VERSION "dbc-export 1 2026.26.6.5"

NS_ :

BS_:

BU_: ADSP APB APP APS APSB BB BMS CC CMP CMPD CP DAS DI DIF DIR DPB EPAS3P EPAS3S EPASTP EPASTS EPBL EPBR ESP EVSE FC GTW HCML HCMR HVP IBST ICR IDB LS OCS1P PARK PCS PCS2 PM PMF PMR PNCD PTC RADC RCM RCM2 RCM3 RCU SCCM SCM SCS SDCR TAS TCU TCU2 TPMS TRCM UI UIS UMC USM V2G VC VCBATT VCBATT0 VCBATT1 VCBATT2 VCCC VCFRONT VCFRONT1 VCFRONT2 VCLEFT VCRIGHT VCSEAT2L VCSEAT2R VCSEC VEH

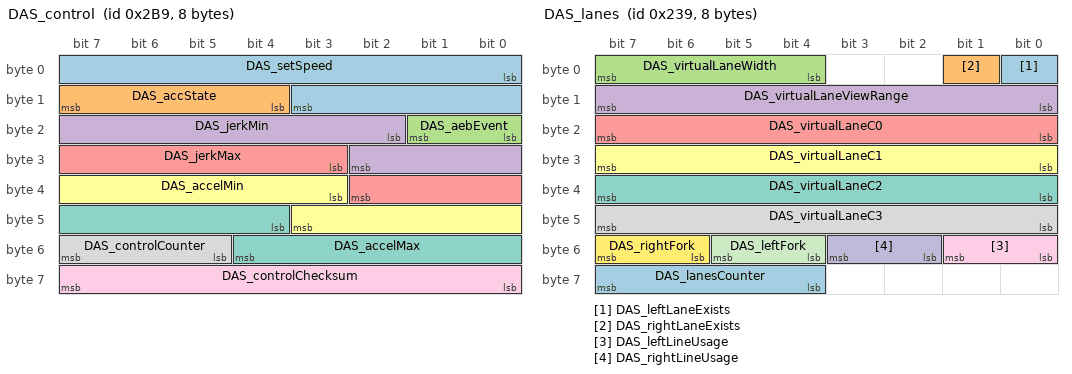
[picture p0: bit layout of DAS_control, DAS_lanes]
BO_ 697 DAS_control: 8 DAS
 SG_ DAS_setSpeed : 0|12@1+ (0.1,0) [0|409.4] "kph" Vector__XXX
 SG_ DAS_accState : 12|4@1+ (1,0) [0|15] "" Vector__XXX
 SG_ DAS_aebEvent : 16|2@1+ (1,0) [0|3] "" Vector__XXX
 SG_ DAS_jerkMin : 18|9@1+ (0.03,-15.232) [-15.232|0.098] "m/s^3" Vector__XXX
 SG_ DAS_jerkMax : 27|8@1+ (0.059,0) [0|15.045] "m/s^3" Vector__XXX
 SG_ DAS_accelMin : 35|9@1+ (0.04,-15) [-15|5.44] "m/s^2" Vector__XXX
 SG_ DAS_accelMax : 44|9@1+ (0.04,-15) [-15|5.44] "m/s^2" Vector__XXX
 SG_ DAS_controlCounter : 53|3@1+ (1,0) [0|7] "" Vector__XXX
 SG_ DAS_controlChecksum : 56|8@1+ (1,0) [0|255] "" Vector__XXX

BO_ 2040 DAS_gpsStatus: 8 DAS
 SG_ DAS_gpsStatusMultiplexer M : 0|4@1+ (1,0) [0|15] "" Vector__XXX
 SG_ DAS_gpsTransportModeState m0 : 4|1@1+ (1,0) [0|1] "" Vector__XXX
 SG_ DAS_gpsSatsInUseHardware m0 : 5|4@1+ (1,0) [0|15] "" Vector__XXX
 SG_ DAS_gpsRejectingSatData m0 : 57|1@1+ (1,0) [0|1] "" Vector__XXX
 SG_ DAS_gpsWheelsOffMotionDetected m0 : 58|1@1+ (1,0) [0|1] "" Vector__XXX
 SG_ DAS_gpsFixTypeHardware m0 : 59|3@1+ (1,0) [0|7] "" Vector__XXX
 SG_ DAS_gpsRawxEnabled m0 : 62|1@1+ (1,0) [0|1] "" Vector__XXX
 SG_ DAS_gpsRxmRawxMia m1 : 4|1@1+ (1,0) [0|1] "" Vector__XXX
 SG_ DAS_gpsRxmSfrbxMia m1 : 5|1@1+ (1,0) [0|1] "" Vector__XXX
 SG_ DAS_gpsEsfMeasMia m1 : 6|1@1+ (1,0) [0|1] "" Vector__XXX
 SG_ DAS_gpsEsfRawMia m1 : 7|1@1+ (1,0) [0|1] "" Vector__XXX
 SG_ DAS_gpsNavStatusMia m1 : 8|1@1+ (1,0) [0|1] "" Vector__XXX
 SG_ DAS_gpsSoftwareConfigured m1 : 9|1@1+ (1,0) [0|1] "" Vector__XXX
 SG_ DAS_gpsSoftwareUsed m1 : 10|1@1+ (1,0) [0|1] "" Vector__XXX
 SG_ DAS_gpsSoftwareFastStartReady m1 : 11|1@1+ (1,0) [0|1] "" Vector__XXX
 SG_ DAS_gpsSatsInUseSoftware m1 : 12|4@1+ (1,0) [0|15] "" Vector__XXX
 SG_ DAS_gpsFixTypeSoftware m1 : 16|3@1+ (1,0) [0|7] "" Vector__XXX
 SG_ DAS_gpsCWJammingInidcator m1 : 19|5@1+ (8,0) [0|248] "-" Vector__XXX
 SG_ DAS_gpsJammingState m1 : 24|2@1+ (1,0) [0|3] "" Vector__XXX
 SG_ DAS_gpsSpoofDetectorState m1 : 26|2@1+ (1,0) [0|3] "" Vector__XXX
 SG_ DAS_gpsInvalidMsgPercentage m1 : 28|4@1+ (6,0) [0|90] "%" Vector__XXX
 SG_ DAS_gnssConstellationsState m1 : 32|2@1+ (1,0) [0|3] "" Vector__XXX
 SG_ DAS_gpsReceiverNoiseLevel m1 : 34|6@1+ (8,0) [0|504] "-" Vector__XXX
 SG_ DAS_gpsAutomaticGainControl m1 : 40|8@1+ (32,0) [0|8160] "-" Vector__XXX
 SG_ DAS_gpsPreviousPositionDeltaHw m1 : 48|6@1+ (3,0) [0|189] "m" Vector__XXX
 SG_ DAS_gpsPreviousPositionDeltaSw m1 : 54|6@1+ (3,0) [0|189] "m" Vector__XXX
 SG_ DAS_gpsNmeaDispatchFailureCount m1 : 60|4@1+ (5,0) [0|75] "-" Vector__XXX
 SG_ DAS_gnssMaxInstantaneousCnorGps m2 : 4|6@1+ (1,0) [0|63] "" Vector__XXX
 SG_ DAS_gnssMaxInstantaneousCnorGal m2 : 10|6@1+ (1,0) [0|63] "" Vector__XXX
 SG_ DAS_gnssMaxInstantaneousCnorBds m2 : 16|6@1+ (1,0) [0|63] "" Vector__XXX
 SG_ DAS_gpsResetReason m2 : 22|4@1+ (1,0) [0|15] "" Vector__XXX
 SG_ DAS_gpsAccuracyHorizontal m2 : 26|6@1+ (1,0) [0|63] "m" Vector__XXX
 SG_ DAS_gpsAccuracyVertical m2 : 32|6@1+ (1,0) [0|63] "m" Vector__XXX
 SG_ DAS_gpsSolutionFallback m2 : 38|1@1+ (1,0) [0|1] "" Vector__XXX
 SG_ DAS_gpsToMcuSource m2 : 39|3@1+ (1,0) [0|7] "" Vector__XXX
 SG_ DAS_gpsSolutionSoc m2 : 42|2@1+ (1,0) [0|3] "" Vector__XXX
 SG_ DAS_gpsRedundancyActive m2 : 44|1@1+ (1,0) [0|1] "" Vector__XXX
 SG_ DAS_gpsFixTypeSoftwareSocB m2 : 45|3@1+ (1,0) [0|7] "" Vector__XXX
 SG_ DAS_gpsSatsInUseSoftwareSocB m2 : 48|4@1+ (1,0) [0|15] "" Vector__XXX
 SG_ DAS_gnssNumSatsGps m3 : 4|4@1+ (1,0) [0|15] "" Vector__XXX
 SG_ DAS_gnssNumSatsGal m3 : 8|4@1+ (1,0) [0|15] "" Vector__XXX
 SG_ DAS_gnssNumSatsBds m3 : 12|4@1+ (1,0) [0|15] "" Vector__XXX
 SG_ DAS_gnssAvgInstantaneousCnorGps m3 : 16|6@1+ (1,0) [0|63] "" Vector__XXX
 SG_ DAS_gnssAvgInstantaneousCnorGal m3 : 22|6@1+ (1,0) [0|63] "" Vector__XXX
 SG_ DAS_gnssAvgInstantaneousCnorBds m3 : 28|6@1+ (1,0) [0|63] "" Vector__XXX
 SG_ DAS_gnssAvgInstantaneousCnorGpsL m3 : 46|6@1+ (1,0) [0|63] "" Vector__XXX
 SG_ DAS_gnssAvgInstantaneousCnorGalL m3 : 52|6@1+ (1,0) [0|63] "" Vector__XXX
 SG_ DAS_gnssAvgInstantaneousCnorBdsL m3 : 58|6@1+ (1,0) [0|63] "" Vector__XXX

BO_ 1337 DAS_info: 8 DAS
 SG_ DAS_infoIndex M : 0|8@1+ (1,0) [0|255] "" Vector__XXX
 SG_ DAS_infoBuildType m10 : 8|8@1+ (1,0) [0|255] "" Vector__XXX
 SG_ DAS_infoBuildConfigID m10 : 16|16@1+ (1,0) [0|65535] "" Vector__XXX
 SG_ DAS_infoHardwareID m10 : 32|16@1+ (1,0) [0|65535] "" Vector__XXX
 SG_ DAS_infoComponentID m10 : 48|16@1+ (1,0) [0|65535] "" Vector__XXX
 SG_ DAS_infoPcbaID m11 : 16|8@1+ (1,0) [0|255] "" Vector__XXX
 SG_ DAS_infoAssemblyID m11 : 24|8@1+ (1,0) [0|255] "" Vector__XXX
 SG_ DAS_infoUsageID m11 : 32|16@1+ (1,0) [0|65535] "" Vector__XXX
 SG_ DAS_infoSubUsageID m11 : 48|16@1+ (1,0) [0|65535] "" Vector__XXX
 SG_ DAS_infoApplicationCRC m13 : 32|32@1+ (1,0) [0|4294967295] "" Vector__XXX
 SG_ DAS_infoAppGitHashBytes m17 : 8|56@1+ (1,0) [0|7.20575940379e+16] "" Vector__XXX
 SG_ DAS_infoBootGitHashBytes m18 : 8|56@1+ (1,0) [0|7.20575940379e+16] "" Vector__XXX

BO_ 569 DAS_lanes: 8 DAS
 SG_ DAS_leftLaneExists : 0|1@1+ (1,0) [0|1] "" Vector__XXX
 SG_ DAS_rightLaneExists : 1|1@1+ (1,0) [0|1] "" Vector__XXX
 SG_ DAS_virtualLaneWidth : 4|4@1+ (0.3125,2) [2|6.6875] "m" Vector__XXX
 SG_ DAS_virtualLaneViewRange : 8|8@1+ (1,0) [0|160] "m" Vector__XXX
 SG_ DAS_virtualLaneC0 : 16|8@1+ (0.035,-3.5) [-3.5|3.5] "m" Vector__XXX
 SG_ DAS_virtualLaneC1 : 24|8@1+ (0.0016,-0.2) [-0.2|0.2] "rad" Vector__XXX
 SG_ DAS_virtualLaneC2 : 32|8@1+ (2.0e-05,-0.0025) [-0.0025|0.0025] "m-1" Vector__XXX
 SG_ DAS_virtualLaneC3 : 40|8@1+ (2.4e-07,-3.0e-05) [-3.0e-05|3.0e-05] "m-2" Vector__XXX
 SG_ DAS_leftLineUsage : 48|2@1+ (1,0) [0|3] "" Vector__XXX
 SG_ DAS_rightLineUsage : 50|2@1+ (1,0) [0|3] "" Vector__XXX
 SG_ DAS_leftFork : 52|2@1+ (1,0) [0|3] "" Vector__XXX
 SG_ DAS_rightFork : 54|2@1+ (1,0) [0|3] "" Vector__XXX
 SG_ DAS_lanesCounter : 60|4@1+ (1,0) [0|15] "" Vector__XXX

BO_ 778 DAS_object: 8 DAS
 SG_ DAS_objectId M : 0|3@1+ (1,0) [0|7] "" Vector__XXX
 SG_ DAS_leadVehType m0 : 3|3@1+ (1,0) [0|7] "" Vector__XXX
 SG_ DAS_leadVehRelevantForControl m0 : 7|1@1+ (1,0) [0|1] "" Vector__XXX
 SG_ DAS_leadVehDx m0 : 8|8@1+ (0.5,0) [0|127] "m" Vector__XXX
 SG_ DAS_leadVehVxRel m0 : 16|4@1+ (4,-30) [-30|26] "m/s" Vector__XXX
 SG_ DAS_leadVehDy m0 : 20|7@1+ (0.35,-22.05) [-22.05|22.4] "m" Vector__XXX
 SG_ DAS_leadVehId m0 : 27|7@1+ (1,0) [0|127] "" Vector__XXX
 SG_ DAS_leadVeh2Type m0 : 34|3@1+ (1,0) [0|7] "" Vector__XXX
 SG_ DAS_leadVeh2RelevantForControl m0 : 38|1@1+ (1,0) [0|1] "" Vector__XXX
 SG_ DAS_leadVeh2Dx m0 : 39|8@1+ (0.5,0) [0|127] "m" Vector__XXX
 SG_ DAS_leadVeh2VxRel m0 : 47|4@1+ (4,-30) [-30|26] "m/s" Vector__XXX
 SG_ DAS_leadVeh2Dy m0 : 51|7@1+ (0.35,-22.05) [-22.05|22.4] "m" Vector__XXX
 SG_ DAS_leadVeh2Id m0 : 58|6@1+ (1,0) [0|63] "" Vector__XXX
 SG_ DAS_leftVehType m1 : 3|3@1+ (1,0) [0|7] "" Vector__XXX
 SG_ DAS_leftVehRelevantForControl m1 : 7|1@1+ (1,0) [0|1] "" Vector__XXX
 SG_ DAS_leftVehDx m1 : 8|8@1+ (0.5,0) [0|127] "m" Vector__XXX
 SG_ DAS_leftVehVxRel m1 : 16|4@1+ (4,-30) [-30|26] "m/s" Vector__XXX
 SG_ DAS_leftVehDy m1 : 20|7@1+ (0.35,-22.05) [-22.05|22.4] "m" Vector__XXX
 SG_ DAS_leftVehId m1 : 27|7@1+ (1,0) [0|127] "" Vector__XXX
 SG_ DAS_leftVeh2Type m1 : 34|3@1+ (1,0) [0|7] "" Vector__XXX
 SG_ DAS_leftVeh2RelevantForControl m1 : 38|1@1+ (1,0) [0|1] "" Vector__XXX
 SG_ DAS_leftVeh2Dx m1 : 39|8@1+ (0.5,0) [0|127] "m" Vector__XXX
 SG_ DAS_leftVeh2VxRel m1 : 47|4@1+ (4,-30) [-30|26] "m/s" Vector__XXX
 SG_ DAS_leftVeh2Dy m1 : 51|7@1+ (0.35,-22.05) [-22.05|22.4] "m" Vector__XXX
 SG_ DAS_leftVeh2Id m1 : 58|6@1+ (1,0) [0|63] "" Vector__XXX
 SG_ DAS_rightVehType m2 : 3|3@1+ (1,0) [0|7] "" Vector__XXX
 SG_ DAS_rightVehRelevantForControl m2 : 7|1@1+ (1,0) [0|1] "" Vector__XXX
 SG_ DAS_rightVehDx m2 : 8|8@1+ (0.5,0) [0|127] "m" Vector__XXX
 SG_ DAS_rightVehVxRel m2 : 16|4@1+ (4,-30) [-30|26] "m/s" Vector__XXX
 SG_ DAS_rightVehDy m2 : 20|7@1+ (0.35,-22.05) [-22.05|22.4] "m" Vector__XXX
 SG_ DAS_rightVehId m2 : 27|7@1+ (1,0) [0|127] "" Vector__XXX
 SG_ DAS_rightVeh2Type m2 : 34|3@1+ (1,0) [0|7] "" Vector__XXX
 SG_ DAS_rightVeh2RelevantForControl m2 : 38|1@1+ (1,0) [0|1] "" Vector__XXX
 SG_ DAS_rightVeh2Dx m2 : 39|8@1+ (0.5,0) [0|127] "m" Vector__XXX
 SG_ DAS_rightVeh2VxRel m2 : 47|4@1+ (4,-30) [-30|26] "m/s" Vector__XXX
 SG_ DAS_rightVeh2Dy m2 : 51|7@1+ (0.35,-22.05) [-22.05|22.4] "m" Vector__XXX
 SG_ DAS_rightVeh2Id m2 : 58|6@1+ (1,0) [0|63] "" Vector__XXX
 SG_ DAS_cutinVehType m3 : 3|3@1+ (1,0) [0|7] "" Vector__XXX
 SG_ DAS_cutinVehRelevantForControl m3 : 7|1@1+ (1,0) [0|1] "" Vector__XXX
 SG_ DAS_cutinVehDx m3 : 8|8@1+ (0.5,0) [0|127] "m" Vector__XXX
 SG_ DAS_cutinVehVxRel m3 : 16|4@1+ (4,-30) [-30|26] "m/s" Vector__XXX
 SG_ DAS_cutinVehDy m3 : 20|7@1+ (0.35,-22.05) [-22.05|22.4] "m" Vector__XXX
 SG_ DAS_cutinVehId m3 : 27|7@1+ (1,0) [0|127] "" Vector__XXX
 SG_ DAS_roadSignColor m4 : 3|3@1+ (1,0) [0|7] "" Vector__XXX
 SG_ DAS_roadSignId m4 : 6|8@1+ (1,0) [0|255] "" Vector__XXX
 SG_ DAS_roadSignStopLineDist m4 : 14|10@1+ (0.2,-20) [-20|184.4] "m" Vector__XXX
 SG_ DAS_roadSignControlActive m4 : 24|1@1+ (1,0) [0|1] "" Vector__XXX
 SG_ DAS_roadSignSource m4 : 25|2@1+ (1,0) [0|3] "" Vector__XXX
 SG_ DAS_roadSignArrow m4 : 27|3@1+ (1,0) [0|7] "" Vector__XXX
 SG_ DAS_roadSignOrientation m4 : 30|2@1+ (1,0) [0|3] "" Vector__XXX

BO_ 781 DAS_positioningEngineStatus: 8 DAS
 SG_ DAS_positioningEngineStatusMulti M : 0|4@1+ (1,0) [0|15] "" Vector__XXX
 SG_ DAS_meoSolverNumRuns m2 : 4|2@1+ (1,0) [0|3] "" Vector__XXX
 SG_ DAS_meoSolverReportTerminationTy m2 : 6|3@1+ (1,0) [0|7] "" Vector__XXX
 SG_ DAS_meoSolverReportTotalTimeS m2 : 9|3@1+ (1,0) [0|7] "" Vector__XXX
 SG_ DAS_meoHorizontalAccuracyM m2 : 12|6@1+ (1,0) [0|63] "m" Vector__XXX
 SG_ DAS_meoVerticalAccuracyM m2 : 18|6@1+ (1,0) [0|63] "m" Vector__XXX
 SG_ DAS_meoHeadingAccuracyDeg m2 : 24|3@1+ (1,0) [0|7] "deg" Vector__XXX
 SG_ DAS_meoHeadingValid m2 : 27|1@1+ (1,0) [0|1] "" Vector__XXX
 SG_ DAS_meoNumSatellitesUsed m2 : 28|5@1+ (1,0) [0|31] "" Vector__XXX
 SG_ DAS_meoGpsQualityLevel m2 : 33|3@1+ (1,0) [0|7] "" Vector__XXX
 SG_ DAS_meoFixType m2 : 36|3@1+ (1,0) [0|7] "" Vector__XXX
 SG_ DAS_meoResetCount m2 : 39|3@1+ (1,0) [0|7] "" Vector__XXX
 SG_ DAS_lastMeoResetReason m2 : 42|2@1+ (1,0) [0|3] "" Vector__XXX
 SG_ DAS_vioMultiGpsSelectedSource m3 : 4|3@1+ (1,0) [0|7] "" Vector__XXX
 SG_ DAS_vioMultiGpsPeCooldownActive m3 : 7|1@1+ (1,0) [0|1] "" Vector__XXX
 SG_ DAS_vioMultiGpsPeSppTdcpConsiste m3 : 8|1@1+ (1,0) [0|1] "" Vector__XXX
 SG_ DAS_vioMultiGpsPeMeoConsistentWi m3 : 9|1@1+ (1,0) [0|1] "" Vector__XXX
 SG_ DAS_vioMultiGpsPeSppTdcpVsR_0001 m3 : 10|4@1+ (1,0) [0|15] "m" Vector__XXX
 SG_ DAS_vioMultiGpsPeMeoVsRawGpsTran m3 : 14|4@1+ (1,0) [0|15] "m" Vector__XXX
 SG_ DAS_vioMultiGpsPeSppTdcpVsRawGps m3 : 18|3@1+ (1,0) [0|7] "deg" Vector__XXX
 SG_ DAS_vioMultiGpsPeMeoVsRawGpsRotD m3 : 21|3@1+ (1,0) [0|7] "deg" Vector__XXX
 SG_ DAS_publishedGpsSource m3 : 24|2@1+ (1,0) [0|3] "" Vector__XXX
 SG_ DAS_bluefinEnabled m3 : 26|1@1+ (1,0) [0|1] "" Vector__XXX
 SG_ DAS_orioleDisabled m3 : 27|1@1+ (1,0) [0|1] "" Vector__XXX
 SG_ DAS_disableMonarch m3 : 28|1@1+ (1,0) [0|1] "" Vector__XXX

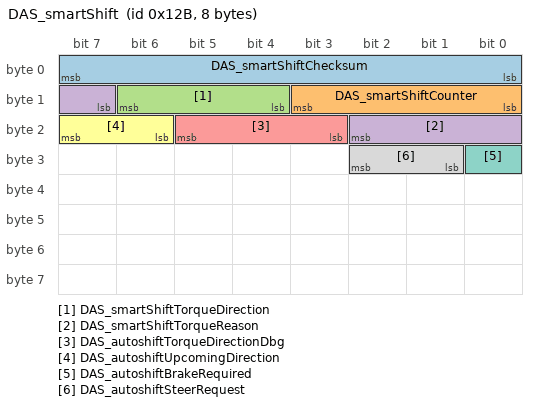
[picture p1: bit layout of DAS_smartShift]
BO_ 299 DAS_smartShift: 8 DAS
 SG_ DAS_smartShiftChecksum : 0|8@1+ (1,0) [0|255] "" Vector__XXX
 SG_ DAS_smartShiftCounter : 8|4@1+ (1,0) [0|15] "" Vector__XXX
 SG_ DAS_smartShiftTorqueDirection : 12|3@1+ (1,0) [0|7] "" Vector__XXX
 SG_ DAS_smartShiftTorqueReason : 15|4@1+ (1,0) [0|15] "" Vector__XXX
 SG_ DAS_autoshiftTorqueDirectionDbg : 19|3@1+ (1,0) [0|7] "" Vector__XXX
 SG_ DAS_autoshiftUpcomingDirection : 22|2@1+ (1,0) [0|3] "" Vector__XXX
 SG_ DAS_autoshiftBrakeRequired : 24|1@1+ (1,0) [0|1] "" Vector__XXX
 SG_ DAS_autoshiftSteerRequest : 25|2@1+ (1,0) [0|3] "" Vector__XXX

BO_ 921 DAS_status: 8 DAS
 SG_ DAS_autopilotState : 0|4@1+ (1,0) [0|15] "" Vector__XXX
 SG_ DAS_blindSpotRearLeft : 4|2@1+ (1,0) [0|3] "" Vector__XXX
 SG_ DAS_blindSpotRearRight : 6|2@1+ (1,0) [0|3] "" Vector__XXX
 SG_ DAS_fusedSpeedLimit : 8|5@1+ (5,0) [0|150] "kph/mph" Vector__XXX
 SG_ DAS_suppressSpeedWarning : 13|1@1+ (1,0) [0|1] "" Vector__XXX
 SG_ DAS_summonObstacle : 14|1@1+ (1,0) [0|1] "" Vector__XXX
 SG_ DAS_summonClearedGate : 15|1@1+ (1,0) [0|1] "" Vector__XXX
 SG_ DAS_visionOnlySpeedLimit : 16|5@1+ (5,0) [0|150] "kph/mph" Vector__XXX
 SG_ DAS_heaterState : 21|1@1+ (1,0) [0|1] "" Vector__XXX
 SG_ DAS_forwardCollisionWarning : 22|2@1+ (1,0) [0|3] "" Vector__XXX
 SG_ DAS_autoparkReady : 24|1@1+ (1,0) [0|1] "" Vector__XXX
 SG_ DAS_autoParked : 25|1@1+ (1,0) [0|1] "" Vector__XXX
 SG_ DAS_autoparkActive : 26|1@1+ (1,0) [0|1] "" Vector__XXX
 SG_ DAS_summonFwdLeashReached : 27|1@1+ (1,0) [0|1] "" Vector__XXX
 SG_ DAS_summonRvsLeashReached : 28|1@1+ (1,0) [0|1] "" Vector__XXX
 SG_ DAS_lssState : 29|3@1+ (1,0) [0|7] "" Vector__XXX
 SG_ DAS_sideCollisionAvoid : 32|2@1+ (1,0) [0|3] "" Vector__XXX
 SG_ DAS_sideCollisionWarning : 34|2@1+ (1,0) [0|3] "" Vector__XXX
 SG_ DAS_sideCollisionInhibit : 36|1@1+ (1,0) [0|1] "" Vector__XXX
 SG_ DAS_laneDepartureWarning : 37|3@1+ (1,0) [0|7] "" Vector__XXX
 SG_ DAS_fleetSpeedState : 40|2@1+ (1,0) [0|3] "" Vector__XXX
 SG_ DAS_autopilotHandsOnState : 42|4@1+ (1,0) [0|15] "" Vector__XXX
 SG_ DAS_autoLaneChangeState : 46|5@1+ (1,0) [0|31] "" Vector__XXX
 SG_ DAS_summonAvailable : 51|1@1+ (1,0) [0|1] "" Vector__XXX
 SG_ DAS_statusCounter : 52|4@1+ (1,0) [0|15] "" Vector__XXX
 SG_ DAS_statusChecksum : 56|8@1+ (1,0) [0|255] "" Vector__XXX

BO_ 905 DAS_status2: 8 DAS
 SG_ DAS_accSpeedLimit : 0|9@1+ (0.4,0) [0|200] "mph" Vector__XXX
 SG_ DAS_versionIdentifier : 9|1@1+ (1,0) [0|1] "" Vector__XXX
 SG_ DAS_pmmObstacleSeverity : 10|3@1+ (1,0) [0|7] "" Vector__XXX
 SG_ DAS_pmmLoggingRequest : 13|1@1+ (1,0) [0|1] "" Vector__XXX
 SG_ DAS_activationFailureStatus : 14|2@1+ (1,0) [0|3] "" Vector__XXX
 SG_ DAS_pmmUltrasonicsFaultReason : 16|3@1+ (1,0) [0|7] "" Vector__XXX
 SG_ DAS_pmmRadarFaultReason : 19|2@1+ (1,0) [0|3] "" Vector__XXX
 SG_ DAS_pmmSysFaultReason : 21|3@1+ (1,0) [0|7] "" Vector__XXX
 SG_ DAS_pmmCameraFaultReason : 24|2@1+ (1,0) [0|3] "" Vector__XXX
 SG_ DAS_ACC_report : 26|5@1+ (1,0) [0|31] "" Vector__XXX
 SG_ DAS_relaxCruiseLimits : 31|1@1+ (1,0) [0|1] "" Vector__XXX
 SG_ DAS_csaState : 32|2@1+ (1,0) [0|3] "" Vector__XXX
 SG_ DAS_radarTelemetry : 34|2@1+ (1,0) [0|3] "" Vector__XXX
 SG_ DAS_robState : 36|2@1+ (1,0) [0|3] "" Vector__XXX
 SG_ DAS_driverInteractionLevel : 38|2@1+ (1,0) [0|3] "" Vector__XXX
 SG_ DAS_ppOffsetDesiredRamp : 40|8@1+ (0.01,-1.28) [-1.28|1.27] "m" Vector__XXX
 SG_ DAS_longCollisionWarning : 48|4@1+ (1,0) [0|15] "" Vector__XXX
 SG_ DAS_status2Counter : 52|4@1+ (1,0) [0|15] "" Vector__XXX
 SG_ DAS_status2Checksum : 56|8@1+ (1,0) [0|255] "" Vector__XXX

BO_ 1548 DAS_telemetryRadar: 8 DAS
 SG_ DAS_TR_ObjIndex M : 0|5@1+ (1,0) [0|31] "" Vector__XXX
 SG_ DAS_TR_Counter : 54|2@1+ (1,0) [0|3] "" Vector__XXX
 SG_ DAS_TR_Obj00_Class m0 : 5|3@1+ (1,0) [0|7] "" Vector__XXX
 SG_ DAS_TR_Obj00_Dx m0 : 8|10@1+ (0.15625,0) [0|159.84375] "m" Vector__XXX
 SG_ DAS_TR_Obj00_Dy m0 : 18|6@1+ (0.5,-15.5) [-15.5|16] "m" Vector__XXX
 SG_ DAS_TR_Obj00_Vx m0 : 24|8@1+ (0.5,-63.5) [-63.5|64] "m/s" Vector__XXX
 SG_ DAS_TR_Obj00_RCS m0 : 32|8@1+ (0.25,-14) [-14|49.75] "dB" Vector__XXX
 SG_ DAS_TR_Obj00_Length m0 : 40|6@1+ (0.125,0) [0|7.875] "m" Vector__XXX
 SG_ DAS_TR_Obj00_MovingState m0 : 46|2@1+ (1,0) [0|3] "" Vector__XXX
 SG_ DAS_TR_Obj00_Dz m0 : 48|6@1+ (0.25,-5) [-5|10.75] "m" Vector__XXX
 SG_ DAS_TR_Obj00_Exist m0 : 56|5@1+ (3.125,0) [0|96.875] "%" Vector__XXX

BO_ 586 DAS_visualDebug: 8 DAS
 SG_ DAS_autosteerVehiclesUsage : 4|2@1+ (1,0) [0|3] "" Vector__XXX
 SG_ DAS_autosteerHPPUsage : 6|2@1+ (1,0) [0|3] "" Vector__XXX
 SG_ DAS_autosteerNavigationUsage : 8|2@1+ (1,0) [0|3] "" Vector__XXX
 SG_ DAS_autosteerModelUsage : 10|2@1+ (1,0) [0|3] "" Vector__XXX
 SG_ DAS_autosteerBottsDotsUsage : 12|2@1+ (1,0) [0|3] "" Vector__XXX
 SG_ DAS_offsetSide : 14|2@1+ (1,0) [0|3] "" Vector__XXX
 SG_ DAS_roadSurfaceType : 16|2@1+ (1,0) [0|3] "" Vector__XXX
 SG_ DAS_autosteerHealthAnomalyLevel : 18|3@1+ (1,0) [0|7] "" Vector__XXX
 SG_ DAS_autosteerHealthState : 21|3@1+ (1,0) [0|7] "" Vector__XXX
 SG_ DAS_lastLinePreferenceReason : 24|4@1+ (1,0) [0|15] "" Vector__XXX
 SG_ DAS_plannerState : 28|4@1+ (1,0) [0|15] "" Vector__XXX
 SG_ DAS_lastAutosteerAbortReason : 32|6@1+ (1,0) [0|63] "" Vector__XXX
 SG_ DAS_devAppInterfaceEnabled : 38|1@1+ (1,0) [0|1] "" Vector__XXX
 SG_ DAS_navAvailable : 39|1@1+ (1,0) [0|1] "" Vector__XXX
 SG_ DAS_navDistance : 40|8@1+ (100,0) [0|25500] "km" Vector__XXX
 SG_ DAS_accSmartSpeedActive : 48|1@1+ (1,0) [0|1] "" Vector__XXX
 SG_ DAS_accSmartSpeedState : 49|3@1+ (1,0) [0|7] "" Vector__XXX
 SG_ DAS_ulcInProgress : 52|1@1+ (1,0) [0|1] "" Vector__XXX
 SG_ DAS_trafficAwareSetSpeedInUse : 53|1@1+ (1,0) [0|1] "" Vector__XXX
 SG_ DAS_isaSystemState : 54|2@1+ (1,0) [0|3] "" Vector__XXX
 SG_ DAS_behaviorType : 56|2@1+ (1,0) [0|3] "" Vector__XXX
 SG_ DAS_ulcType : 58|2@1+ (1,0) [0|3] "" Vector__XXX
 SG_ DAS_rearVehDetectedThisCycle : 60|1@1+ (1,0) [0|1] "" Vector__XXX
 SG_ DAS_rearLeftVehDetectedCurrent : 61|1@1+ (1,0) [0|1] "" Vector__XXX
 SG_ DAS_rearRightVehDetectedTrip : 62|1@1+ (1,0) [0|1] "" Vector__XXX
 SG_ DAS_rearLeftVehDetectedTrip : 63|1@1+ (1,0) [0|1] "" Vector__XXX

BO_ 2039 DAS_warningMatrix0: 8 DAS
 SG_ DAS_w002_ldwDisabled : 1|1@1+ (1,0) [0|1] "" Vector__XXX
 SG_ DAS_w003_isaDisabled : 2|1@1+ (1,0) [0|1] "" Vector__XXX
 SG_ DAS_w004_accDisabled : 3|1@1+ (1,0) [0|1] "" Vector__XXX
 SG_ DAS_w005_fcwCancelled : 4|1@1+ (1,0) [0|1] "" Vector__XXX
 SG_ DAS_w006_aebCancelled : 5|1@1+ (1,0) [0|1] "" Vector__XXX
 SG_ DAS_w007_ahlbDisabled : 6|1@1+ (1,0) [0|1] "" Vector__XXX
 SG_ DAS_w008_parkDisabled : 7|1@1+ (1,0) [0|1] "" Vector__XXX
 SG_ DAS_w009_aebFault : 8|1@1+ (1,0) [0|1] "" Vector__XXX
 SG_ DAS_w010_radcCalibIssue : 9|1@1+ (1,0) [0|1] "" Vector__XXX
 SG_ DAS_w011_scaEvent : 10|1@1+ (1,0) [0|1] "" Vector__XXX
 SG_ DAS_w012_Cam_BootFailure : 11|1@1+ (1,0) [0|1] "" Vector__XXX
 SG_ DAS_w013_Cam_Watchdog : 12|1@1+ (1,0) [0|1] "" Vector__XXX
 SG_ DAS_w014_swAssert : 13|1@1+ (1,0) [0|1] "" Vector__XXX
 SG_ DAS_w015_Camera_Failsafes : 14|1@1+ (1,0) [0|1] "" Vector__XXX
 SG_ DAS_w016_aeb_e_event : 15|1@1+ (1,0) [0|1] "" Vector__XXX
 SG_ DAS_w017_Cam_Msg_MIA : 16|1@1+ (1,0) [0|1] "" Vector__XXX
 SG_ DAS_w018_ECU_Power_Issue : 17|1@1+ (1,0) [0|1] "" Vector__XXX
 SG_ DAS_w019_ECU_Stack_Overflow : 18|1@1+ (1,0) [0|1] "" Vector__XXX
 SG_ DAS_w020_ECU_checkstopError : 19|1@1+ (1,0) [0|1] "" Vector__XXX
 SG_ DAS_w021_ECU_Temperature_Issue : 20|1@1+ (1,0) [0|1] "" Vector__XXX
 SG_ DAS_w022_ECU_EEPROM_Failure : 21|1@1+ (1,0) [0|1] "" Vector__XXX
 SG_ DAS_w023_ECU_Cam_Statemismatc : 22|1@1+ (1,0) [0|1] "" Vector__XXX
 SG_ DAS_w024_ECU_Watchdog_Reset : 23|1@1+ (1,0) [0|1] "" Vector__XXX
 SG_ DAS_w025_LC_Steering_Override : 24|1@1+ (1,0) [0|1] "" Vector__XXX
 SG_ DAS_w026_ECU_timingIssue : 25|1@1+ (1,0) [0|1] "" Vector__XXX
 SG_ DAS_w027_ECU_Reset_Fault : 26|1@1+ (1,0) [0|1] "" Vector__XXX
 SG_ DAS_w028_spi_rx_error : 27|1@1+ (1,0) [0|1] "" Vector__XXX
 SG_ DAS_w029_spi_tx_error : 28|1@1+ (1,0) [0|1] "" Vector__XXX
 SG_ DAS_w030_Heater_Issue : 29|1@1+ (1,0) [0|1] "" Vector__XXX
 SG_ DAS_w031_canRxError : 30|1@1+ (1,0) [0|1] "" Vector__XXX
 SG_ DAS_w032_canTxError : 31|1@1+ (1,0) [0|1] "" Vector__XXX
 SG_ DAS_w033_gtwMia : 32|1@1+ (1,0) [0|1] "" Vector__XXX
 SG_ DAS_w034_sccmMia : 33|1@1+ (1,0) [0|1] "" Vector__XXX
 SG_ DAS_w035_espMia : 34|1@1+ (1,0) [0|1] "" Vector__XXX
 SG_ DAS_w036_bdyMia : 35|1@1+ (1,0) [0|1] "" Vector__XXX
 SG_ DAS_w037_camTacIssue : 36|1@1+ (1,0) [0|1] "" Vector__XXX
 SG_ DAS_w038_camFailure : 37|1@1+ (1,0) [0|1] "" Vector__XXX
 SG_ DAS_w039_sdm_rcm_Mia : 38|1@1+ (1,0) [0|1] "" Vector__XXX
 SG_ DAS_w040_autopilotAngleSaturated : 39|1@1+ (1,0) [0|1] "" Vector__XXX
 SG_ DAS_w041_autopilotRateSaturated : 40|1@1+ (1,0) [0|1] "" Vector__XXX
 SG_ DAS_w042_autopilotAborting : 41|1@1+ (1,0) [0|1] "" Vector__XXX
 SG_ DAS_w043_camLongRunTime : 42|1@1+ (1,0) [0|1] "" Vector__XXX
 SG_ DAS_w044_appMobileyeFailure : 43|1@1+ (1,0) [0|1] "" Vector__XXX
 SG_ DAS_w045_radMia : 44|1@1+ (1,0) [0|1] "" Vector__XXX
 SG_ DAS_w046_eepromRecordAbsent : 45|1@1+ (1,0) [0|1] "" Vector__XXX
 SG_ DAS_w047_edrEvent : 46|1@1+ (1,0) [0|1] "" Vector__XXX
 SG_ DAS_w048_DAS_Features_Disabled : 47|1@1+ (1,0) [0|1] "" Vector__XXX
 SG_ DAS_w049_eyeqVersionMismatch : 48|1@1+ (1,0) [0|1] "" Vector__XXX
 SG_ DAS_w050_aeb_event : 49|1@1+ (1,0) [0|1] "" Vector__XXX
 SG_ DAS_w051_radcEcuIssue : 50|1@1+ (1,0) [0|1] "" Vector__XXX
 SG_ DAS_w052_radcSensorIssue : 51|1@1+ (1,0) [0|1] "" Vector__XXX
 SG_ DAS_w053_radcCommIssue : 52|1@1+ (1,0) [0|1] "" Vector__XXX
 SG_ DAS_w054_camAutofix : 53|1@1+ (1,0) [0|1] "" Vector__XXX
 SG_ DAS_w055_radcVersionMismatch : 54|1@1+ (1,0) [0|1] "" Vector__XXX
 SG_ DAS_w056_diMia : 55|1@1+ (1,0) [0|1] "" Vector__XXX
 SG_ DAS_w057_mcuMia : 56|1@1+ (1,0) [0|1] "" Vector__XXX
 SG_ DAS_w058_epbMia : 57|1@1+ (1,0) [0|1] "" Vector__XXX
 SG_ DAS_w059_parkMia : 58|1@1+ (1,0) [0|1] "" Vector__XXX
 SG_ DAS_w060_fcw_event : 59|1@1+ (1,0) [0|1] "" Vector__XXX
 SG_ DAS_w061_airSuspensionMia : 60|1@1+ (1,0) [0|1] "" Vector__XXX
 SG_ DAS_w062_radcAlignment : 61|1@1+ (1,0) [0|1] "" Vector__XXX
 SG_ DAS_w063_parkVersionMismatch : 62|1@1+ (1,0) [0|1] "" Vector__XXX
 SG_ DAS_w064_epasMia : 63|1@1+ (1,0) [0|1] "" Vector__XXX

BO_ 874 DAS_warningMatrix1: 8 DAS
 SG_ DAS_w065_deserializerOvercurrent : 0|1@1+ (1,0) [0|1] "" Vector__XXX
 SG_ DAS_w066_deserializerLockLost : 1|1@1+ (1,0) [0|1] "" Vector__XXX
 SG_ DAS_w067_steeringAlignment : 2|1@1+ (1,0) [0|1] "" Vector__XXX
 SG_ DAS_w068_vlInconsistency : 3|1@1+ (1,0) [0|1] "" Vector__XXX
 SG_ DAS_w069_apcSpaceMasked : 4|1@1+ (1,0) [0|1] "" Vector__XXX
 SG_ DAS_w070_apcIncompleteCal : 5|1@1+ (1,0) [0|1] "" Vector__XXX
 SG_ DAS_w071_selfparkStarted : 6|1@1+ (1,0) [0|1] "" Vector__XXX
 SG_ DAS_w072_selfparkComplete : 7|1@1+ (1,0) [0|1] "" Vector__XXX
 SG_ DAS_w073_issueEscalatedLDW : 8|1@1+ (1,0) [0|1] "" Vector__XXX
 SG_ DAS_w074_inPathStationaryObst : 9|1@1+ (1,0) [0|1] "" Vector__XXX
 SG_ DAS_w075_scMia : 10|1@1+ (1,0) [0|1] "" Vector__XXX
 SG_ DAS_w076_mobilEyeSetC : 11|1@1+ (1,0) [0|1] "" Vector__XXX
 SG_ DAS_w077_pmmActive : 12|1@1+ (1,0) [0|1] "" Vector__XXX
 SG_ DAS_w078_pmmActive2 : 13|1@1+ (1,0) [0|1] "" Vector__XXX
 SG_ DAS_w079_edrAvailable : 14|1@1+ (1,0) [0|1] "" Vector__XXX
 SG_ DAS_w080_accFailedActivation : 15|1@1+ (1,0) [0|1] "" Vector__XXX
 SG_ DAS_w081_pmmActiveBraking : 16|1@1+ (1,0) [0|1] "" Vector__XXX
 SG_ DAS_w082_inPathFSviolation : 17|1@1+ (1,0) [0|1] "" Vector__XXX
 SG_ DAS_w083_inPathRADObject : 18|1@1+ (1,0) [0|1] "" Vector__XXX
 SG_ DAS_w084_pmmIPSO : 19|1@1+ (1,0) [0|1] "" Vector__XXX
 SG_ DAS_w085_pmmSteering : 20|1@1+ (1,0) [0|1] "" Vector__XXX
 SG_ DAS_w086_robCollision : 21|1@1+ (1,0) [0|1] "" Vector__XXX
 SG_ DAS_w087_DEPRECATED : 22|1@1+ (1,0) [0|1] "" Vector__XXX
 SG_ DAS_w088_DEPRECATED : 23|1@1+ (1,0) [0|1] "" Vector__XXX
 SG_ DAS_w089_DEPRECATED : 24|1@1+ (1,0) [0|1] "" Vector__XXX
 SG_ DAS_w090_DEPRECATED : 25|1@1+ (1,0) [0|1] "" Vector__XXX
 SG_ DAS_w091_DEPRECATED : 26|1@1+ (1,0) [0|1] "" Vector__XXX
 SG_ DAS_w092_DEPRECATED : 27|1@1+ (1,0) [0|1] "" Vector__XXX
 SG_ DAS_w093_DEPRECATED : 28|1@1+ (1,0) [0|1] "" Vector__XXX
 SG_ DAS_w094_DEPRECATED : 29|1@1+ (1,0) [0|1] "" Vector__XXX
 SG_ DAS_w095_DEPRECATED : 30|1@1+ (1,0) [0|1] "" Vector__XXX
 SG_ DAS_w096_DEPRECATED : 31|1@1+ (1,0) [0|1] "" Vector__XXX
 SG_ DAS_w097_DEPRECATED : 32|1@1+ (1,0) [0|1] "" Vector__XXX
 SG_ DAS_w098_DEPRECATED : 33|1@1+ (1,0) [0|1] "" Vector__XXX
 SG_ DAS_w099_DEPRECATED : 34|1@1+ (1,0) [0|1] "" Vector__XXX
 SG_ DAS_w100_DEPRECATED : 35|1@1+ (1,0) [0|1] "" Vector__XXX
 SG_ DAS_w101_DEPRECATED : 36|1@1+ (1,0) [0|1] "" Vector__XXX
 SG_ DAS_w102_DEPRECATED : 37|1@1+ (1,0) [0|1] "" Vector__XXX
 SG_ DAS_w103_robExperimentalAEB : 38|1@1+ (1,0) [0|1] "" Vector__XXX
 SG_ DAS_w104_DEPRECATED : 39|1@1+ (1,0) [0|1] "" Vector__XXX
 SG_ DAS_w105_DEPRECATED : 40|1@1+ (1,0) [0|1] "" Vector__XXX
 SG_ DAS_w106_torsionBarCalibrated : 41|1@1+ (1,0) [0|1] "" Vector__XXX

BO_ 841 DAS_warningMatrix2: 8 DAS
 SG_ DAS_w129_mainCamExtNotCal : 0|1@1+ (1,0) [0|1] "" Vector__XXX
 SG_ DAS_w130_narrowCamExtNotCal : 1|1@1+ (1,0) [0|1] "" Vector__XXX
 SG_ DAS_w131_mainCamCalSaved : 2|1@1+ (1,0) [0|1] "" Vector__XXX
 SG_ DAS_w132_narrowCamCalSaved : 3|1@1+ (1,0) [0|1] "" Vector__XXX
 SG_ DAS_w133_mainCamInitFault : 4|1@1+ (1,0) [0|1] "" Vector__XXX
 SG_ DAS_w134_narrowCamInitFault : 5|1@1+ (1,0) [0|1] "" Vector__XXX
 SG_ DAS_w135_fisheyeCamInitFault : 6|1@1+ (1,0) [0|1] "" Vector__XXX
 SG_ DAS_w136_lPillarCamInitFault : 7|1@1+ (1,0) [0|1] "" Vector__XXX
 SG_ DAS_w137_rPillarCamInitFault : 8|1@1+ (1,0) [0|1] "" Vector__XXX
 SG_ DAS_w138_lRepeatCamInitFault : 9|1@1+ (1,0) [0|1] "" Vector__XXX
 SG_ DAS_w139_rRepeatCamInitFault : 10|1@1+ (1,0) [0|1] "" Vector__XXX
 SG_ DAS_w140_backupCamInitFault : 11|1@1+ (1,0) [0|1] "" Vector__XXX
 SG_ DAS_w141_ECU_Thermal_Issue : 12|1@1+ (1,0) [0|1] "" Vector__XXX
 SG_ DAS_w142_fwdCamPitchProblem : 13|1@1+ (1,0) [0|1] "" Vector__XXX
 SG_ DAS_w143_IDF_event : 14|1@1+ (1,0) [0|1] "" Vector__XXX
 SG_ DAS_w144_selfieCamInitFault : 15|1@1+ (1,0) [0|1] "" Vector__XXX
 SG_ DAS_w171_fisheyeCamExtNotCal : 42|1@1+ (1,0) [0|1] "" Vector__XXX
 SG_ DAS_w172_lPillarCamExtNotCal : 43|1@1+ (1,0) [0|1] "" Vector__XXX
 SG_ DAS_w173_rPillarCamExtNotCal : 44|1@1+ (1,0) [0|1] "" Vector__XXX
 SG_ DAS_w174_lRepeatCamExtNotCal : 45|1@1+ (1,0) [0|1] "" Vector__XXX
 SG_ DAS_w175_rRepeatCamExtNotCal : 46|1@1+ (1,0) [0|1] "" Vector__XXX
 SG_ DAS_w177_fisheyeCamCalSaved : 48|1@1+ (1,0) [0|1] "" Vector__XXX
 SG_ DAS_w178_lPillarCamCalSaved : 49|1@1+ (1,0) [0|1] "" Vector__XXX
 SG_ DAS_w179_rPillarCamCalSaved : 50|1@1+ (1,0) [0|1] "" Vector__XXX
 SG_ DAS_w180_lRepeatCamCalSaved : 51|1@1+ (1,0) [0|1] "" Vector__XXX
 SG_ DAS_w181_rRepeatCamCalSaved : 52|1@1+ (1,0) [0|1] "" Vector__XXX

BO_ 1082 DAS_warningMatrix3: 8 DAS
 SG_ DAS_w193_camWindshieldUnclean : 0|1@1+ (1,0) [0|1] "" Vector__XXX
 SG_ DAS_w194_accDriverResumeRqrd : 1|1@1+ (1,0) [0|1] "" Vector__XXX
 SG_ DAS_w195_scwUnavailable : 2|1@1+ (1,0) [0|1] "" Vector__XXX
 SG_ DAS_w196_stopSignWarning : 3|1@1+ (1,0) [0|1] "" Vector__XXX
 SG_ DAS_w197_redLightWarning : 4|1@1+ (1,0) [0|1] "" Vector__XXX
 SG_ DAS_w198_tsrUnavailable : 5|1@1+ (1,0) [0|1] "" Vector__XXX
 SG_ DAS_w199_apcAbort : 6|1@1+ (1,0) [0|1] "" Vector__XXX
 SG_ DAS_w200_lcSlowdown : 7|1@1+ (1,0) [0|1] "" Vector__XXX
 SG_ DAS_w201_lcAborting : 8|1@1+ (1,0) [0|1] "" Vector__XXX
 SG_ DAS_w202_scwNoisyEnvironment : 9|1@1+ (1,0) [0|1] "" Vector__XXX
 SG_ DAS_w203_apcActivation : 10|1@1+ (1,0) [0|1] "" Vector__XXX
 SG_ DAS_w204_apcFinalFront : 11|1@1+ (1,0) [0|1] "" Vector__XXX
 SG_ DAS_w205_apcFinalRear : 12|1@1+ (1,0) [0|1] "" Vector__XXX
 SG_ DAS_w206_autosteerNotEnabled : 13|1@1+ (1,0) [0|1] "" Vector__XXX
 SG_ DAS_w207_autosteerUnavailable : 14|1@1+ (1,0) [0|1] "" Vector__XXX
 SG_ DAS_w208_rackDetected : 15|1@1+ (1,0) [0|1] "" Vector__XXX
 SG_ DAS_w209_autoSummonRequest : 16|1@1+ (1,0) [0|1] "" Vector__XXX
 SG_ DAS_w210_camObstrcted : 17|1@1+ (1,0) [0|1] "" Vector__XXX
 SG_ DAS_w211_accNoSeatBelt : 18|1@1+ (1,0) [0|1] "" Vector__XXX
 SG_ DAS_w212_lcUnavailableStrikeOut : 19|1@1+ (1,0) [0|1] "" Vector__XXX
 SG_ DAS_w213_autosteerStruckOut : 20|1@1+ (1,0) [0|1] "" Vector__XXX
 SG_ DAS_w214_driverNotIntracting : 21|1@1+ (1,0) [0|1] "" Vector__XXX
 SG_ DAS_w215_contDriverNotIntracting : 22|1@1+ (1,0) [0|1] "" Vector__XXX
 SG_ DAS_w216_driverOverriding : 23|1@1+ (1,0) [0|1] "" Vector__XXX
 SG_ DAS_w217_lcUnavailableSpeeding : 24|1@1+ (1,0) [0|1] "" Vector__XXX
 SG_ DAS_w218_lcSpeedExceededLimit : 25|1@1+ (1,0) [0|1] "" Vector__XXX
 SG_ DAS_w219_lcTempUnavailableSpeed : 26|1@1+ (1,0) [0|1] "" Vector__XXX
 SG_ DAS_w220_lcTempUnavailableRoad : 27|1@1+ (1,0) [0|1] "" Vector__XXX
 SG_ DAS_w221_accRadarBlind : 28|1@1+ (1,0) [0|1] "" Vector__XXX
 SG_ DAS_w222_accCameraBlind : 29|1@1+ (1,0) [0|1] "" Vector__XXX
 SG_ DAS_w223_accObjectInPath : 30|1@1+ (1,0) [0|1] "" Vector__XXX
 SG_ DAS_w224_accCameraCalibration : 31|1@1+ (1,0) [0|1] "" Vector__XXX
 SG_ DAS_w225_lcDegradedVisSpeedLmt : 32|1@1+ (1,0) [0|1] "" Vector__XXX
 SG_ DAS_w226_lcCamCalNeededSpeedLmt : 33|1@1+ (1,0) [0|1] "" Vector__XXX
 SG_ DAS_w227_virtualWallBlocked : 34|1@1+ (1,0) [0|1] "" Vector__XXX
 SG_ DAS_w228_DEPRECATED : 35|1@1+ (1,0) [0|1] "" Vector__XXX
 SG_ DAS_w229_alcUltrasoundDamaged : 36|1@1+ (1,0) [0|1] "" Vector__XXX
 SG_ DAS_w230_alcUltrasoundBlocked : 37|1@1+ (1,0) [0|1] "" Vector__XXX
 SG_ DAS_w231_idfEvent : 38|1@1+ (1,0) [0|1] "" Vector__XXX
 SG_ DAS_w232_laneChangeRequested : 39|1@1+ (1,0) [0|1] "" Vector__XXX

BO_ 1318 DIF_alertLog: 8 DIF
 SG_ DIF_alertID M : 0|8@1+ (1,0) [0|255] "" Vector__XXX
 SG_ DIF_alertState : 15|1@1+ (1,0) [0|1] "" Vector__XXX
 SG_ DIF_a001_thermalWarning_H m1 : 16|1@1+ (1,0) [0|1] "" Vector__XXX
 SG_ DIF_a001_thermalShutdown_H m1 : 17|1@1+ (1,0) [0|1] "" Vector__XXX
 SG_ DIF_a001_undervoltVL_H m1 : 18|1@1+ (1,0) [0|1] "" Vector__XXX
 SG_ DIF_a001_undervoltVH_H m1 : 19|1@1+ (1,0) [0|1] "" Vector__XXX
 SG_ DIF_a001_sense_H m1 : 20|1@1+ (1,0) [0|1] "" Vector__XXX
 SG_ DIF_a001_desat_H m1 : 21|1@1+ (1,0) [0|1] "" Vector__XXX
 SG_ DIF_a001_overvoltVL_H m1 : 22|1@1+ (1,0) [0|1] "" Vector__XXX
 SG_ DIF_a001_overvoltVH_H m1 : 23|1@1+ (1,0) [0|1] "" Vector__XXX
 SG_ DIF_a001_undervoltVCC_H m1 : 24|1@1+ (1,0) [0|1] "" Vector__XXX
 SG_ DIF_a001_asynchStop_H m1 : 25|1@1+ (1,0) [0|1] "" Vector__XXX
 SG_ DIF_a001_remoteRegError_H m1 : 26|1@1+ (1,0) [0|1] "" Vector__XXX
 SG_ DIF_a001_undervoltVDD_H m1 : 27|1@1+ (1,0) [0|1] "" Vector__XXX
 SG_ DIF_a001_overvoltVDD_H m1 : 28|1@1+ (1,0) [0|1] "" Vector__XXX
 SG_ DIF_a001_localRegError_H m1 : 29|1@1+ (1,0) [0|1] "" Vector__XXX
 SG_ DIF_a001_spiError_H m1 : 30|1@1+ (1,0) [0|1] "" Vector__XXX
 SG_ DIF_a001_deadtimeError_H m1 : 31|1@1+ (1,0) [0|1] "" Vector__XXX
 SG_ DIF_a001_thermalWarning_L m1 : 32|1@1+ (1,0) [0|1] "" Vector__XXX
 SG_ DIF_a001_thermalShutdown_L m1 : 33|1@1+ (1,0) [0|1] "" Vector__XXX
 SG_ DIF_a001_undervoltVL_L m1 : 34|1@1+ (1,0) [0|1] "" Vector__XXX
 SG_ DIF_a001_undervoltVH_L m1 : 35|1@1+ (1,0) [0|1] "" Vector__XXX
 SG_ DIF_a001_sense_L m1 : 36|1@1+ (1,0) [0|1] "" Vector__XXX
 SG_ DIF_a001_desat_L m1 : 37|1@1+ (1,0) [0|1] "" Vector__XXX
 SG_ DIF_a001_overvoltVL_L m1 : 38|1@1+ (1,0) [0|1] "" Vector__XXX
 SG_ DIF_a001_overvoltVH_L m1 : 39|1@1+ (1,0) [0|1] "" Vector__XXX
 SG_ DIF_a001_undervoltVCC_L m1 : 40|1@1+ (1,0) [0|1] "" Vector__XXX
 SG_ DIF_a001_asynchStop_L m1 : 41|1@1+ (1,0) [0|1] "" Vector__XXX
 SG_ DIF_a001_remoteRegError_L m1 : 42|1@1+ (1,0) [0|1] "" Vector__XXX
 SG_ DIF_a001_undervoltVDD_L m1 : 43|1@1+ (1,0) [0|1] "" Vector__XXX
 SG_ DIF_a001_overvoltVDD_L m1 : 44|1@1+ (1,0) [0|1] "" Vector__XXX
 SG_ DIF_a001_localRegError_L m1 : 45|1@1+ (1,0) [0|1] "" Vector__XXX
 SG_ DIF_a001_spiError_L m1 : 46|1@1+ (1,0) [0|1] "" Vector__XXX
 SG_ DIF_a001_deadtimeError_L m1 : 47|1@1+ (1,0) [0|1] "" Vector__XXX
 SG_ DIF_a001_gateDriveErrCounter m1 : 48|4@1+ (1,0) [0|15] "" Vector__XXX
 SG_ DIF_a001_remoteCommError_H m1 : 52|1@1+ (1,0) [0|1] "" Vector__XXX
 SG_ DIF_a001_localCommError_H m1 : 53|1@1+ (1,0) [0|1] "" Vector__XXX
 SG_ DIF_a001_remoteReset_H m1 : 54|1@1+ (1,0) [0|1] "" Vector__XXX
 SG_ DIF_a001_localReset_H m1 : 55|1@1+ (1,0) [0|1] "" Vector__XXX
 SG_ DIF_a001_remoteCommError_L m1 : 56|1@1+ (1,0) [0|1] "" Vector__XXX
 SG_ DIF_a001_localCommError_L m1 : 57|1@1+ (1,0) [0|1] "" Vector__XXX
 SG_ DIF_a001_remoteReset_L m1 : 58|1@1+ (1,0) [0|1] "" Vector__XXX
 SG_ DIF_a001_localReset_L m1 : 59|1@1+ (1,0) [0|1] "" Vector__XXX
 SG_ DIF_a001_faultLine1Gpio_H m1 : 60|1@1+ (1,0) [0|1] "" Vector__XXX
 SG_ DIF_a001_faultLine1Gpio_L m1 : 61|1@1+ (1,0) [0|1] "" Vector__XXX
 SG_ DIF_a002_thermalWarning_H m2 : 16|1@1+ (1,0) [0|1] "" Vector__XXX
 SG_ DIF_a002_thermalShutdown_H m2 : 17|1@1+ (1,0) [0|1] "" Vector__XXX
 SG_ DIF_a002_undervoltVL_H m2 : 18|1@1+ (1,0) [0|1] "" Vector__XXX
 SG_ DIF_a002_undervoltVH_H m2 : 19|1@1+ (1,0) [0|1] "" Vector__XXX
 SG_ DIF_a002_sense_H m2 : 20|1@1+ (1,0) [0|1] "" Vector__XXX
 SG_ DIF_a002_desat_H m2 : 21|1@1+ (1,0) [0|1] "" Vector__XXX
 SG_ DIF_a002_overvoltVL_H m2 : 22|1@1+ (1,0) [0|1] "" Vector__XXX
 SG_ DIF_a002_overvoltVH_H m2 : 23|1@1+ (1,0) [0|1] "" Vector__XXX
 SG_ DIF_a002_undervoltVCC_H m2 : 24|1@1+ (1,0) [0|1] "" Vector__XXX
 SG_ DIF_a002_asynchStop_H m2 : 25|1@1+ (1,0) [0|1] "" Vector__XXX
 SG_ DIF_a002_remoteRegError_H m2 : 26|1@1+ (1,0) [0|1] "" Vector__XXX
 SG_ DIF_a002_undervoltVDD_H m2 : 27|1@1+ (1,0) [0|1] "" Vector__XXX
 SG_ DIF_a002_overvoltVDD_H m2 : 28|1@1+ (1,0) [0|1] "" Vector__XXX
 SG_ DIF_a002_localRegError_H m2 : 29|1@1+ (1,0) [0|1] "" Vector__XXX
 SG_ DIF_a002_spiError_H m2 : 30|1@1+ (1,0) [0|1] "" Vector__XXX
 SG_ DIF_a002_deadtimeError_H m2 : 31|1@1+ (1,0) [0|1] "" Vector__XXX
 SG_ DIF_a002_thermalWarning_L m2 : 32|1@1+ (1,0) [0|1] "" Vector__XXX
 SG_ DIF_a002_thermalShutdown_L m2 : 33|1@1+ (1,0) [0|1] "" Vector__XXX
 SG_ DIF_a002_undervoltVL_L m2 : 34|1@1+ (1,0) [0|1] "" Vector__XXX
 SG_ DIF_a002_undervoltVH_L m2 : 35|1@1+ (1,0) [0|1] "" Vector__XXX
 SG_ DIF_a002_sense_L m2 : 36|1@1+ (1,0) [0|1] "" Vector__XXX
 SG_ DIF_a002_desat_L m2 : 37|1@1+ (1,0) [0|1] "" Vector__XXX
 SG_ DIF_a002_overvoltVL_L m2 : 38|1@1+ (1,0) [0|1] "" Vector__XXX
 SG_ DIF_a002_overvoltVH_L m2 : 39|1@1+ (1,0) [0|1] "" Vector__XXX
 SG_ DIF_a002_undervoltVCC_L m2 : 40|1@1+ (1,0) [0|1] "" Vector__XXX
 SG_ DIF_a002_asynchStop_L m2 : 41|1@1+ (1,0) [0|1] "" Vector__XXX
 SG_ DIF_a002_remoteRegError_L m2 : 42|1@1+ (1,0) [0|1] "" Vector__XXX
 SG_ DIF_a002_undervoltVDD_L m2 : 43|1@1+ (1,0) [0|1] "" Vector__XXX
 SG_ DIF_a002_overvoltVDD_L m2 : 44|1@1+ (1,0) [0|1] "" Vector__XXX
 SG_ DIF_a002_localRegError_L m2 : 45|1@1+ (1,0) [0|1] "" Vector__XXX
 SG_ DIF_a002_spiError_L m2 : 46|1@1+ (1,0) [0|1] "" Vector__XXX
 SG_ DIF_a002_deadtimeError_L m2 : 47|1@1+ (1,0) [0|1] "" Vector__XXX
 SG_ DIF_a002_gateDriveErrCounter m2 : 48|4@1+ (1,0) [0|15] "" Vector__XXX
 SG_ DIF_a002_remoteCommError_H m2 : 52|1@1+ (1,0) [0|1] "" Vector__XXX
 SG_ DIF_a002_localCommError_H m2 : 53|1@1+ (1,0) [0|1] "" Vector__XXX
 SG_ DIF_a002_remoteReset_H m2 : 54|1@1+ (1,0) [0|1] "" Vector__XXX
 SG_ DIF_a002_localReset_H m2 : 55|1@1+ (1,0) [0|1] "" Vector__XXX
 SG_ DIF_a002_remoteCommError_L m2 : 56|1@1+ (1,0) [0|1] "" Vector__XXX
 SG_ DIF_a002_localCommError_L m2 : 57|1@1+ (1,0) [0|1] "" Vector__XXX
 SG_ DIF_a002_remoteReset_L m2 : 58|1@1+ (1,0) [0|1] "" Vector__XXX
 SG_ DIF_a002_localReset_L m2 : 59|1@1+ (1,0) [0|1] "" Vector__XXX
 SG_ DIF_a002_faultLine1Gpio_H m2 : 60|1@1+ (1,0) [0|1] "" Vector__XXX
 SG_ DIF_a002_faultLine1Gpio_L m2 : 61|1@1+ (1,0) [0|1] "" Vector__XXX
 SG_ DIF_a003_thermalWarning_H m3 : 16|1@1+ (1,0) [0|1] "" Vector__XXX
 SG_ DIF_a003_thermalShutdown_H m3 : 17|1@1+ (1,0) [0|1] "" Vector__XXX
 SG_ DIF_a003_undervoltVL_H m3 : 18|1@1+ (1,0) [0|1] "" Vector__XXX
 SG_ DIF_a003_undervoltVH_H m3 : 19|1@1+ (1,0) [0|1] "" Vector__XXX
 SG_ DIF_a003_sense_H m3 : 20|1@1+ (1,0) [0|1] "" Vector__XXX
 SG_ DIF_a003_desat_H m3 : 21|1@1+ (1,0) [0|1] "" Vector__XXX
 SG_ DIF_a003_overvoltVL_H m3 : 22|1@1+ (1,0) [0|1] "" Vector__XXX
 SG_ DIF_a003_overvoltVH_H m3 : 23|1@1+ (1,0) [0|1] "" Vector__XXX
 SG_ DIF_a003_undervoltVCC_H m3 : 24|1@1+ (1,0) [0|1] "" Vector__XXX
 SG_ DIF_a003_asynchStop_H m3 : 25|1@1+ (1,0) [0|1] "" Vector__XXX
 SG_ DIF_a003_remoteRegError_H m3 : 26|1@1+ (1,0) [0|1] "" Vector__XXX
 SG_ DIF_a003_undervoltVDD_H m3 : 27|1@1+ (1,0) [0|1] "" Vector__XXX
 SG_ DIF_a003_overvoltVDD_H m3 : 28|1@1+ (1,0) [0|1] "" Vector__XXX
 SG_ DIF_a003_localRegError_H m3 : 29|1@1+ (1,0) [0|1] "" Vector__XXX
 SG_ DIF_a003_spiError_H m3 : 30|1@1+ (1,0) [0|1] "" Vector__XXX
 SG_ DIF_a003_deadtimeError_H m3 : 31|1@1+ (1,0) [0|1] "" Vector__XXX
 SG_ DIF_a003_thermalWarning_L m3 : 32|1@1+ (1,0) [0|1] "" Vector__XXX
 SG_ DIF_a003_thermalShutdown_L m3 : 33|1@1+ (1,0) [0|1] "" Vector__XXX
 SG_ DIF_a003_undervoltVL_L m3 : 34|1@1+ (1,0) [0|1] "" Vector__XXX
 SG_ DIF_a003_undervoltVH_L m3 : 35|1@1+ (1,0) [0|1] "" Vector__XXX
 SG_ DIF_a003_sense_L m3 : 36|1@1+ (1,0) [0|1] "" Vector__XXX
 SG_ DIF_a003_desat_L m3 : 37|1@1+ (1,0) [0|1] "" Vector__XXX
 SG_ DIF_a003_overvoltVL_L m3 : 38|1@1+ (1,0) [0|1] "" Vector__XXX
 SG_ DIF_a003_overvoltVH_L m3 : 39|1@1+ (1,0) [0|1] "" Vector__XXX
 SG_ DIF_a003_undervoltVCC_L m3 : 40|1@1+ (1,0) [0|1] "" Vector__XXX
 SG_ DIF_a003_asynchStop_L m3 : 41|1@1+ (1,0) [0|1] "" Vector__XXX
 SG_ DIF_a003_remoteRegError_L m3 : 42|1@1+ (1,0) [0|1] "" Vector__XXX
 SG_ DIF_a003_undervoltVDD_L m3 : 43|1@1+ (1,0) [0|1] "" Vector__XXX
 SG_ DIF_a003_overvoltVDD_L m3 : 44|1@1+ (1,0) [0|1] "" Vector__XXX
 SG_ DIF_a003_localRegError_L m3 : 45|1@1+ (1,0) [0|1] "" Vector__XXX
 SG_ DIF_a003_spiError_L m3 : 46|1@1+ (1,0) [0|1] "" Vector__XXX
 SG_ DIF_a003_deadtimeError_L m3 : 47|1@1+ (1,0) [0|1] "" Vector__XXX
 SG_ DIF_a003_gateDriveErrCounter m3 : 48|4@1+ (1,0) [0|15] "" Vector__XXX
 SG_ DIF_a003_remoteCommError_H m3 : 52|1@1+ (1,0) [0|1] "" Vector__XXX
 SG_ DIF_a003_localCommError_H m3 : 53|1@1+ (1,0) [0|1] "" Vector__XXX
 SG_ DIF_a003_remoteReset_H m3 : 54|1@1+ (1,0) [0|1] "" Vector__XXX
 SG_ DIF_a003_localReset_H m3 : 55|1@1+ (1,0) [0|1] "" Vector__XXX
 SG_ DIF_a003_remoteCommError_L m3 : 56|1@1+ (1,0) [0|1] "" Vector__XXX
 SG_ DIF_a003_localCommError_L m3 : 57|1@1+ (1,0) [0|1] "" Vector__XXX
 SG_ DIF_a003_remoteReset_L m3 : 58|1@1+ (1,0) [0|1] "" Vector__XXX
 SG_ DIF_a003_localReset_L m3 : 59|1@1+ (1,0) [0|1] "" Vector__XXX
 SG_ DIF_a003_faultLine1Gpio_H m3 : 60|1@1+ (1,0) [0|1] "" Vector__XXX
 SG_ DIF_a003_faultLine1Gpio_L m3 : 61|1@1+ (1,0) [0|1] "" Vector__XXX
 SG_ DIF_a007_phaseAcurrent m7 : 16|8@1+ (8,0) [0|2040] "" Vector__XXX
 SG_ DIF_a007_phaseBcurrent m7 : 24|8@1+ (8,0) [0|2040] "" Vector__XXX
 SG_ DIF_a007_offsetError m7 : 32|14@1- (0.0003834952,0) [-3.1415926784|3.1412091832] "" Vector__XXX
 SG_ DIF_a007_idFdbStdDeviation m7 : 46|8@1+ (4,0) [0|1020] "" Vector__XXX
 SG_ DIF_a007_iqFdbStdDeviation m7 : 54|8@1+ (4,0) [0|1020] "" Vector__XXX
 SG_ DIF_a007_motorShift m7 : 62|1@1+ (1,0) [0|1] "" Vector__XXX
 SG_ DIF_a007_motorShort m7 : 63|1@1+ (1,0) [0|1] "" Vector__XXX
 SG_ DIF_a010_sccReset m10 : 16|1@1+ (1,0) [0|1] "" Vector__XXX
 SG_ DIF_a010_hibernate m10 : 17|1@1+ (1,0) [0|1] "" Vector__XXX
 SG_ DIF_a010_hwBist m10 : 18|1@1+ (1,0) [0|1] "" Vector__XXX
 SG_ DIF_a010_nmiWatchdog m10 : 19|1@1+ (1,0) [0|1] "" Vector__XXX
 SG_ DIF_a010_watchdog m10 : 20|1@1+ (1,0) [0|1] "" Vector__XXX
 SG_ DIF_a010_clockFailNmi m10 : 21|1@1+ (1,0) [0|1] "" Vector__XXX
 SG_ DIF_a010_ramUncErrorNmi m10 : 22|1@1+ (1,0) [0|1] "" Vector__XXX
 SG_ DIF_a010_flashUncErrorNmi m10 : 23|1@1+ (1,0) [0|1] "" Vector__XXX
 SG_ DIF_a010_cpu1signMismatchNmi m10 : 24|1@1+ (1,0) [0|1] "" Vector__XXX
 SG_ DIF_a010_cpu2signMismatchNmi m10 : 25|1@1+ (1,0) [0|1] "" Vector__XXX
 SG_ DIF_a010_pieVectErrorNmi m10 : 26|1@1+ (1,0) [0|1] "" Vector__XXX
 SG_ DIF_a010_sysDbgNmi m10 : 27|1@1+ (1,0) [0|1] "" Vector__XXX
 SG_ DIF_a010_rlNmi m10 : 28|1@1+ (1,0) [0|1] "" Vector__XXX
 SG_ DIF_a010_ovfNmi m10 : 29|1@1+ (1,0) [0|1] "" Vector__XXX
 SG_ DIF_a010_wdtFlags m10 : 32|16@1+ (1,0) [0|65535] "" Vector__XXX
 SG_ DIF_a011_reason m11 : 16|3@1+ (1,0) [0|7] "" Vector__XXX
 SG_ DIF_a011_phaseAHigh m11 : 19|1@1+ (1,0) [0|1] "" Vector__XXX
 SG_ DIF_a011_phaseALow m11 : 20|1@1+ (1,0) [0|1] "" Vector__XXX
 SG_ DIF_a011_phaseBHigh m11 : 21|1@1+ (1,0) [0|1] "" Vector__XXX
 SG_ DIF_a011_phaseBLow m11 : 22|1@1+ (1,0) [0|1] "" Vector__XXX
 SG_ DIF_a011_phaseCHigh m11 : 23|1@1+ (1,0) [0|1] "" Vector__XXX
 SG_ DIF_a011_phaseCLow m11 : 24|1@1+ (1,0) [0|1] "" Vector__XXX
 SG_ DIF_a011_regAddress m11 : 25|5@1+ (1,0) [0|31] "" Vector__XXX
 SG_ DIF_a011_badGateDriveIC m11 : 32|3@1+ (1,0) [0|7] "" Vector__XXX
 SG_ DIF_a011_badDataRead m11 : 40|8@1+ (1,0) [0|255] "" Vector__XXX
 SG_ DIF_a011_badDataExpected m11 : 48|8@1+ (1,0) [0|255] "" Vector__XXX
 SG_ DIF_a011_codeBranch m11 : 56|4@1+ (1,0) [0|15] "" Vector__XXX
 SG_ DIF_a012_hvilStatus m12 : 16|2@1+ (1,0) [0|3] "" Vector__XXX
 SG_ DIF_a012_hvilCmVoltage m12 : 24|8@1+ (0.08,0) [0|20.4] "" Vector__XXX
 SG_ DIF_a012_hvilCurrent m12 : 32|8@1+ (0.1,0) [0|25.5] "" Vector__XXX
 SG_ DIF_a012_hvilFaultGpio m12 : 40|1@1+ (1,0) [0|1] "" Vector__XXX
 SG_ DIF_a012_hvilSupplyPinDI m12 : 41|1@1+ (1,0) [0|1] "" Vector__XXX
 SG_ DIF_a012_hvilSupplyPinPM m12 : 42|1@1+ (1,0) [0|1] "" Vector__XXX
 SG_ DIF_a012_activeDisOn3V3 m12 : 43|1@1+ (1,0) [0|1] "" Vector__XXX
 SG_ DIF_a012_hvilHeaderFault m12 : 44|1@1+ (1,0) [0|1] "" Vector__XXX
 SG_ DIF_a013_address m13 : 16|32@1+ (1,0) [0|4294967295] "" Vector__XXX
 SG_ DIF_a013_errorType m13 : 48|4@1+ (1,0) [0|15] "" Vector__XXX
 SG_ DIF_a014_motorSpeed m14 : 16|14@1- (2,0) [-16384|16382] "" Vector__XXX
 SG_ DIF_a014_adState m14 : 30|2@1+ (1,0) [0|3] "" Vector__XXX
 SG_ DIF_a014_torqueCommandFwd m14 : 32|10@1- (2,0) [-1024|1022] "" Vector__XXX
 SG_ DIF_a014_brakeMasterCylPress m14 : 42|10@1+ (0.25,-42.5) [-42.5|213.25] "" Vector__XXX
 SG_ DIF_a014_rmsTorqueError m14 : 52|10@1+ (1,0) [0|1023] "" Vector__XXX
 SG_ DIF_a014_tcEnabled m14 : 62|1@1+ (1,0) [0|1] "" Vector__XXX
 SG_ DIF_a014_fbDeratedForRmsError m14 : 63|1@1+ (1,0) [0|1] "" Vector__XXX
 SG_ DIF_a016_newSafeState m16 : 16|2@1+ (1,0) [0|3] "" Vector__XXX
 SG_ DIF_a016_oldSafeState m16 : 18|2@1+ (1,0) [0|3] "" Vector__XXX
 SG_ DIF_a016_gateDriveFaultLine m16 : 20|1@1+ (1,0) [0|1] "" Vector__XXX
 SG_ DIF_a016_ascMonitor m16 : 21|1@1+ (1,0) [0|1] "" Vector__XXX
 SG_ DIF_a016_uncontrolledRegenZone m16 : 22|1@1+ (1,0) [0|1] "" Vector__XXX
 SG_ DIF_a016_pedalMonitorPreWatchdog m16 : 23|1@1+ (1,0) [0|1] "" Vector__XXX
 SG_ DIF_a016_motorRPM m16 : 24|16@1- (1,0) [-32768|32767] "" Vector__XXX
 SG_ DIF_a016_torqueMotor m16 : 40|16@1- (1,0) [-32768|32767] "" Vector__XXX
 SG_ DIF_a016_safetyICfaultLine m16 : 56|1@1+ (1,0) [0|1] "" Vector__XXX
 SG_ DIF_a016_triggerEvent m16 : 57|5@1+ (1,0) [0|31] "" Vector__XXX
 SG_ DIF_a024_vBat m24 : 16|8@1+ (2,0) [0|510] "" Vector__XXX
 SG_ DIF_a024_failReason m24 : 24|3@1+ (1,0) [0|7] "" Vector__XXX
 SG_ DIF_a024_state m24 : 27|4@1+ (1,0) [0|15] "" Vector__XXX
 SG_ DIF_a024_Ia m24 : 31|7@1- (22.5,0) [-1440|1417.5] "" Vector__XXX
 SG_ DIF_a024_Ib m24 : 38|7@1- (22.5,0) [-1440|1417.5] "" Vector__XXX
 SG_ DIF_a024_maxCurrMagSqrd m24 : 45|12@1+ (500,0) [0|2047500] "" Vector__XXX
 SG_ DIF_a024_rotorAngle m24 : 57|7@1- (3,0) [-192|189] "" Vector__XXX
 SG_ DIF_a025_Ia m25 : 16|16@1- (0.1,0) [-3276.8|3276.7] "" Vector__XXX
 SG_ DIF_a025_torqueMotor m25 : 32|13@1- (0.25,0) [-1024|1023.75] "" Vector__XXX
 SG_ DIF_a025_motorSpeed m25 : 48|16@1- (1,0) [-32768|32767] "" Vector__XXX
 SG_ DIF_a026_Ib m26 : 16|16@1- (0.1,0) [-3276.8|3276.7] "" Vector__XXX
 SG_ DIF_a026_torqueMotor m26 : 32|13@1- (0.25,0) [-1024|1023.75] "" Vector__XXX
 SG_ DIF_a026_motorSpeed m26 : 48|16@1- (1,0) [-32768|32767] "" Vector__XXX
 SG_ DIF_a027_Ic m27 : 16|16@1- (0.1,0) [-3276.8|3276.7] "" Vector__XXX
 SG_ DIF_a027_torqueMotor m27 : 32|13@1- (0.25,0) [-1024|1023.75] "" Vector__XXX
 SG_ DIF_a027_motorSpeed m27 : 48|16@1- (1,0) [-32768|32767] "" Vector__XXX
 SG_ DIF_a028_phaseAirms m28 : 16|16@1+ (1,0) [0|65535] "" Vector__XXX
 SG_ DIF_a028_iArmsTorque m28 : 32|16@1+ (0.25,0) [0|16383.75] "" Vector__XXX
 SG_ DIF_a028_iArmsSpeed m28 : 48|16@1+ (1,0) [0|65535] "" Vector__XXX
 SG_ DIF_a029_phaseBirms m29 : 16|16@1+ (1,0) [0|65535] "" Vector__XXX
 SG_ DIF_a029_iBrmsTorque m29 : 32|16@1+ (0.25,0) [0|16383.75] "" Vector__XXX
 SG_ DIF_a029_iBrmsSpeed m29 : 48|16@1+ (1,0) [0|65535] "" Vector__XXX
 SG_ DIF_a030_phaseCirms m30 : 16|16@1+ (1,0) [0|65535] "" Vector__XXX
 SG_ DIF_a030_iCrmsTorque m30 : 32|16@1+ (0.25,0) [0|16383.75] "" Vector__XXX
 SG_ DIF_a030_iCrmsSpeed m30 : 48|16@1+ (1,0) [0|65535] "" Vector__XXX
 SG_ DIF_a031_phaseAoffset m31 : 16|15@1- (0.002,0) [-32.768|32.766] "" Vector__XXX
 SG_ DIF_a032_phaseBoffset m32 : 16|15@1- (0.002,0) [-32.768|32.766] "" Vector__XXX
 SG_ DIF_a033_phaseAcurrent m33 : 16|16@1- (1,0) [-32768|32767] "" Vector__XXX
 SG_ DIF_a033_deltaIa m33 : 32|16@1- (1,0) [-32768|32767] "" Vector__XXX
 SG_ DIF_a033_vRefIa m33 : 48|16@1- (0.001,0) [-32.768|32.767] "" Vector__XXX
 SG_ DIF_a034_phaseBcurrent m34 : 16|16@1- (1,0) [-32768|32767] "" Vector__XXX
 SG_ DIF_a034_deltaIb m34 : 32|16@1- (1,0) [-32768|32767] "" Vector__XXX
 SG_ DIF_a034_vRefIb m34 : 48|16@1- (0.001,0) [-32.768|32.767] "" Vector__XXX
 SG_ DIF_a035_phaseAerror m35 : 16|1@1+ (1,0) [0|1] "" Vector__XXX
 SG_ DIF_a035_phaseBerror m35 : 17|1@1+ (1,0) [0|1] "" Vector__XXX
 SG_ DIF_a035_phaseCerror m35 : 18|1@1+ (1,0) [0|1] "" Vector__XXX
 SG_ DIF_a035_standbyCurrent m35 : 19|1@1+ (1,0) [0|1] "" Vector__XXX
 SG_ DIF_a035_unbalancedCurrent m35 : 20|1@1+ (1,0) [0|1] "" Vector__XXX
 SG_ DIF_a035_wontMoveCurrent m35 : 21|1@1+ (1,0) [0|1] "" Vector__XXX
 SG_ DIF_a035_reportingPhase m35 : 22|2@1+ (1,0) [0|3] "" Vector__XXX
 SG_ DIF_a035_noDriveCurrent m35 : 24|1@1+ (1,0) [0|1] "" Vector__XXX
 SG_ DIF_a035_phaseDifference m35 : 25|7@1+ (1,0) [0|127] "" Vector__XXX
 SG_ DIF_a035_phaseCurrent m35 : 32|16@1+ (1,0) [0|65535] "" Vector__XXX
 SG_ DIF_a035_frequency m35 : 48|10@1+ (1,0) [0|1023] "" Vector__XXX
 SG_ DIF_a036_busVoltage m36 : 16|16@1+ (0.1,0) [0|6553.5] "" Vector__XXX
 SG_ DIF_a036_busHighLimit m36 : 32|16@1+ (0.1,0) [0|6553.5] "" Vector__XXX
 SG_ DIF_a037_busVoltage m37 : 16|16@1+ (0.1,0) [0|6553.5] "" Vector__XXX
 SG_ DIF_a037_busLowLimit m37 : 32|16@1+ (0.1,0) [0|6553.5] "" Vector__XXX
 SG_ DIF_a038_vBMS m38 : 16|13@1+ (0.2,0) [0|1638.2] "" Vector__XXX
 SG_ DIF_a038_vBat m38 : 32|13@1+ (0.2,0) [0|1638.2] "" Vector__XXX
 SG_ DIF_a038_iBat m38 : 48|13@1+ (0.5,0) [0|4095.5] "" Vector__XXX
 SG_ DIF_a038_reason m38 : 61|2@1+ (1,0) [0|3] "" Vector__XXX
 SG_ DIF_a040_torque m40 : 16|1@1+ (1,0) [0|1] "" Vector__XXX
 SG_ DIF_a040_capability m40 : 17|1@1+ (1,0) [0|1] "" Vector__XXX
 SG_ DIF_a040_power m40 : 18|1@1+ (1,0) [0|1] "" Vector__XXX
 SG_ DIF_a040_status m40 : 19|1@1+ (1,0) [0|1] "" Vector__XXX
 SG_ DIF_a040_capability2 m40 : 20|1@1+ (1,0) [0|1] "" Vector__XXX
 SG_ DIF_a040_hvStatus m40 : 21|1@1+ (1,0) [0|1] "" Vector__XXX
 SG_ DIF_a040_temperature m40 : 22|1@1+ (1,0) [0|1] "" Vector__XXX
 SG_ DIF_a041_uartRxDataAvailable m41 : 16|1@1+ (1,0) [0|1] "" Vector__XXX
 SG_ DIF_a041_SDC_status_MIA m41 : 17|1@1+ (1,0) [0|1] "" Vector__XXX
 SG_ DIF_a041_diUartRxVersion m41 : 18|4@1+ (1,0) [0|15] "" Vector__XXX
 SG_ DIF_a041_sdcUartRxVersion m41 : 24|4@1+ (1,0) [0|15] "" Vector__XXX
 SG_ DIF_a043_outletTemp m43 : 16|16@1- (0.1,0) [-3276.8|3276.7] "" Vector__XXX
 SG_ DIF_a044_outletTemp m44 : 16|16@1- (0.1,0) [-3276.8|3276.7] "" Vector__XXX
 SG_ DIF_a045_inletTemp m45 : 16|10@1+ (0.25,-60) [-60|195.75] "" Vector__XXX
 SG_ DIF_a045_outletTemp m45 : 26|10@1+ (0.25,-60) [-60|195.75] "" Vector__XXX
 SG_ DIF_a045_heatsinkTemp m45 : 36|10@1+ (0.25,-60) [-60|195.75] "" Vector__XXX
 SG_ DIF_a045_outletTempSlope m45 : 48|8@1- (0.5,0) [-64|63.5] "" Vector__XXX
 SG_ DIF_a046_statorTemp1 m46 : 16|16@1- (0.1,0) [-3276.8|3276.7] "" Vector__XXX
 SG_ DIF_a046_statorTemp2 m46 : 32|16@1- (0.1,0) [-3276.8|3276.7] "" Vector__XXX
 SG_ DIF_a047_statorTemp1 m47 : 16|16@1- (0.1,0) [-3276.8|3276.7] "" Vector__XXX
 SG_ DIF_a047_statorTslope1 m47 : 32|16@1- (0.1,0) [-3276.8|3276.7] "" Vector__XXX
 SG_ DIF_a050_statorTemp1 m50 : 16|16@1- (0.1,0) [-3276.8|3276.7] "" Vector__XXX
 SG_ DIF_a050_statorTemp2 m50 : 32|16@1- (0.1,0) [-3276.8|3276.7] "" Vector__XXX
 SG_ DIF_a052_torque m52 : 16|1@1+ (1,0) [0|1] "" Vector__XXX
 SG_ DIF_a052_capability m52 : 17|1@1+ (1,0) [0|1] "" Vector__XXX
 SG_ DIF_a052_power m52 : 18|1@1+ (1,0) [0|1] "" Vector__XXX
 SG_ DIF_a052_status m52 : 19|1@1+ (1,0) [0|1] "" Vector__XXX
 SG_ DIF_a052_capability2 m52 : 20|1@1+ (1,0) [0|1] "" Vector__XXX
 SG_ DIF_a052_hvStatus m52 : 21|1@1+ (1,0) [0|1] "" Vector__XXX
 SG_ DIF_a052_temperature m52 : 22|1@1+ (1,0) [0|1] "" Vector__XXX
 SG_ DIF_a054_outletTemp m54 : 16|16@1- (0.1,0) [-3276.8|3276.7] "" Vector__XXX
 SG_ DIF_a054_heatsinkTemp m54 : 32|16@1- (0.1,0) [-3276.8|3276.7] "" Vector__XXX
 SG_ DIF_a055_parameterDI m55 : 16|13@1- (0.25,0) [-1024|1023.75] "" Vector__XXX
 SG_ DIF_a055_parameterPM m55 : 32|13@1- (0.25,0) [-1024|1023.75] "" Vector__XXX
 SG_ DIF_a055_torqueType m55 : 45|2@1+ (1,0) [0|3] "" Vector__XXX
 SG_ DIF_a055_motorRPM m55 : 48|16@1- (1,0) [-32768|32767] "" Vector__XXX
 SG_ DIF_a056_pcbTemp m56 : 16|16@1- (0.1,0) [-3276.8|3276.7] "" Vector__XXX
 SG_ DIF_a057_pcbTemp m57 : 16|16@1- (0.1,0) [-3276.8|3276.7] "" Vector__XXX
 SG_ DIF_a058_pcbTemp m58 : 16|10@1+ (0.25,-60) [-60|195.75] "" Vector__XXX
 SG_ DIF_a058_outletTemp m58 : 26|10@1+ (0.25,-60) [-60|195.75] "" Vector__XXX
 SG_ DIF_a058_heatsinkTemp m58 : 36|10@1+ (0.25,-60) [-60|195.75] "" Vector__XXX
 SG_ DIF_a058_pcbTempSlope m58 : 48|8@1- (0.5,0) [-64|63.5] "" Vector__XXX
 SG_ DIF_a059_heatsinkTemp m59 : 16|16@1- (0.1,0) [-3276.8|3276.7] "" Vector__XXX
 SG_ DIF_a060_heatsinkTemp m60 : 16|16@1- (0.1,0) [-3276.8|3276.7] "" Vector__XXX
 SG_ DIF_a061_sensor m61 : 16|2@1+ (1,0) [0|3] "" Vector__XXX
 SG_ DIF_a061_reason m61 : 18|1@1+ (1,0) [0|1] "" Vector__XXX
 SG_ DIF_a061_phTemp m61 : 24|16@1- (0.1,0) [-3276.8|3276.7] "" Vector__XXX
 SG_ DIF_a061_otherTemp m61 : 40|16@1- (0.1,0) [-3276.8|3276.7] "" Vector__XXX
 SG_ DIF_a062_limpReason m62 : 16|6@1+ (1,0) [0|63] "" Vector__XXX
 SG_ DIF_a063_BB_status m63 : 16|1@1+ (1,0) [0|1] "" Vector__XXX
 SG_ DIF_a064_interventionType m64 : 16|4@1+ (1,0) [0|15] "" Vector__XXX
 SG_ DIF_a064_torqueCmdState m64 : 20|4@1+ (1,0) [0|15] "" Vector__XXX
 SG_ DIF_a069_motorSpeed m69 : 16|16@1- (1,0) [-32768|32767] "" Vector__XXX
 SG_ DIF_a069_rotorCoolingPower m69 : 32|8@1+ (20,0) [0|5100] "" Vector__XXX
 SG_ DIF_a069_rotorMagnetTemp m69 : 40|10@1+ (0.25,-60) [-60|195.75] "" Vector__XXX
 SG_ DIF_a069_fittedTorqueLimit m69 : 50|13@1- (0.25,0) [-1024|1023.75] "" Vector__XXX
 SG_ DIF_a072_reason m72 : 16|2@1+ (1,0) [0|3] "" Vector__XXX
 SG_ DIF_a073_motorSpeedrpm m73 : 16|16@1- (1,0) [-32768|32767] "" Vector__XXX
 SG_ DIF_a075_motorSpeed m75 : 16|16@1+ (1,0) [0|65535] "" Vector__XXX
 SG_ DIF_a075_absSpeed m75 : 32|16@1+ (1,0) [0|65535] "" Vector__XXX
 SG_ DIF_a076_lvSupplyV m76 : 16|16@1+ (0.001,0) [0|65.535] "" Vector__XXX
 SG_ DIF_a077_lvSupplyV m77 : 16|16@1+ (0.001,0) [0|65.535] "" Vector__XXX
 SG_ DIF_a078_adcRefChan m78 : 16|4@1+ (1,0) [0|15] "" Vector__XXX
 SG_ DIF_a078_adcRefLowAvg m78 : 24|16@1+ (1,0) [0|65535] "" Vector__XXX
 SG_ DIF_a079_adcRefChan m79 : 16|4@1+ (1,0) [0|15] "" Vector__XXX
 SG_ DIF_a079_adcRefHighAvg m79 : 24|16@1+ (1,0) [0|65535] "" Vector__XXX
 SG_ DIF_a087_gtwCarConfig m87 : 16|1@1+ (1,0) [0|1] "" Vector__XXX
 SG_ DIF_a087_gtwTime m87 : 17|1@1+ (1,0) [0|1] "" Vector__XXX
 SG_ DIF_a087_gtwUpdateStatus m87 : 18|1@1+ (1,0) [0|1] "" Vector__XXX
 SG_ DIF_a087_gearControl m87 : 19|1@1+ (1,0) [0|1] "" Vector__XXX
 SG_ DIF_a087_carState m87 : 20|1@1+ (1,0) [0|1] "" Vector__XXX
 SG_ DIF_a090_reason m90 : 16|1@1+ (1,0) [0|1] "" Vector__XXX
 SG_ DIF_a090_systemState m90 : 17|1@1+ (1,0) [0|1] "" Vector__XXX
 SG_ DIF_a090_state m90 : 18|1@1+ (1,0) [0|1] "" Vector__XXX
 SG_ DIF_a090_locState m90 : 19|1@1+ (1,0) [0|1] "" Vector__XXX
 SG_ DIF_a090_state2 m90 : 20|1@1+ (1,0) [0|1] "" Vector__XXX
 SG_ DIF_a090_state4 m90 : 21|1@1+ (1,0) [0|1] "" Vector__XXX
 SG_ DIF_a091_ESP_brakeTorque m91 : 16|1@1+ (1,0) [0|1] "" Vector__XXX
 SG_ DIF_a091_ESP_wheelSpeeds m91 : 17|1@1+ (1,0) [0|1] "" Vector__XXX
 SG_ DIF_a091_ESP_wheelRotation m91 : 18|1@1+ (1,0) [0|1] "" Vector__XXX
 SG_ DIF_a091_ESP_motorLimits m91 : 19|1@1+ (1,0) [0|1] "" Vector__XXX
 SG_ DIF_a091_ESP_offsets m91 : 20|1@1+ (1,0) [0|1] "" Vector__XXX
 SG_ DIF_a091_ESP_status m91 : 21|1@1+ (1,0) [0|1] "" Vector__XXX
 SG_ DIF_a091_ESP_party3 m91 : 22|1@1+ (1,0) [0|1] "" Vector__XXX
 SG_ DIF_a091_ESP_redundantBrakingSta m91 : 23|1@1+ (1,0) [0|1] "" Vector__XXX
 SG_ DIF_a092_bmsStatus m92 : 16|1@1+ (1,0) [0|1] "" Vector__XXX
 SG_ DIF_a092_bmsDriveLimits m92 : 17|1@1+ (1,0) [0|1] "" Vector__XXX
 SG_ DIF_a092_bmsHvBusStatus m92 : 18|1@1+ (1,0) [0|1] "" Vector__XXX
 SG_ DIF_a092_bmsPowerAvailable m92 : 19|1@1+ (1,0) [0|1] "" Vector__XXX
 SG_ DIF_a092_bmsBmbMinMax m92 : 20|1@1+ (1,0) [0|1] "" Vector__XXX
 SG_ DIF_a092_bmsSocStatus m92 : 21|1@1+ (1,0) [0|1] "" Vector__XXX
 SG_ DIF_a092_bmsThermalStatus m92 : 22|1@1+ (1,0) [0|1] "" Vector__XXX
 SG_ DIF_a092_bmsCtrStatus m92 : 23|1@1+ (1,0) [0|1] "" Vector__XXX
 SG_ DIF_a092_bmsVoltageRegGain m92 : 24|1@1+ (1,0) [0|1] "" Vector__XXX
 SG_ DIF_a092_bmsPackConfig m92 : 25|1@1+ (1,0) [0|1] "" Vector__XXX
 SG_ DIF_a092_bmsSystemStatus m92 : 26|1@1+ (1,0) [0|1] "" Vector__XXX
 SG_ DIF_a096_const_fast m96 : 16|1@1+ (1,0) [0|1] "" Vector__XXX
 SG_ DIF_a096_text_fast m96 : 17|1@1+ (1,0) [0|1] "" Vector__XXX
 SG_ DIF_a096_text_flash m96 : 18|1@1+ (1,0) [0|1] "" Vector__XXX
 SG_ DIF_a096_mem_data m96 : 19|1@1+ (1,0) [0|1] "" Vector__XXX
 SG_ DIF_a096_mem_regs m96 : 20|1@1+ (1,0) [0|1] "" Vector__XXX
 SG_ DIF_a096_boot_flash m96 : 21|1@1+ (1,0) [0|1] "" Vector__XXX
 SG_ DIF_a096_word1 m96 : 24|16@1+ (1,0) [0|65535] "" Vector__XXX
 SG_ DIF_a096_word2 m96 : 40|16@1+ (1,0) [0|65535] "" Vector__XXX
 SG_ DIF_a097_errorType m97 : 16|3@1+ (1,0) [0|7] "" Vector__XXX
 SG_ DIF_a097_lineNumber m97 : 24|16@1+ (1,0) [0|65535] "" Vector__XXX
 SG_ DIF_a097_argument m97 : 40|16@1+ (1,0) [0|65535] "" Vector__XXX
 SG_ DIF_a098_pwmCount m98 : 16|16@1+ (1,0) [0|65535] "" Vector__XXX
 SG_ DIF_a098_fluxState m98 : 32|4@1+ (1,0) [0|15] "" Vector__XXX
 SG_ DIF_a103_fluidTorDeltaT m103 : 16|8@1- (2.007874,68.2677154541) [-188.740156546|323.267713454] "" Vector__XXX
 SG_ DIF_a103_noFlowDetected m103 : 24|1@1+ (1,0) [0|1] "" Vector__XXX
 SG_ DIF_a103_lowFlowDetected m103 : 25|1@1+ (1,0) [0|1] "" Vector__XXX
 SG_ DIF_a103_fluidImplausible m103 : 26|1@1+ (1,0) [0|1] "" Vector__XXX
 SG_ DIF_a103_inverterTemp m103 : 27|8@1- (2.007874,68.2677154541) [-188.740156546|323.267713454] "" Vector__XXX
 SG_ DIF_a103_rmsCurrent m103 : 35|10@1- (12.8199605942,0) [-6563.81982423|6550.99986364] "" Vector__XXX
 SG_ DIF_a103_ambientTemp m103 : 45|7@1- (1.5873016119,11.1111106873) [-90.4761924743|111.111112237] "" Vector__XXX
 SG_ DIF_a103_sensorTempEst m103 : 52|8@1- (1.25984251499,40.31496) [-120.944881919|200.314959404] "" Vector__XXX
 SG_ DIF_a107_fpgaVersion m107 : 16|16@1+ (1,0) [0|65535] "" Vector__XXX
 SG_ DIF_a107_fpgaBootVersion m107 : 32|16@1+ (1,0) [0|65535] "" Vector__XXX
 SG_ DIF_a107_fpgaMasterActive m107 : 48|1@1+ (1,0) [0|1] "" Vector__XXX
 SG_ DIF_a107_fpgaFaultActive m107 : 49|1@1+ (1,0) [0|1] "" Vector__XXX
 SG_ DIF_a107_fpgaWarningActive m107 : 50|1@1+ (1,0) [0|1] "" Vector__XXX
 SG_ DIF_a108_fromState m108 : 16|8@1+ (1,0) [0|255] "" Vector__XXX
 SG_ DIF_a108_toState m108 : 24|8@1+ (1,0) [0|255] "" Vector__XXX
 SG_ DIF_a108_blockingAlert m108 : 32|8@1+ (1,0) [0|255] "" Vector__XXX
 SG_ DIF_a110_EPBL_status m110 : 16|1@1+ (1,0) [0|1] "" Vector__XXX
 SG_ DIF_a110_EPBR_status m110 : 17|1@1+ (1,0) [0|1] "" Vector__XXX
 SG_ DIF_a110_EPBL_autonomyHealth m110 : 18|1@1+ (1,0) [0|1] "" Vector__XXX
 SG_ DIF_a110_EPBR_autonomyHealth m110 : 19|1@1+ (1,0) [0|1] "" Vector__XXX
 SG_ DIF_a111_phAcalib m111 : 16|16@1+ (1,0) [0|65535] "" Vector__XXX
 SG_ DIF_a111_phBcalib m111 : 32|16@1+ (1,0) [0|65535] "" Vector__XXX
 SG_ DIF_a112_pwmSwitching m112 : 16|1@1+ (1,0) [0|1] "" Vector__XXX
 SG_ DIF_a112_gdicResetLine m112 : 17|1@1+ (1,0) [0|1] "" Vector__XXX
 SG_ DIF_a112_allOffSafeState m112 : 18|1@1+ (1,0) [0|1] "" Vector__XXX
 SG_ DIF_a112_ls3psSafeState m112 : 19|1@1+ (1,0) [0|1] "" Vector__XXX
 SG_ DIF_a112_hs3psSafeState m112 : 20|1@1+ (1,0) [0|1] "" Vector__XXX
 SG_ DIF_a112_modulationIndex m112 : 21|11@1+ (0.00048828125,0) [0|0.99951171875] "" Vector__XXX
 SG_ DIF_a113_heatsink1Temp m113 : 16|16@1- (0.1,0) [-3276.8|3276.7] "" Vector__XXX
 SG_ DIF_a113_heatsink2Temp m113 : 32|16@1- (0.1,0) [-3276.8|3276.7] "" Vector__XXX
 SG_ DIF_a113_heatsink3Temp m113 : 48|16@1- (0.1,0) [-3276.8|3276.7] "" Vector__XXX
 SG_ DIF_a117_torque m117 : 16|1@1+ (1,0) [0|1] "" Vector__XXX
 SG_ DIF_a117_slaveCommand m117 : 17|1@1+ (1,0) [0|1] "" Vector__XXX
 SG_ DIF_a117_power m117 : 18|1@1+ (1,0) [0|1] "" Vector__XXX
 SG_ DIF_a117_slaveCommand2 m117 : 19|1@1+ (1,0) [0|1] "" Vector__XXX
 SG_ DIF_a117_speed m117 : 20|1@1+ (1,0) [0|1] "" Vector__XXX
 SG_ DIF_a117_chassisControl m117 : 21|1@1+ (1,0) [0|1] "" Vector__XXX
 SG_ DIF_a117_systemStatus m117 : 22|1@1+ (1,0) [0|1] "" Vector__XXX
 SG_ DIF_a117_temperature m117 : 23|1@1+ (1,0) [0|1] "" Vector__XXX
 SG_ DIF_a117_vehicle m117 : 24|1@1+ (1,0) [0|1] "" Vector__XXX
 SG_ DIF_a117_AddTcLimit m117 : 26|1@1+ (1,0) [0|1] "" Vector__XXX
 SG_ DIF_a117_dixCommand m117 : 27|1@1+ (1,0) [0|1] "" Vector__XXX
 SG_ DIF_a117_odometerStatus m117 : 30|1@1+ (1,0) [0|1] "" Vector__XXX
 SG_ DIF_a119_hvpFaults m119 : 16|1@1+ (1,0) [0|1] "" Vector__XXX
 SG_ DIF_a120_dcLinkInfo m120 : 16|1@1+ (1,0) [0|1] "" Vector__XXX
 SG_ DIF_a121_badRegReason m121 : 16|3@1+ (1,0) [0|7] "" Vector__XXX
 SG_ DIF_a121_torqueDelta m121 : 19|13@1- (0.25,0) [-1024|1023.75] "" Vector__XXX
 SG_ DIF_a121_badCurrent m121 : 32|16@1- (0.1,0) [-3276.8|3276.7] "" Vector__XXX
 SG_ DIF_a121_badFlux m121 : 48|16@1+ (0.0001,0) [0|6.5535] "" Vector__XXX
 SG_ DIF_a123_lossReason m123 : 16|3@1+ (1,0) [0|7] "" Vector__XXX
 SG_ DIF_a123_busVoltage m123 : 19|6@1+ (4,250) [250|502] "" Vector__XXX
 SG_ DIF_a123_badFlux m123 : 25|7@1+ (0.0015,0) [0|0.1905] "" Vector__XXX
 SG_ DIF_a123_lossRequest m123 : 32|7@1+ (0.1,0) [0|12.7] "" Vector__XXX
 SG_ DIF_a123_badCurrent m123 : 39|9@1- (10,0) [-2560|2550] "" Vector__XXX
 SG_ DIF_a123_motorRPM m123 : 48|8@1- (150,0) [-19200|19050] "" Vector__XXX
 SG_ DIF_a123_varianceD m123 : 56|4@1+ (20,0) [0|300] "" Vector__XXX
 SG_ DIF_a123_varianceQ m123 : 60|4@1+ (20,0) [0|300] "" Vector__XXX
 SG_ DIF_a126_limpReason m126 : 16|6@1+ (1,0) [0|63] "" Vector__XXX
 SG_ DIF_a127_gpoReason m127 : 16|4@1+ (1,0) [0|15] "" Vector__XXX
 SG_ DIF_a127_temp m127 : 24|16@1- (0.1,0) [-3276.8|3276.7] "" Vector__XXX
 SG_ DIF_a133_capacitorTemp m133 : 16|16@1- (0.1,0) [-3276.8|3276.7] "" Vector__XXX
 SG_ DIF_a133_badValue1 m133 : 32|16@1- (0.1,0) [-3276.8|3276.7] "" Vector__XXX
 SG_ DIF_a133_badValue2 m133 : 48|16@1- (0.1,0) [-3276.8|3276.7] "" Vector__XXX
 SG_ DIF_a134_wheelSpeedDiffFrL m134 : 16|12@1- (0.0625,0) [-128|127.9375] "" Vector__XXX
 SG_ DIF_a134_wheelSpeedDiffFrR m134 : 28|12@1- (0.0625,0) [-128|127.9375] "" Vector__XXX
 SG_ DIF_a134_wheelSpeedDiffReL m134 : 40|12@1- (0.0625,0) [-128|127.9375] "" Vector__XXX
 SG_ DIF_a134_wheelSpeedDiffReR m134 : 52|12@1- (0.0625,0) [-128|127.9375] "" Vector__XXX
 SG_ DIF_a136_spiError_BL m136 : 16|1@1+ (1,0) [0|1] "" Vector__XXX
 SG_ DIF_a136_crcError_BL m136 : 17|1@1+ (1,0) [0|1] "" Vector__XXX
 SG_ DIF_a136_busyError_BL m136 : 18|1@1+ (1,0) [0|1] "" Vector__XXX
 SG_ DIF_a136_spiError_BH m136 : 19|1@1+ (1,0) [0|1] "" Vector__XXX
 SG_ DIF_a136_crcError_BH m136 : 20|1@1+ (1,0) [0|1] "" Vector__XXX
 SG_ DIF_a136_busyError_BH m136 : 21|1@1+ (1,0) [0|1] "" Vector__XXX
 SG_ DIF_a136_spiError_CL m136 : 22|1@1+ (1,0) [0|1] "" Vector__XXX
 SG_ DIF_a136_crcError_CL m136 : 23|1@1+ (1,0) [0|1] "" Vector__XXX
 SG_ DIF_a136_busyError_CL m136 : 24|1@1+ (1,0) [0|1] "" Vector__XXX
 SG_ DIF_a136_spiError_CH m136 : 25|1@1+ (1,0) [0|1] "" Vector__XXX
 SG_ DIF_a136_crcError_CH m136 : 26|1@1+ (1,0) [0|1] "" Vector__XXX
 SG_ DIF_a136_busyError_CH m136 : 27|1@1+ (1,0) [0|1] "" Vector__XXX
 SG_ DIF_a136_spiError_AL m136 : 28|1@1+ (1,0) [0|1] "" Vector__XXX
 SG_ DIF_a136_crcError_AL m136 : 29|1@1+ (1,0) [0|1] "" Vector__XXX
 SG_ DIF_a136_busyError_AL m136 : 30|1@1+ (1,0) [0|1] "" Vector__XXX
 SG_ DIF_a136_spiError_AH m136 : 31|1@1+ (1,0) [0|1] "" Vector__XXX
 SG_ DIF_a136_crcError_AH m136 : 32|1@1+ (1,0) [0|1] "" Vector__XXX
 SG_ DIF_a136_busyError_AH m136 : 33|1@1+ (1,0) [0|1] "" Vector__XXX
 SG_ DIF_a144_autopilot m144 : 16|1@1+ (1,0) [0|1] "" Vector__XXX
 SG_ DIF_a144_chassisType m144 : 17|1@1+ (1,0) [0|1] "" Vector__XXX
 SG_ DIF_a144_drivetrainType m144 : 18|1@1+ (1,0) [0|1] "" Vector__XXX
 SG_ DIF_a144_packEnergy m144 : 19|1@1+ (1,0) [0|1] "" Vector__XXX
 SG_ DIF_a144_packPerformanceDeviatio m144 : 20|1@1+ (1,0) [0|1] "" Vector__XXX
 SG_ DIF_a144_performancePackage m144 : 21|1@1+ (1,0) [0|1] "" Vector__XXX
 SG_ DIF_a144_vdcType m144 : 22|1@1+ (1,0) [0|1] "" Vector__XXX
 SG_ DIF_a144_brakeHWType m144 : 23|1@1+ (1,0) [0|1] "" Vector__XXX
 SG_ DIF_a144_inverterHardware m144 : 24|1@1+ (1,0) [0|1] "" Vector__XXX
 SG_ DIF_a144_cabinPTCHeaterType m144 : 25|1@1+ (1,0) [0|1] "" Vector__XXX
 SG_ DIF_a144_frunkLatchType m144 : 26|1@1+ (1,0) [0|1] "" Vector__XXX
 SG_ DIF_a144_platformMaxBusVoltage m144 : 27|1@1+ (1,0) [0|1] "" Vector__XXX
 SG_ DIF_a144_oilPump1HwType m144 : 28|1@1+ (1,0) [0|1] "" Vector__XXX
 SG_ DIF_a144_oilPump2HwType m144 : 29|1@1+ (1,0) [0|1] "" Vector__XXX
 SG_ DIF_a144_heatsinkType m144 : 30|1@1+ (1,0) [0|1] "" Vector__XXX
 SG_ DIF_a144_softPerformanceLimit m144 : 31|1@1+ (1,0) [0|1] "" Vector__XXX
 SG_ DIF_a144_brakeActuationType m144 : 32|1@1+ (1,0) [0|1] "" Vector__XXX
 SG_ DIF_a144_dasHw m144 : 33|1@1+ (1,0) [0|1] "" Vector__XXX
 SG_ DIF_a144_powerLiftgateType m144 : 34|1@1+ (1,0) [0|1] "" Vector__XXX
 SG_ DIF_a144_chassisSubType m144 : 35|1@1+ (1,0) [0|1] "" Vector__XXX
 SG_ DIF_a144_autonomyFeatureType m144 : 36|1@1+ (1,0) [0|1] "" Vector__XXX
 SG_ DIF_a147_overtorque1UsedCount m147 : 16|8@1+ (1,0) [0|255] "" Vector__XXX
 SG_ DIF_a147_overtorque2UsedCount m147 : 24|10@1+ (1,0) [0|1023] "" Vector__XXX
 SG_ DIF_a147_accumulatedWear m147 : 34|10@1+ (0.005,0) [0|5.115] "" Vector__XXX
 SG_ DIF_a147_wearIsValid m147 : 44|1@1+ (1,0) [0|1] "" Vector__XXX
 SG_ DIF_a149_flow m149 : 16|8@1+ (0.1,0) [0|25.5] "" Vector__XXX
 SG_ DIF_a149_voltage m149 : 24|8@1+ (0.1,0) [0|25.5] "" Vector__XXX
 SG_ DIF_a149_temperature m149 : 32|8@1+ (1,-40) [-40|215] "" Vector__XXX
 SG_ DIF_a149_state m149 : 40|3@1+ (1,0) [0|7] "" Vector__XXX
 SG_ DIF_a149_fluidTempSNA m149 : 43|1@1+ (1,0) [0|1] "" Vector__XXX
 SG_ DIF_a149_insufficientFlow m149 : 44|1@1+ (1,0) [0|1] "" Vector__XXX
 SG_ DIF_a149_motorOpenPhase m149 : 45|1@1+ (1,0) [0|1] "" Vector__XXX
 SG_ DIF_a149_motorShorted m149 : 46|1@1+ (1,0) [0|1] "" Vector__XXX
 SG_ DIF_a149_motorFlowSNA m149 : 47|1@1+ (1,0) [0|1] "" Vector__XXX
 SG_ DIF_a149_responseError m149 : 48|1@1+ (1,0) [0|1] "" Vector__XXX
 SG_ DIF_a149_pcbaID m149 : 49|1@1+ (1,0) [0|1] "" Vector__XXX
 SG_ DIF_a150_vBatRawMinusFiltered m150 : 16|10@1- (1,0) [-512|511] "" Vector__XXX
 SG_ DIF_a150_vBatFilteredRate m150 : 32|8@1- (100,0) [-12800|12700] "" Vector__XXX
 SG_ DIF_a150_elapsedMs m150 : 40|8@1+ (1,0) [0|255] "" Vector__XXX
 SG_ DIF_a150_energy m150 : 48|16@1+ (1,0) [0|65535] "" Vector__XXX
 SG_ DIF_a152_errorType m152 : 16|3@1+ (1,0) [0|7] "" Vector__XXX
 SG_ DIF_a152_frameId m152 : 24|8@1+ (1,0) [0|255] "" Vector__XXX
 SG_ DIF_a152_badValue m152 : 32|8@1+ (1,0) [0|255] "" Vector__XXX
 SG_ DIF_a152_expectedValue m152 : 40|8@1+ (1,0) [0|255] "" Vector__XXX
 SG_ DIF_a154_motorRPM m154 : 16|16@1- (1,0) [-32768|32767] "" Vector__XXX
 SG_ DIF_a154_phaseError m154 : 32|8@1- (0.004,0) [-0.512|0.508] "" Vector__XXX
 SG_ DIF_a154_commonGain m154 : 40|8@1+ (0.02,0) [0|5.1] "" Vector__XXX
 SG_ DIF_a154_noCalibration m154 : 48|1@1+ (1,0) [0|1] "" Vector__XXX
 SG_ DIF_a154_noPhaseLock m154 : 49|1@1+ (1,0) [0|1] "" Vector__XXX
 SG_ DIF_a154_noCarrier m154 : 50|1@1+ (1,0) [0|1] "" Vector__XXX
 SG_ DIF_a154_notReady m154 : 51|1@1+ (1,0) [0|1] "" Vector__XXX
 SG_ DIF_a154_errorTableInvalid m154 : 52|1@1+ (1,0) [0|1] "" Vector__XXX
 SG_ DIF_a154_carrierOffset m154 : 53|1@1+ (1,0) [0|1] "" Vector__XXX
 SG_ DIF_a154_trackerIrrational m154 : 54|1@1+ (1,0) [0|1] "" Vector__XXX
 SG_ DIF_a154_claMIA m154 : 55|1@1+ (1,0) [0|1] "" Vector__XXX
 SG_ DIF_a155_sensors m155 : 16|1@1+ (1,0) [0|1] "" Vector__XXX
 SG_ DIF_a155_coolant m155 : 17|1@1+ (1,0) [0|1] "" Vector__XXX
 SG_ DIF_a155_LVPowerState m155 : 18|1@1+ (1,0) [0|1] "" Vector__XXX
 SG_ DIF_a155_vehicleStatus m155 : 19|1@1+ (1,0) [0|1] "" Vector__XXX
 SG_ DIF_a155_status m155 : 20|1@1+ (1,0) [0|1] "" Vector__XXX
 SG_ DIF_a155_leftDoorStatus m155 : 21|1@1+ (1,0) [0|1] "" Vector__XXX
 SG_ DIF_a155_rightDoorStatus m155 : 22|1@1+ (1,0) [0|1] "" Vector__XXX
 SG_ DIF_a155_vcleftSwitchStatus m155 : 23|1@1+ (1,0) [0|1] "" Vector__XXX
 SG_ DIF_a155_restraintStatus m155 : 24|1@1+ (1,0) [0|1] "" Vector__XXX
 SG_ DIF_a155_systemStatus m155 : 25|1@1+ (1,0) [0|1] "" Vector__XXX
 SG_ DIF_a155_prndStatus m155 : 26|1@1+ (1,0) [0|1] "" Vector__XXX
 SG_ DIF_a155_liftgateStatus m155 : 27|1@1+ (1,0) [0|1] "" Vector__XXX
 SG_ DIF_a157_RCM_inertial1 m157 : 16|1@1+ (1,0) [0|1] "" Vector__XXX
 SG_ DIF_a157_RCM_inertial2 m157 : 17|1@1+ (1,0) [0|1] "" Vector__XXX
 SG_ DIF_a158_IBST_party1 m158 : 16|1@1+ (1,0) [0|1] "" Vector__XXX
 SG_ DIF_a158_BUS1_IBST_status m158 : 17|1@1+ (1,0) [0|1] "" Vector__XXX
 SG_ DIF_a158_BUS2_IBST_status m158 : 18|1@1+ (1,0) [0|1] "" Vector__XXX
 SG_ DIF_a158_IBST_redundantBrakingSt m158 : 19|1@1+ (1,0) [0|1] "" Vector__XXX
 SG_ DIF_a160_vBatRawMinusFiltered m160 : 16|10@1- (1,0) [-512|511] "" Vector__XXX
 SG_ DIF_a160_vBatFilteredRate m160 : 32|8@1- (100,0) [-12800|12700] "" Vector__XXX
 SG_ DIF_a160_elapsedMs m160 : 40|8@1+ (1,0) [0|255] "" Vector__XXX
 SG_ DIF_a160_energy m160 : 48|16@1+ (1,0) [0|65535] "" Vector__XXX
 SG_ DIF_a161_EPAS3P_sysStatus m161 : 16|1@1+ (1,0) [0|1] "" Vector__XXX
 SG_ DIF_a161_EPAS3P_angleCalib m161 : 17|1@1+ (1,0) [0|1] "" Vector__XXX
 SG_ DIF_a172_statorTemp1 m172 : 16|16@1- (0.1,0) [-3276.8|3276.7] "" Vector__XXX
 SG_ DIF_a172_statorTemp2 m172 : 32|16@1- (0.1,0) [-3276.8|3276.7] "" Vector__XXX
 SG_ DIF_a202_reason m202 : 16|4@1+ (1,0) [0|15] "" Vector__XXX
 SG_ DIF_a202_movement m202 : 20|9@1+ (0.005,0) [0|2.555] "" Vector__XXX
 SG_ DIF_a202_sysStateExitCondition m202 : 32|5@1+ (1,0) [0|31] "" Vector__XXX
 SG_ DIF_a233_missedMsgCount m233 : 16|4@1+ (1,0) [0|15] "" Vector__XXX
 SG_ DIF_a233_serviceModeActive m233 : 20|1@1+ (1,0) [0|1] "" Vector__XXX
 SG_ DIF_a234_PCS_dcdcStatus m234 : 16|1@1+ (1,0) [0|1] "" Vector__XXX
 SG_ DIF_a236_states m236 : 16|1@1+ (1,0) [0|1] "" Vector__XXX
 SG_ DIF_a240_shortedSwitches m240 : 16|6@1+ (1,0) [0|63] "" Vector__XXX
 SG_ DIF_a240_primaryPattern m240 : 22|6@1+ (1,0) [0|63] "" Vector__XXX
 SG_ DIF_a240_secondaryPattern m240 : 28|6@1+ (1,0) [0|63] "" Vector__XXX
 SG_ DIF_a240_fuseA_I2t m240 : 34|6@1+ (8,0) [0|504] "" Vector__XXX
 SG_ DIF_a240_fuseB_I2t m240 : 40|6@1+ (8,0) [0|504] "" Vector__XXX
 SG_ DIF_a240_primaryTimeout m240 : 46|1@1+ (1,0) [0|1] "" Vector__XXX
 SG_ DIF_a240_secondaryTimeout m240 : 47|1@1+ (1,0) [0|1] "" Vector__XXX
 SG_ DIF_a240_primNoCurrentA m240 : 48|1@1+ (1,0) [0|1] "" Vector__XXX
 SG_ DIF_a240_primNoCurrentB m240 : 49|1@1+ (1,0) [0|1] "" Vector__XXX
 SG_ DIF_a240_secNoCurrentA m240 : 50|1@1+ (1,0) [0|1] "" Vector__XXX
 SG_ DIF_a240_secNoCurrentB m240 : 51|1@1+ (1,0) [0|1] "" Vector__XXX
 SG_ DIF_a240_primaryDutyCycle m240 : 52|5@1+ (1,0) [0|31] "" Vector__XXX
 SG_ DIF_a240_secondaryDutyCycle m240 : 57|5@1+ (1,0) [0|31] "" Vector__XXX
 SG_ DIF_a240_confNoCurrentDetected m240 : 62|1@1+ (1,0) [0|1] "" Vector__XXX
 SG_ DIF_a240_secondaryStrategy3ps m240 : 63|1@1+ (1,0) [0|1] "" Vector__XXX
 SG_ DIF_a242_RotorOffset m242 : 16|1@1+ (1,0) [0|1] "" Vector__XXX
 SG_ DIF_a242_RotorFlux m242 : 17|1@1+ (1,0) [0|1] "" Vector__XXX
 SG_ DIF_a242_ResolverError m242 : 18|1@1+ (1,0) [0|1] "" Vector__XXX
 SG_ DIF_a244_desatHighSide m244 : 16|1@1+ (1,0) [0|1] "" Vector__XXX
 SG_ DIF_a244_desatLowSide m244 : 17|1@1+ (1,0) [0|1] "" Vector__XXX
 SG_ DIF_a244_singleSwitchShort m244 : 18|1@1+ (1,0) [0|1] "" Vector__XXX
 SG_ DIF_a244_flybackFault m244 : 19|1@1+ (1,0) [0|1] "" Vector__XXX
 SG_ DIF_a244_postShortTestFailed m244 : 20|1@1+ (1,0) [0|1] "" Vector__XXX
 SG_ DIF_a244_udsSelfTest m244 : 21|1@1+ (1,0) [0|1] "" Vector__XXX
 SG_ DIF_a244_irSensorV m244 : 24|6@1+ (0.1,0) [0|6.3] "" Vector__XXX
 SG_ DIF_a244_gateDriveICUndervoltage m244 : 30|1@1+ (1,0) [0|1] "" Vector__XXX
 SG_ DIF_a244_plausibleSingleSwitchSh m244 : 31|1@1+ (1,0) [0|1] "" Vector__XXX
 SG_ DIF_a244_delay m244 : 32|16@1+ (1,0) [0|65535] "" Vector__XXX
 SG_ DIF_a246_atSpeedDIResetCount m246 : 16|4@1+ (1,4294967295) [4294967295|4294967310] "" Vector__XXX
 SG_ DIF_a246_didPMCauseSwitchOf_0001 m246 : 20|1@1+ (1,0) [0|1] "" Vector__XXX
 SG_ DIF_a246_didPMCauseSwitchOffPath m246 : 21|1@1+ (1,0) [0|1] "" Vector__XXX
 SG_ DIF_a246_currentSensorRational m246 : 22|1@1+ (1,0) [0|1] "" Vector__XXX
 SG_ DIF_a246_observerDetectedSw_0001 m246 : 23|1@1+ (1,0) [0|1] "" Vector__XXX
 SG_ DIF_a246_observerDetectedSwitchO m246 : 24|1@1+ (1,0) [0|1] "" Vector__XXX
 SG_ DIF_a246_hvIsGood m246 : 25|1@1+ (1,0) [0|1] "" Vector__XXX
 SG_ DIF_a246_lvIsGood m246 : 26|1@1+ (1,0) [0|1] "" Vector__XXX
 SG_ DIF_a246_codeBranch m246 : 27|2@1+ (1,0) [0|3] "" Vector__XXX
 SG_ DIF_a246_motorRPM m246 : 32|8@1- (150,0) [-19200|19050] "" Vector__XXX
 SG_ DIF_a246_eepromOffsetIa m246 : 40|6@1- (0.763,0) [-24.416|23.653] "" Vector__XXX
 SG_ DIF_a246_eepromOffsetIb m246 : 48|6@1- (0.763,0) [-24.416|23.653] "" Vector__XXX
 SG_ DIF_a246_soptPreviouslyPassed m246 : 54|1@1+ (1,0) [0|1] "" Vector__XXX
 SG_ DIF_a246_lowSpeedRecoveryEnabled m246 : 55|1@1+ (1,0) [0|1] "" Vector__XXX
 SG_ DIF_a247_rotorOffsetEst m247 : 16|10@1- (0.05,0) [-25.6|25.55] "" Vector__XXX
 SG_ DIF_a247_motorRPM m247 : 32|16@1- (1,0) [-32768|32767] "" Vector__XXX
 SG_ DIF_a247_torqueMotor m247 : 48|16@1- (1,0) [-32768|32767] "" Vector__XXX
 SG_ DIF_a251_oilFlow m251 : 16|8@1+ (0.1,0) [0|25.5] "" Vector__XXX
 SG_ DIF_a251_oilTemperature m251 : 24|8@1+ (1,-40) [-40|215] "" Vector__XXX
 SG_ DIF_a251_dcVoltage m251 : 32|8@1+ (0.3,0) [0|76.5] "" Vector__XXX
 SG_ DIF_a251_dcCurrent m251 : 40|8@1+ (0.1,0) [0|25.5] "" Vector__XXX
 SG_ DIF_a251_phaseCurrent m251 : 48|8@1+ (0.1,0) [0|25.5] "" Vector__XXX
 SG_ DIF_a251_leadAngle m251 : 56|4@1+ (1.875,0) [0|28.125] "" Vector__XXX
 SG_ DIF_a251_reason m251 : 60|3@1+ (1,0) [0|7] "" Vector__XXX
 SG_ DIF_a253_voltage m253 : 16|14@1+ (0.002,0) [0|32.766] "" Vector__XXX
 SG_ DIF_a253_reason m253 : 30|2@1+ (1,0) [0|3] "" Vector__XXX

CM_ BO_ 697 "Driver assistance computer message: control";
CM_ SG_ 697 DAS_setSpeed "Detects the commanded Traffic Aware Cruise Control (TACC) or Autopilot set speed for the Drive Inverter (DI).";
CM_ SG_ 697 DAS_accState "Reports the state of Adaptive Cruise Control (ACC), Traffic-Aware Cruise Control (TACC), and Autopark / Summon.";
CM_ SG_ 697 DAS_aebEvent "Driver assistance computer: aeb event";
CM_ SG_ 697 DAS_jerkMin "Reports the minimum allowed jerk the Drive Inverter (DI) can generate to reach the commanded set speed.";
CM_ SG_ 697 DAS_jerkMax "Reports the maximum allowed jerk the Drive Inverter (DI) can generate to reach the commanded set speed.";
CM_ SG_ 697 DAS_accelMin "Reports the minimum acceleration the drive inverter can apply to reach the commanded set speed.";
CM_ SG_ 697 DAS_accelMax "Reports the maximum acceleration the drive inverter can apply to reach the commanded set speed.";
CM_ SG_ 697 DAS_controlCounter "Driver assistance computer: control counter";
CM_ SG_ 697 DAS_controlChecksum "Driver assistance computer: control checksum";
CM_ BO_ 2040 "Driver assistance computer message: gps status";
CM_ SG_ 2040 DAS_gpsStatusMultiplexer "Driver assistance computer: gps status multiplexer";
CM_ SG_ 2040 DAS_gpsTransportModeState "Indicates if the transport mode algorithm detects the car is in transport mode.";
CM_ SG_ 2040 DAS_gpsSatsInUseHardware "The number of GPS satellites currently in use by hardware solution.";
CM_ SG_ 2040 DAS_gpsRejectingSatData "Indicates whether or not the GPS is rejecting satellites due to poor signal.";
CM_ SG_ 2040 DAS_gpsWheelsOffMotionDetected "Indicates that wheels-off acceleration detected";
CM_ SG_ 2040 DAS_gpsFixTypeHardware "The fix type of the GPS receiver, see u-blox M8 spec, section 33.13.1.1";
CM_ SG_ 2040 DAS_gpsRawxEnabled "GPS receiver has raw messages enabled";
CM_ SG_ 2040 DAS_gpsRxmRawxMia "Driver assistance computer: gps rxm rawx mia";
CM_ SG_ 2040 DAS_gpsRxmSfrbxMia "Driver assistance computer: gps rxm sfrbx mia";
CM_ SG_ 2040 DAS_gpsEsfMeasMia "AP is not receiving EsfMeas message from GPS receiver";
CM_ SG_ 2040 DAS_gpsEsfRawMia "AP is not receiving EsfRaw message from GPS receiver";
CM_ SG_ 2040 DAS_gpsNavStatusMia "AP is not receiving NavStatus message from GPS receiver";
CM_ SG_ 2040 DAS_gpsSoftwareConfigured "Software GPS solution is allowed";
CM_ SG_ 2040 DAS_gpsSoftwareUsed "Software GPS solution is actively used";
CM_ SG_ 2040 DAS_gpsSoftwareFastStartReady "Software GPS solution could use fast start mechanism at boot-up";
CM_ SG_ 2040 DAS_gpsSatsInUseSoftware "The number of GPS satellites currently in use by software solution on SOC-A.";
CM_ SG_ 2040 DAS_gpsFixTypeSoftware "The fix type of the GPS software solution on SOC-A.";
CM_ SG_ 2040 DAS_gpsCWJammingInidcator "Level of continuous wave jamming detected by GPS hardware";
CM_ SG_ 2040 DAS_gpsJammingState "State of GPS jamming monitor";
CM_ SG_ 2040 DAS_gpsSpoofDetectorState "Instantaneous state of GPS spoofing detector. Detection only triggers at the transition from real to suspected spoof signal.";
CM_ SG_ 2040 DAS_gpsInvalidMsgPercentage "Percentage of messages received by AP from GPS receiver that were invalid. Calculated over up-to 10s window.";
CM_ SG_ 2040 DAS_gnssConstellationsState "Indicates if GNSS constellations match expected configuration.";
CM_ SG_ 2040 DAS_gpsReceiverNoiseLevel "General noise level of GPS receiver.";
CM_ SG_ 2040 DAS_gpsAutomaticGainControl "Automatic Gain Control of GPS receiver.";
CM_ SG_ 2040 DAS_gpsPreviousPositionDeltaHw "Change in position of two consecutive location outputs from GPS hardware solution.";
CM_ SG_ 2040 DAS_gpsPreviousPositionDeltaSw "Change in position of two consecutive location outputs from GPS software solution.";
CM_ SG_ 2040 DAS_gpsNmeaDispatchFailureCount "Number of GPS messages dropped by AP without sending over to UI. Calculated over up-to 10s window.";
CM_ SG_ 2040 DAS_gnssMaxInstantaneousCnorGps "Maximum carrier-to-noise ratio among all satellites from GPS constellation.";
CM_ SG_ 2040 DAS_gnssMaxInstantaneousCnorGal "Maximum carrier-to-noise ratio among all satellites from GALILEO constellation.";
CM_ SG_ 2040 DAS_gnssMaxInstantaneousCnorBds "Maximum carrier-to-noise ratio among all satellites from BEIDOU constellation.";
CM_ SG_ 2040 DAS_gpsResetReason "When AP resets GPS receiver, this signal indicates the reason why";
CM_ SG_ 2040 DAS_gpsAccuracyHorizontal "Self-reported horizontal GPS accuracy";
CM_ SG_ 2040 DAS_gpsAccuracyVertical "Self-reported vertical GPS accuracy";
CM_ SG_ 2040 DAS_gpsSolutionFallback "GPS solution falling back from software to hardware";
CM_ SG_ 2040 DAS_gpsToMcuSource "This signal exposes which localization solution is being sent to the MCU.";
CM_ SG_ 2040 DAS_gpsSolutionSoc "Reports which System on Chip (SOC) is producing the GPS localization solution.";
CM_ SG_ 2040 DAS_gpsRedundancyActive "Reports whether the GPS Redundancy feature is active on the Autopilot (AP) board. This feature enables either System on Chip (SOC) to publish the Global Navigation Satellite System (GNSS) solution.";
CM_ SG_ 2040 DAS_gpsFixTypeSoftwareSocB "Reports the fix type of the GPS software solution on System on Chip B (SOC-B).";
CM_ SG_ 2040 DAS_gpsSatsInUseSoftwareSocB "Reports the number of GPS satellites currently in use by software solution on System on Chip B (SOC-B).";
CM_ SG_ 2040 DAS_gnssNumSatsGps "Number of satellites visible from GPS constellation.";
CM_ SG_ 2040 DAS_gnssNumSatsGal "Number of satellites visible from GALILEO constellation.";
CM_ SG_ 2040 DAS_gnssNumSatsBds "Number of satellites visible from BEIDOU constellation.";
CM_ SG_ 2040 DAS_gnssAvgInstantaneousCnorGps "Average carrier-to-noise ratio among all satellites from GPS constellation on the high band as reported by the Positioning Engine on SOC-A.";
CM_ SG_ 2040 DAS_gnssAvgInstantaneousCnorGal "Average carrier-to-noise ratio among all satellites from GALILEO constellation on the high band.";
CM_ SG_ 2040 DAS_gnssAvgInstantaneousCnorBds "Average carrier-to-noise ratio among all satellites from BEIDOU constellation on the high band as reported by the Positioning Engine on SOC-A.";
CM_ SG_ 2040 DAS_gnssAvgInstantaneousCnorGpsL "Measures the average carrier-to-noise ratio among all satellites from GPS constellation on the low band as reported by the Positioning Engine on System on Chip A (SOC-A).";
CM_ SG_ 2040 DAS_gnssAvgInstantaneousCnorGalL "Measures the average carrier-to-noise ratio among all satellites from GALILEO constellation on the low band.";
CM_ SG_ 2040 DAS_gnssAvgInstantaneousCnorBdsL "Measures the average carrier-to-noise ratio among all satellites from BEIDOU constellation on the low band as reported by the Positioning Engine on System on Chip A (SOC-A).";
CM_ BO_ 1337 "Driver assistance computer message: info";
CM_ SG_ 1337 DAS_infoIndex "Driver assistance computer: info index";
CM_ SG_ 1337 DAS_infoBuildType "Driver assistance computer: info build type";
CM_ SG_ 1337 DAS_infoBuildConfigID "Driver assistance computer: info build config ID";
CM_ SG_ 1337 DAS_infoHardwareID "Driver assistance computer: info hardware ID";
CM_ SG_ 1337 DAS_infoComponentID "Driver assistance computer: info component ID";
CM_ SG_ 1337 DAS_infoPcbaID "Driver assistance computer: info pcba ID";
CM_ SG_ 1337 DAS_infoAssemblyID "Driver assistance computer: info assembly ID";
CM_ SG_ 1337 DAS_infoUsageID "Driver assistance computer: info usage ID";
CM_ SG_ 1337 DAS_infoSubUsageID "Driver assistance computer: info sub usage ID";
CM_ SG_ 1337 DAS_infoApplicationCRC "Driver assistance computer: info application CRC";
CM_ SG_ 1337 DAS_infoAppGitHashBytes "Driver assistance computer: info app git hash bytes";
CM_ SG_ 1337 DAS_infoBootGitHashBytes "Driver assistance computer: info boot git hash bytes";
CM_ BO_ 569 "Driver assistance computer message: lanes";
CM_ SG_ 569 DAS_leftLaneExists "Driver assistance computer: left lane exists";
CM_ SG_ 569 DAS_rightLaneExists "Driver assistance computer: right lane exists";
CM_ SG_ 569 DAS_virtualLaneWidth "Driver assistance computer: virtual lane width";
CM_ SG_ 569 DAS_virtualLaneViewRange "Driver assistance computer: virtual lane view range";
CM_ SG_ 569 DAS_virtualLaneC0 "Driver assistance computer: virtual lane C0";
CM_ SG_ 569 DAS_virtualLaneC1 "Driver assistance computer: virtual lane C1";
CM_ SG_ 569 DAS_virtualLaneC2 "Driver assistance computer: virtual lane C2";
CM_ SG_ 569 DAS_virtualLaneC3 "Driver assistance computer: virtual lane C3";
CM_ SG_ 569 DAS_leftLineUsage "Driver assistance computer: left line usage";
CM_ SG_ 569 DAS_rightLineUsage "Driver assistance computer: right line usage";
CM_ SG_ 569 DAS_leftFork "Driver assistance computer: left fork";
CM_ SG_ 569 DAS_rightFork "Driver assistance computer: right fork";
CM_ SG_ 569 DAS_lanesCounter "Driver assistance computer: lanes counter";
CM_ BO_ 778 "Driver assistance computer message: object";
CM_ SG_ 778 DAS_objectId "Driver assistance computer: object id";
CM_ SG_ 778 DAS_leadVehType "Driver assistance computer: lead veh type";
CM_ SG_ 778 DAS_leadVehRelevantForControl "Driver assistance computer: lead veh relevant for control";
CM_ SG_ 778 DAS_leadVehDx "Measures the distance to lead vehicle, or vehicle in the ego lane.";
CM_ SG_ 778 DAS_leadVehVxRel "Driver assistance computer: lead veh vx rel";
CM_ SG_ 778 DAS_leadVehDy "Driver assistance computer: lead veh dy";
CM_ SG_ 778 DAS_leadVehId "Driver assistance computer: lead veh id";
CM_ SG_ 778 DAS_leadVeh2Type "Driver assistance computer: lead veh2 type";
CM_ SG_ 778 DAS_leadVeh2RelevantForControl "Driver assistance computer: lead veh2 relevant for control";
CM_ SG_ 778 DAS_leadVeh2Dx "Driver assistance computer: lead veh2 dx";
CM_ SG_ 778 DAS_leadVeh2VxRel "Driver assistance computer: lead veh2 vx rel";
CM_ SG_ 778 DAS_leadVeh2Dy "Driver assistance computer: lead veh2 dy";
CM_ SG_ 778 DAS_leadVeh2Id "Driver assistance computer: lead veh2 id";
CM_ SG_ 778 DAS_leftVehType "Driver assistance computer: left veh type";
CM_ SG_ 778 DAS_leftVehRelevantForControl "Driver assistance computer: left veh relevant for control";
CM_ SG_ 778 DAS_leftVehDx "Driver assistance computer: left veh dx";
CM_ SG_ 778 DAS_leftVehVxRel "Driver assistance computer: left veh vx rel";
CM_ SG_ 778 DAS_leftVehDy "Driver assistance computer: left veh dy";
CM_ SG_ 778 DAS_leftVehId "Driver assistance computer: left veh id";
CM_ SG_ 778 DAS_leftVeh2Type "Driver assistance computer: left veh2 type";
CM_ SG_ 778 DAS_leftVeh2RelevantForControl "Driver assistance computer: left veh2 relevant for control";
CM_ SG_ 778 DAS_leftVeh2Dx "Driver assistance computer: left veh2 dx";
CM_ SG_ 778 DAS_leftVeh2VxRel "Driver assistance computer: left veh2 vx rel";
CM_ SG_ 778 DAS_leftVeh2Dy "Driver assistance computer: left veh2 dy";
CM_ SG_ 778 DAS_leftVeh2Id "Driver assistance computer: left veh2 id";
CM_ SG_ 778 DAS_rightVehType "Driver assistance computer: right veh type";
CM_ SG_ 778 DAS_rightVehRelevantForControl "Driver assistance computer: right veh relevant for control";
CM_ SG_ 778 DAS_rightVehDx "Driver assistance computer: right veh dx";
CM_ SG_ 778 DAS_rightVehVxRel "Driver assistance computer: right veh vx rel";
CM_ SG_ 778 DAS_rightVehDy "Driver assistance computer: right veh dy";
CM_ SG_ 778 DAS_rightVehId "Driver assistance computer: right veh id";
CM_ SG_ 778 DAS_rightVeh2Type "Driver assistance computer: right veh2 type";
CM_ SG_ 778 DAS_rightVeh2RelevantForControl "Driver assistance computer: right veh2 relevant for control";
CM_ SG_ 778 DAS_rightVeh2Dx "Driver assistance computer: right veh2 dx";
CM_ SG_ 778 DAS_rightVeh2VxRel "Driver assistance computer: right veh2 vx rel";
CM_ SG_ 778 DAS_rightVeh2Dy "Driver assistance computer: right veh2 dy";
CM_ SG_ 778 DAS_rightVeh2Id "Driver assistance computer: right veh2 id";
CM_ SG_ 778 DAS_cutinVehType "Driver assistance computer: cutin veh type";
CM_ SG_ 778 DAS_cutinVehRelevantForControl "Driver assistance computer: cutin veh relevant for control";
CM_ SG_ 778 DAS_cutinVehDx "Driver assistance computer: cutin veh dx";
CM_ SG_ 778 DAS_cutinVehVxRel "Driver assistance computer: cutin veh vx rel";
CM_ SG_ 778 DAS_cutinVehDy "Driver assistance computer: cutin veh dy";
CM_ SG_ 778 DAS_cutinVehId "Driver assistance computer: cutin veh id";
CM_ SG_ 778 DAS_roadSignColor "Driver assistance computer: road sign color";
CM_ SG_ 778 DAS_roadSignId "Driver assistance computer: road sign id";
CM_ SG_ 778 DAS_roadSignStopLineDist "Driver assistance computer: road sign stop line dist";
CM_ SG_ 778 DAS_roadSignControlActive "Driver assistance computer: road sign control active";
CM_ SG_ 778 DAS_roadSignSource "Driver assistance computer: road sign source";
CM_ SG_ 778 DAS_roadSignArrow "Driver assistance computer: road sign arrow";
CM_ SG_ 778 DAS_roadSignOrientation "Driver assistance computer: road sign orientation";
CM_ BO_ 781 "Driver assistance computer message: positioning engine status";
CM_ SG_ 781 DAS_positioningEngineStatusMulti "Driver assistance computer: positioning engine status multiplexer";
CM_ SG_ 781 DAS_meoSolverNumRuns "Driver assistance computer: meo solver num runs";
CM_ SG_ 781 DAS_meoSolverReportTerminationTy "Driver assistance computer: meo solver report termination type";
CM_ SG_ 781 DAS_meoSolverReportTotalTimeS "Driver assistance computer: meo solver report total time s";
CM_ SG_ 781 DAS_meoHorizontalAccuracyM "Driver assistance computer: meo horizontal accuracy m";
CM_ SG_ 781 DAS_meoVerticalAccuracyM "Driver assistance computer: meo vertical accuracy m";
CM_ SG_ 781 DAS_meoHeadingAccuracyDeg "Driver assistance computer: meo heading accuracy deg";
CM_ SG_ 781 DAS_meoHeadingValid "Driver assistance computer: meo heading valid";
CM_ SG_ 781 DAS_meoNumSatellitesUsed "Driver assistance computer: meo num satellites used";
CM_ SG_ 781 DAS_meoGpsQualityLevel "Driver assistance computer: meo gps quality level";
CM_ SG_ 781 DAS_meoFixType "Driver assistance computer: meo fix type";
CM_ SG_ 781 DAS_meoResetCount "Driver assistance computer: meo reset count";
CM_ SG_ 781 DAS_lastMeoResetReason "Driver assistance computer: last meo reset reason";
CM_ SG_ 781 DAS_vioMultiGpsSelectedSource "Driver assistance computer: vio multi gps selected source";
CM_ SG_ 781 DAS_vioMultiGpsPeCooldownActive "Driver assistance computer: vio multi gps pe cooldown active";
CM_ SG_ 781 DAS_vioMultiGpsPeSppTdcpConsiste "Driver assistance computer: vio multi gps pe spp tdcp consistent with raw gps";
CM_ SG_ 781 DAS_vioMultiGpsPeMeoConsistentWi "Driver assistance computer: vio multi gps pe meo consistent with raw gps";
CM_ SG_ 781 DAS_vioMultiGpsPeSppTdcpVsR_0001 "Driver assistance computer: vio multi gps pe spp tdcp vs raw gps trans discrep m";
CM_ SG_ 781 DAS_vioMultiGpsPeMeoVsRawGpsTran "Driver assistance computer: vio multi gps pe meo vs raw gps trans discrep m";
CM_ SG_ 781 DAS_vioMultiGpsPeSppTdcpVsRawGps "Driver assistance computer: vio multi gps pe spp tdcp vs raw gps rot discrep deg";
CM_ SG_ 781 DAS_vioMultiGpsPeMeoVsRawGpsRotD "Driver assistance computer: vio multi gps pe meo vs raw gps rot discrep deg";
CM_ SG_ 781 DAS_publishedGpsSource "Driver assistance computer: published gps source";
CM_ SG_ 781 DAS_bluefinEnabled "Driver assistance computer: bluefin enabled";
CM_ SG_ 781 DAS_orioleDisabled "Driver assistance computer: oriole disabled";
CM_ SG_ 781 DAS_disableMonarch "Indicates the state of the Autopilot (AP) monarch positioning engine.";
CM_ BO_ 299 "Driver assistance computer message: smart shift";
CM_ SG_ 299 DAS_smartShiftChecksum "Driver assistance computer: smart shift checksum";
CM_ SG_ 299 DAS_smartShiftCounter "Driver assistance computer: smart shift counter";
CM_ SG_ 299 DAS_smartShiftTorqueDirection "Reports Driver Assistance System (DAS) Smart Shift torque direction.";
CM_ SG_ 299 DAS_smartShiftTorqueReason "Reports Driver Assistance System (DAS) Smart Shift torque direction reason.";
CM_ SG_ 299 DAS_autoshiftTorqueDirectionDbg "Driver assistance computer: autoshift torque direction dbg";
CM_ SG_ 299 DAS_autoshiftUpcomingDirection "Reports the Driver Assistance System (DAS) upcoming torque direction.";
CM_ SG_ 299 DAS_autoshiftBrakeRequired "Reports whether brake press is required for Autoshift Drive/Reverse (D/R).";
CM_ SG_ 299 DAS_autoshiftSteerRequest "Reports the Driver Assistance System (DAS) steering angle direction requested for Autoshift Drive/Reverse (D/R).";
CM_ BO_ 921 "Driver assistance computer message: status";
CM_ SG_ 921 DAS_autopilotState "Reports the high level autopilot state.";
CM_ SG_ 921 DAS_blindSpotRearLeft "Reports rear left blind spot warning level.";
CM_ SG_ 921 DAS_blindSpotRearRight "Reports rear right blind spot warning level.";
CM_ SG_ 921 DAS_fusedSpeedLimit "Driver assistance computer: fused speed limit";
CM_ SG_ 921 DAS_suppressSpeedWarning "Driver assistance computer: suppress speed warning";
CM_ SG_ 921 DAS_summonObstacle "Driver assistance computer: summon obstacle";
CM_ SG_ 921 DAS_summonClearedGate "Driver assistance computer: summon cleared gate";
CM_ SG_ 921 DAS_visionOnlySpeedLimit "Driver assistance computer: vision only speed limit";
CM_ SG_ 921 DAS_heaterState "The state of the app which runs the front glass heater.";
CM_ SG_ 921 DAS_forwardCollisionWarning "Driver assistance computer: forward collision warning";
CM_ SG_ 921 DAS_autoparkReady "Indicates if all the conditions for Autopark are met.";
CM_ SG_ 921 DAS_autoParked "Driver assistance computer: auto parked";
CM_ SG_ 921 DAS_autoparkActive "Reports whether Autopark is currently active.";
CM_ SG_ 921 DAS_summonFwdLeashReached "Driver assistance computer: summon fwd leash reached";
CM_ SG_ 921 DAS_summonRvsLeashReached "Driver assistance computer: summon rvs leash reached";
CM_ SG_ 921 DAS_lssState "Tracks lane support system state and whether it is controlling steering angle requests for LKA / ELKA.";
CM_ SG_ 921 DAS_sideCollisionAvoid "Reports if the side collision avoidance function is active on the left or right.";
CM_ SG_ 921 DAS_sideCollisionWarning "Reports if the side collision warning function is active in the left or right.";
CM_ SG_ 921 DAS_sideCollisionInhibit "Driver assistance computer: side collision inhibit";
CM_ SG_ 921 DAS_laneDepartureWarning "Driver assistance computer: lane departure warning";
CM_ SG_ 921 DAS_fleetSpeedState "The state of the fleet speed algorithm.";
CM_ SG_ 921 DAS_autopilotHandsOnState "Reports the state of the hands on state machine.";
CM_ SG_ 921 DAS_autoLaneChangeState "Reports the legacy Automatic Lane Change (ALC) state used to drive the instrument cluster User Interface (UI).";
CM_ SG_ 921 DAS_summonAvailable "Driver assistance computer: summon available";
CM_ SG_ 921 DAS_statusCounter "Driver assistance computer: status counter";
CM_ SG_ 921 DAS_statusChecksum "Driver assistance computer: status checksum";
CM_ BO_ 905 "Driver assistance computer message: status2";
CM_ SG_ 905 DAS_accSpeedLimit "Reports the Adaptive Cruise Control (ACC) speed limit, which is derived from speed limits embedded in maps.";
CM_ SG_ 905 DAS_versionIdentifier "Driver assistance computer: version identifier";
CM_ SG_ 905 DAS_pmmObstacleSeverity "Detects the output of the Pedal Misapplication Mitigation (PMM) function, which limits torque or applies the brake.";
CM_ SG_ 905 DAS_pmmLoggingRequest "Driver assistance computer: pmm logging request";
CM_ SG_ 905 DAS_activationFailureStatus "Driver assistance computer: activation failure status";
CM_ SG_ 905 DAS_pmmUltrasonicsFaultReason "Reports if there is a reason Pedal Misapplication Mitigation (PMM) is disabled due to a condition with the ultrasonics.";
CM_ SG_ 905 DAS_pmmRadarFaultReason "Reports if there is a reason Pedal Misapplication Mitigation (PMM) is disabled due to a radar issue.";
CM_ SG_ 905 DAS_pmmSysFaultReason "Reports if there is a reason Pedal Misapplication Mitigation (PMM) is disabled due to a system malfunction.";
CM_ SG_ 905 DAS_pmmCameraFaultReason "Reports if there is a reason Pedal Misapplication Mitigation (PMM) is disabled due to camera issues.";
CM_ SG_ 905 DAS_ACC_report "Indicates what control target Traffic-Aware Cruise Control (TACC) is controlling for. Only relevant during TACC (not Autosteer).";
CM_ SG_ 905 DAS_relaxCruiseLimits "Indicates whether DI should relax accel limits";
CM_ SG_ 905 DAS_csaState "Reports the state of the curve speed adaption algorithm.";
CM_ SG_ 905 DAS_radarTelemetry "Driver assistance computer: radar telemetry";
CM_ SG_ 905 DAS_robState "Driver assistance computer: rob state";
CM_ SG_ 905 DAS_driverInteractionLevel "Driver assistance computer: driver interaction level";
CM_ SG_ 905 DAS_ppOffsetDesiredRamp "Driver assistance computer: pp offset desired ramp";
CM_ SG_ 905 DAS_longCollisionWarning "Driver assistance computer: long collision warning";
CM_ SG_ 905 DAS_status2Counter "Driver assistance computer: status2 counter";
CM_ SG_ 905 DAS_status2Checksum "Driver assistance computer: status2 checksum";
CM_ BO_ 1548 "Driver assistance computer message: telemetry radar";
CM_ SG_ 1548 DAS_TR_ObjIndex "Driver assistance computer: TR obj index";
CM_ SG_ 1548 DAS_TR_Counter "Driver assistance computer: TR counter";
CM_ SG_ 1548 DAS_TR_Obj00_Class "Driver assistance computer: TR obj00 class";
CM_ SG_ 1548 DAS_TR_Obj00_Dx "Driver assistance computer: TR obj00 dx";
CM_ SG_ 1548 DAS_TR_Obj00_Dy "Driver assistance computer: TR obj00 dy";
CM_ SG_ 1548 DAS_TR_Obj00_Vx "Driver assistance computer: TR obj00 vx";
CM_ SG_ 1548 DAS_TR_Obj00_RCS "Driver assistance computer: TR obj00 RCS";
CM_ SG_ 1548 DAS_TR_Obj00_Length "Driver assistance computer: TR obj00 length";
CM_ SG_ 1548 DAS_TR_Obj00_MovingState "Driver assistance computer: TR obj00 moving state";
CM_ SG_ 1548 DAS_TR_Obj00_Dz "Driver assistance computer: TR obj00 dz";
CM_ SG_ 1548 DAS_TR_Obj00_Exist "Driver assistance computer: TR obj00 exist";
CM_ BO_ 586 "Driver assistance computer message: visual debug";
CM_ SG_ 586 DAS_autosteerVehiclesUsage "Driver assistance computer: autosteer vehicles usage";
CM_ SG_ 586 DAS_autosteerHPPUsage "Driver assistance computer: autosteer HPP usage";
CM_ SG_ 586 DAS_autosteerNavigationUsage "Driver assistance computer: autosteer navigation usage";
CM_ SG_ 586 DAS_autosteerModelUsage "Driver assistance computer: autosteer model usage";
CM_ SG_ 586 DAS_autosteerBottsDotsUsage "Driver assistance computer: autosteer botts dots usage";
CM_ SG_ 586 DAS_offsetSide "Driver assistance computer: offset side";
CM_ SG_ 586 DAS_roadSurfaceType "Driver assistance computer: road surface type";
CM_ SG_ 586 DAS_autosteerHealthAnomalyLevel "Driver assistance computer: autosteer health anomaly level";
CM_ SG_ 586 DAS_autosteerHealthState "Driver assistance computer: autosteer health state";
CM_ SG_ 586 DAS_lastLinePreferenceReason "Driver assistance computer: last line preference reason";
CM_ SG_ 586 DAS_plannerState "Driver assistance computer: planner state";
CM_ SG_ 586 DAS_lastAutosteerAbortReason "Driver assistance computer: last autosteer abort reason";
CM_ SG_ 586 DAS_devAppInterfaceEnabled "Driver assistance computer: dev app interface enabled";
CM_ SG_ 586 DAS_navAvailable "Driver assistance computer: nav available";
CM_ SG_ 586 DAS_navDistance "Driver assistance computer: nav distance";
CM_ SG_ 586 DAS_accSmartSpeedActive "Driver assistance computer: acc smart speed active";
CM_ SG_ 586 DAS_accSmartSpeedState "Driver assistance computer: acc smart speed state";
CM_ SG_ 586 DAS_ulcInProgress "Reports active lane changes that were not commanded.";
CM_ SG_ 586 DAS_trafficAwareSetSpeedInUse "Indicates that autopilot is using cruise set speed based on flow of traffic";
CM_ SG_ 586 DAS_isaSystemState "ISA system state";
CM_ SG_ 586 DAS_behaviorType "Driver assistance computer: behavior type";
CM_ SG_ 586 DAS_ulcType "Reports the underlying reason for the uncommanded lane change, whether for speed or route.";
CM_ SG_ 586 DAS_rearVehDetectedThisCycle "Driver assistance computer: rear veh detected this cycle";
CM_ SG_ 586 DAS_rearLeftVehDetectedCurrent "Driver assistance computer: rear left veh detected current";
CM_ SG_ 586 DAS_rearRightVehDetectedTrip "Driver assistance computer: rear right veh detected trip";
CM_ SG_ 586 DAS_rearLeftVehDetectedTrip "Driver assistance computer: rear left veh detected trip";
CM_ BO_ 2039 "Driver assistance computer message: warning matrix0";
CM_ SG_ 2039 DAS_w002_ldwDisabled "Driver assistance computer: w002 ldw disabled";
CM_ SG_ 2039 DAS_w003_isaDisabled "Driver assistance computer: w003 isa disabled";
CM_ SG_ 2039 DAS_w004_accDisabled "Driver assistance computer: w004 acc disabled";
CM_ SG_ 2039 DAS_w005_fcwCancelled "Driver assistance computer: w005 fcw cancelled";
CM_ SG_ 2039 DAS_w006_aebCancelled "Driver assistance computer: w006 aeb cancelled";
CM_ SG_ 2039 DAS_w007_ahlbDisabled "Driver assistance computer: w007 ahlb disabled";
CM_ SG_ 2039 DAS_w008_parkDisabled "Driver assistance computer: w008 park disabled";
CM_ SG_ 2039 DAS_w009_aebFault "Driver assistance computer: w009 aeb fault";
CM_ SG_ 2039 DAS_w010_radcCalibIssue "Driver assistance computer: w010 radc calib issue";
CM_ SG_ 2039 DAS_w011_scaEvent "Driver assistance computer: w011 sca event";
CM_ SG_ 2039 DAS_w012_Cam_BootFailure "Driver assistance computer: w012 cam boot failure";
CM_ SG_ 2039 DAS_w013_Cam_Watchdog "Driver assistance computer: w013 cam watchdog";
CM_ SG_ 2039 DAS_w014_swAssert "Driver assistance computer: w014 sw assert";
CM_ SG_ 2039 DAS_w015_Camera_Failsafes "Driver assistance computer: w015 camera failsafes";
CM_ SG_ 2039 DAS_w016_aeb_e_event "Driver assistance computer: w016 aeb e event";
CM_ SG_ 2039 DAS_w017_Cam_Msg_MIA "Driver assistance computer: w017 cam msg MIA";
CM_ SG_ 2039 DAS_w018_ECU_Power_Issue "Driver assistance computer: w018 ECU power issue";
CM_ SG_ 2039 DAS_w019_ECU_Stack_Overflow "Driver assistance computer: w019 ECU stack overflow";
CM_ SG_ 2039 DAS_w020_ECU_checkstopError "Driver assistance computer: w020 ECU checkstop error";
CM_ SG_ 2039 DAS_w021_ECU_Temperature_Issue "Driver assistance computer: w021 ECU temperature issue";
CM_ SG_ 2039 DAS_w022_ECU_EEPROM_Failure "Driver assistance computer: w022 ECU EEPROM failure";
CM_ SG_ 2039 DAS_w023_ECU_Cam_Statemismatc "Driver assistance computer: w023 ECU cam statemismatc";
CM_ SG_ 2039 DAS_w024_ECU_Watchdog_Reset "Driver assistance computer: w024 ECU watchdog reset";
CM_ SG_ 2039 DAS_w025_LC_Steering_Override "Driver assistance computer: w025 LC steering override";
CM_ SG_ 2039 DAS_w026_ECU_timingIssue "Driver assistance computer: w026 ECU timing issue";
CM_ SG_ 2039 DAS_w027_ECU_Reset_Fault "Driver assistance computer: w027 ECU reset fault";
CM_ SG_ 2039 DAS_w028_spi_rx_error "Driver assistance computer: w028 spi rx error";
CM_ SG_ 2039 DAS_w029_spi_tx_error "Driver assistance computer: w029 spi tx error";
CM_ SG_ 2039 DAS_w030_Heater_Issue "Driver assistance computer: w030 heater issue";
CM_ SG_ 2039 DAS_w031_canRxError "Driver assistance computer: w031 can rx error";
CM_ SG_ 2039 DAS_w032_canTxError "Driver assistance computer: w032 can tx error";
CM_ SG_ 2039 DAS_w033_gtwMia "Driver assistance computer: w033 gtw mia";
CM_ SG_ 2039 DAS_w034_sccmMia "Driver assistance computer: w034 sccm mia";
CM_ SG_ 2039 DAS_w035_espMia "Driver assistance computer: w035 esp mia";
CM_ SG_ 2039 DAS_w036_bdyMia "Driver assistance computer: w036 bdy mia";
CM_ SG_ 2039 DAS_w037_camTacIssue "Driver assistance computer: w037 cam tac issue";
CM_ SG_ 2039 DAS_w038_camFailure "Driver assistance computer: w038 cam failure";
CM_ SG_ 2039 DAS_w039_sdm_rcm_Mia "Driver assistance computer: w039 sdm rcm mia";
CM_ SG_ 2039 DAS_w040_autopilotAngleSaturated "Driver assistance computer: w040 autopilot angle saturated";
CM_ SG_ 2039 DAS_w041_autopilotRateSaturated "Driver assistance computer: w041 autopilot rate saturated";
CM_ SG_ 2039 DAS_w042_autopilotAborting "Driver assistance computer: w042 autopilot aborting";
CM_ SG_ 2039 DAS_w043_camLongRunTime "Driver assistance computer: w043 cam long run time";
CM_ SG_ 2039 DAS_w044_appMobileyeFailure "Driver assistance computer: w044 app mobileye failure";
CM_ SG_ 2039 DAS_w045_radMia "Driver assistance computer: w045 rad mia";
CM_ SG_ 2039 DAS_w046_eepromRecordAbsent "Driver assistance computer: w046 eeprom record absent";
CM_ SG_ 2039 DAS_w047_edrEvent "Driver assistance computer: w047 edr event";
CM_ SG_ 2039 DAS_w048_DAS_Features_Disabled "Driver assistance computer: w048 DAS features disabled";
CM_ SG_ 2039 DAS_w049_eyeqVersionMismatch "Driver assistance computer: w049 eyeq version mismatch";
CM_ SG_ 2039 DAS_w050_aeb_event "Driver assistance computer: w050 aeb event";
CM_ SG_ 2039 DAS_w051_radcEcuIssue "Driver assistance computer: w051 radc ecu issue";
CM_ SG_ 2039 DAS_w052_radcSensorIssue "Driver assistance computer: w052 radc sensor issue";
CM_ SG_ 2039 DAS_w053_radcCommIssue "Driver assistance computer: w053 radc comm issue";
CM_ SG_ 2039 DAS_w054_camAutofix "Driver assistance computer: w054 cam autofix";
CM_ SG_ 2039 DAS_w055_radcVersionMismatch "Driver assistance computer: w055 radc version mismatch";
CM_ SG_ 2039 DAS_w056_diMia "Driver assistance computer: w056 di mia";
CM_ SG_ 2039 DAS_w057_mcuMia "Driver assistance computer: w057 mcu mia";
CM_ SG_ 2039 DAS_w058_epbMia "Driver assistance computer: w058 epb mia";
CM_ SG_ 2039 DAS_w059_parkMia "Driver assistance computer: w059 park mia";
CM_ SG_ 2039 DAS_w060_fcw_event "Driver assistance computer: w060 fcw event";
CM_ SG_ 2039 DAS_w061_airSuspensionMia "Driver assistance computer: w061 air suspension mia";
CM_ SG_ 2039 DAS_w062_radcAlignment "Driver assistance computer: w062 radc alignment";
CM_ SG_ 2039 DAS_w063_parkVersionMismatch "Driver assistance computer: w063 park version mismatch";
CM_ SG_ 2039 DAS_w064_epasMia "Driver assistance computer: w064 epas mia";
CM_ BO_ 874 "Driver assistance computer message: warning matrix1";
CM_ SG_ 874 DAS_w065_deserializerOvercurrent "Driver assistance computer: w065 deserializer overcurrent";
CM_ SG_ 874 DAS_w066_deserializerLockLost "Driver assistance computer: w066 deserializer lock lost";
CM_ SG_ 874 DAS_w067_steeringAlignment "Driver assistance computer: w067 steering alignment";
CM_ SG_ 874 DAS_w068_vlInconsistency "Driver assistance computer: w068 vl inconsistency";
CM_ SG_ 874 DAS_w069_apcSpaceMasked "Driver assistance computer: w069 apc space masked";
CM_ SG_ 874 DAS_w070_apcIncompleteCal "Driver assistance computer: w070 apc incomplete cal";
CM_ SG_ 874 DAS_w071_selfparkStarted "Driver assistance computer: w071 selfpark started";
CM_ SG_ 874 DAS_w072_selfparkComplete "Driver assistance computer: w072 selfpark complete";
CM_ SG_ 874 DAS_w073_issueEscalatedLDW "Driver assistance computer: w073 issue escalated LDW";
CM_ SG_ 874 DAS_w074_inPathStationaryObst "Driver assistance computer: w074 in path stationary obst";
CM_ SG_ 874 DAS_w075_scMia "Driver assistance computer: w075 sc mia";
CM_ SG_ 874 DAS_w076_mobilEyeSetC "Driver assistance computer: w076 mobil eye set c";
CM_ SG_ 874 DAS_w077_pmmActive "Driver assistance computer: w077 pmm active";
CM_ SG_ 874 DAS_w078_pmmActive2 "Driver assistance computer: w078 pmm active2";
CM_ SG_ 874 DAS_w079_edrAvailable "Driver assistance computer: w079 edr available";
CM_ SG_ 874 DAS_w080_accFailedActivation "Driver assistance computer: w080 acc failed activation";
CM_ SG_ 874 DAS_w081_pmmActiveBraking "Driver assistance computer: w081 pmm active braking";
CM_ SG_ 874 DAS_w082_inPathFSviolation "Driver assistance computer: w082 in path f sviolation";
CM_ SG_ 874 DAS_w083_inPathRADObject "Driver assistance computer: w083 in path RAD object";
CM_ SG_ 874 DAS_w084_pmmIPSO "Driver assistance computer: w084 pmm IPSO";
CM_ SG_ 874 DAS_w085_pmmSteering "Driver assistance computer: w085 pmm steering";
CM_ SG_ 874 DAS_w086_robCollision "Driver assistance computer: w086 rob collision";
CM_ SG_ 874 DAS_w087_DEPRECATED "Driver assistance computer: w087 DEPRECATED";
CM_ SG_ 874 DAS_w088_DEPRECATED "Driver assistance computer: w088 DEPRECATED";
CM_ SG_ 874 DAS_w089_DEPRECATED "Driver assistance computer: w089 DEPRECATED";
CM_ SG_ 874 DAS_w090_DEPRECATED "Driver assistance computer: w090 DEPRECATED";
CM_ SG_ 874 DAS_w091_DEPRECATED "Driver assistance computer: w091 DEPRECATED";
CM_ SG_ 874 DAS_w092_DEPRECATED "Driver assistance computer: w092 DEPRECATED";
CM_ SG_ 874 DAS_w093_DEPRECATED "Driver assistance computer: w093 DEPRECATED";
CM_ SG_ 874 DAS_w094_DEPRECATED "Driver assistance computer: w094 DEPRECATED";
CM_ SG_ 874 DAS_w095_DEPRECATED "Driver assistance computer: w095 DEPRECATED";
CM_ SG_ 874 DAS_w096_DEPRECATED "Driver assistance computer: w096 DEPRECATED";
CM_ SG_ 874 DAS_w097_DEPRECATED "Driver assistance computer: w097 DEPRECATED";
CM_ SG_ 874 DAS_w098_DEPRECATED "Driver assistance computer: w098 DEPRECATED";
CM_ SG_ 874 DAS_w099_DEPRECATED "Driver assistance computer: w099 DEPRECATED";
CM_ SG_ 874 DAS_w100_DEPRECATED "Driver assistance computer: w100 DEPRECATED";
CM_ SG_ 874 DAS_w101_DEPRECATED "Driver assistance computer: w101 DEPRECATED";
CM_ SG_ 874 DAS_w102_DEPRECATED "Driver assistance computer: w102 DEPRECATED";
CM_ SG_ 874 DAS_w103_robExperimentalAEB "Driver assistance computer: w103 rob experimental AEB";
CM_ SG_ 874 DAS_w104_DEPRECATED "Driver assistance computer: w104 DEPRECATED";
CM_ SG_ 874 DAS_w105_DEPRECATED "Driver assistance computer: w105 DEPRECATED";
CM_ SG_ 874 DAS_w106_torsionBarCalibrated "Driver assistance computer: w106 torsion bar calibrated";
CM_ BO_ 841 "Driver assistance computer message: warning matrix2";
CM_ SG_ 841 DAS_w129_mainCamExtNotCal "Driver assistance computer: w129 main cam ext not cal";
CM_ SG_ 841 DAS_w130_narrowCamExtNotCal "Driver assistance computer: w130 narrow cam ext not cal";
CM_ SG_ 841 DAS_w131_mainCamCalSaved "Driver assistance computer: w131 main cam cal saved";
CM_ SG_ 841 DAS_w132_narrowCamCalSaved "Driver assistance computer: w132 narrow cam cal saved";
CM_ SG_ 841 DAS_w133_mainCamInitFault "Driver assistance computer: w133 main cam init fault";
CM_ SG_ 841 DAS_w134_narrowCamInitFault "Driver assistance computer: w134 narrow cam init fault";
CM_ SG_ 841 DAS_w135_fisheyeCamInitFault "Driver assistance computer: w135 fisheye cam init fault";
CM_ SG_ 841 DAS_w136_lPillarCamInitFault "Driver assistance computer: w136 l pillar cam init fault";
CM_ SG_ 841 DAS_w137_rPillarCamInitFault "Driver assistance computer: w137 r pillar cam init fault";
CM_ SG_ 841 DAS_w138_lRepeatCamInitFault "Driver assistance computer: w138 l repeat cam init fault";
CM_ SG_ 841 DAS_w139_rRepeatCamInitFault "Driver assistance computer: w139 r repeat cam init fault";
CM_ SG_ 841 DAS_w140_backupCamInitFault "Driver assistance computer: w140 backup cam init fault";
CM_ SG_ 841 DAS_w141_ECU_Thermal_Issue "Driver assistance computer: w141 ECU thermal issue";
CM_ SG_ 841 DAS_w142_fwdCamPitchProblem "Driver assistance computer: w142 fwd cam pitch problem";
CM_ SG_ 841 DAS_w143_IDF_event "Driver assistance computer: w143 IDF event";
CM_ SG_ 841 DAS_w144_selfieCamInitFault "Driver assistance computer: w144 selfie cam init fault";
CM_ SG_ 841 DAS_w171_fisheyeCamExtNotCal "Driver assistance computer: w171 fisheye cam ext not cal";
CM_ SG_ 841 DAS_w172_lPillarCamExtNotCal "Driver assistance computer: w172 l pillar cam ext not cal";
CM_ SG_ 841 DAS_w173_rPillarCamExtNotCal "Driver assistance computer: w173 r pillar cam ext not cal";
CM_ SG_ 841 DAS_w174_lRepeatCamExtNotCal "Driver assistance computer: w174 l repeat cam ext not cal";
CM_ SG_ 841 DAS_w175_rRepeatCamExtNotCal "Driver assistance computer: w175 r repeat cam ext not cal";
CM_ SG_ 841 DAS_w177_fisheyeCamCalSaved "Driver assistance computer: w177 fisheye cam cal saved";
CM_ SG_ 841 DAS_w178_lPillarCamCalSaved "Driver assistance computer: w178 l pillar cam cal saved";
CM_ SG_ 841 DAS_w179_rPillarCamCalSaved "Driver assistance computer: w179 r pillar cam cal saved";
CM_ SG_ 841 DAS_w180_lRepeatCamCalSaved "Driver assistance computer: w180 l repeat cam cal saved";
CM_ SG_ 841 DAS_w181_rRepeatCamCalSaved "Driver assistance computer: w181 r repeat cam cal saved";
CM_ BO_ 1082 "Driver assistance computer message: warning matrix3";
CM_ SG_ 1082 DAS_w193_camWindshieldUnclean "Driver assistance computer: w193 cam windshield unclean";
CM_ SG_ 1082 DAS_w194_accDriverResumeRqrd "Driver assistance computer: w194 acc driver resume rqrd";
CM_ SG_ 1082 DAS_w195_scwUnavailable "Driver assistance computer: w195 scw unavailable";
CM_ SG_ 1082 DAS_w196_stopSignWarning "Driver assistance computer: w196 stop sign warning";
CM_ SG_ 1082 DAS_w197_redLightWarning "Driver assistance computer: w197 red light warning";
CM_ SG_ 1082 DAS_w198_tsrUnavailable "Driver assistance computer: w198 tsr unavailable";
CM_ SG_ 1082 DAS_w199_apcAbort "Driver assistance computer: w199 apc abort";
CM_ SG_ 1082 DAS_w200_lcSlowdown "Driver assistance computer: w200 lc slowdown";
CM_ SG_ 1082 DAS_w201_lcAborting "Driver assistance computer: w201 lc aborting";
CM_ SG_ 1082 DAS_w202_scwNoisyEnvironment "Driver assistance computer: w202 scw noisy environment";
CM_ SG_ 1082 DAS_w203_apcActivation "Driver assistance computer: w203 apc activation";
CM_ SG_ 1082 DAS_w204_apcFinalFront "Driver assistance computer: w204 apc final front";
CM_ SG_ 1082 DAS_w205_apcFinalRear "Driver assistance computer: w205 apc final rear";
CM_ SG_ 1082 DAS_w206_autosteerNotEnabled "Driver assistance computer: w206 autosteer not enabled";
CM_ SG_ 1082 DAS_w207_autosteerUnavailable "Driver assistance computer: w207 autosteer unavailable";
CM_ SG_ 1082 DAS_w208_rackDetected "Driver assistance computer: w208 rack detected";
CM_ SG_ 1082 DAS_w209_autoSummonRequest "Driver assistance computer: w209 auto summon request";
CM_ SG_ 1082 DAS_w210_camObstrcted "Driver assistance computer: w210 cam obstrcted";
CM_ SG_ 1082 DAS_w211_accNoSeatBelt "Driver assistance computer: w211 acc no seat belt";
CM_ SG_ 1082 DAS_w212_lcUnavailableStrikeOut "Driver assistance computer: w212 lc unavailable strike out";
CM_ SG_ 1082 DAS_w213_autosteerStruckOut "Driver assistance computer: w213 autosteer struck out";
CM_ SG_ 1082 DAS_w214_driverNotIntracting "Driver assistance computer: w214 driver not intracting";
CM_ SG_ 1082 DAS_w215_contDriverNotIntracting "Driver assistance computer: w215 cont driver not intracting";
CM_ SG_ 1082 DAS_w216_driverOverriding "Driver assistance computer: w216 driver overriding";
CM_ SG_ 1082 DAS_w217_lcUnavailableSpeeding "Driver assistance computer: w217 lc unavailable speeding";
CM_ SG_ 1082 DAS_w218_lcSpeedExceededLimit "Driver assistance computer: w218 lc speed exceeded limit";
CM_ SG_ 1082 DAS_w219_lcTempUnavailableSpeed "Driver assistance computer: w219 lc temp unavailable speed";
CM_ SG_ 1082 DAS_w220_lcTempUnavailableRoad "Driver assistance computer: w220 lc temp unavailable road";
CM_ SG_ 1082 DAS_w221_accRadarBlind "Driver assistance computer: w221 acc radar blind";
CM_ SG_ 1082 DAS_w222_accCameraBlind "Driver assistance computer: w222 acc camera blind";
CM_ SG_ 1082 DAS_w223_accObjectInPath "Driver assistance computer: w223 acc object in path";
CM_ SG_ 1082 DAS_w224_accCameraCalibration "Driver assistance computer: w224 acc camera calibration";
CM_ SG_ 1082 DAS_w225_lcDegradedVisSpeedLmt "Driver assistance computer: w225 lc degraded vis speed lmt";
CM_ SG_ 1082 DAS_w226_lcCamCalNeededSpeedLmt "Driver assistance computer: w226 lc cam cal needed speed lmt";
CM_ SG_ 1082 DAS_w227_virtualWallBlocked "Driver assistance computer: w227 virtual wall blocked";
CM_ SG_ 1082 DAS_w228_DEPRECATED "Driver assistance computer: w228 DEPRECATED";
CM_ SG_ 1082 DAS_w229_alcUltrasoundDamaged "Driver assistance computer: w229 alc ultrasound damaged";
CM_ SG_ 1082 DAS_w230_alcUltrasoundBlocked "Driver assistance computer: w230 alc ultrasound blocked";
CM_ SG_ 1082 DAS_w231_idfEvent "Driver assistance computer: w231 idf event";
CM_ SG_ 1082 DAS_w232_laneChangeRequested "Driver assistance computer: w232 lane change requested";
CM_ BO_ 1318 "Front drive inverter message: alert log";
CM_ SG_ 1318 DIF_alertID "Front drive inverter: alert ID";
CM_ SG_ 1318 DIF_alertState "Front drive inverter: alert state";
CM_ SG_ 1318 DIF_a001_thermalWarning_H "Front drive inverter: a001 thermal warning h";
CM_ SG_ 1318 DIF_a001_thermalShutdown_H "Front drive inverter: a001 thermal shutdown h";
CM_ SG_ 1318 DIF_a001_undervoltVL_H "Front drive inverter: a001 undervolt VL h";
CM_ SG_ 1318 DIF_a001_undervoltVH_H "Front drive inverter: a001 undervolt VH h";
CM_ SG_ 1318 DIF_a001_sense_H "Front drive inverter: a001 sense h";
CM_ SG_ 1318 DIF_a001_desat_H "Front drive inverter: a001 desat h";
CM_ SG_ 1318 DIF_a001_overvoltVL_H "Front drive inverter: a001 overvolt VL h";
CM_ SG_ 1318 DIF_a001_overvoltVH_H "Front drive inverter: a001 overvolt VH h";
CM_ SG_ 1318 DIF_a001_undervoltVCC_H "Front drive inverter: a001 undervolt VCC h";
CM_ SG_ 1318 DIF_a001_asynchStop_H "Front drive inverter: a001 asynch stop h";
CM_ SG_ 1318 DIF_a001_remoteRegError_H "Front drive inverter: a001 remote reg error h";
CM_ SG_ 1318 DIF_a001_undervoltVDD_H "Front drive inverter: a001 undervolt VDD h";
CM_ SG_ 1318 DIF_a001_overvoltVDD_H "Front drive inverter: a001 overvolt VDD h";
CM_ SG_ 1318 DIF_a001_localRegError_H "Front drive inverter: a001 local reg error h";
CM_ SG_ 1318 DIF_a001_spiError_H "Front drive inverter: a001 spi error h";
CM_ SG_ 1318 DIF_a001_deadtimeError_H "Front drive inverter: a001 deadtime error h";
CM_ SG_ 1318 DIF_a001_thermalWarning_L "Front drive inverter: a001 thermal warning l";
CM_ SG_ 1318 DIF_a001_thermalShutdown_L "Front drive inverter: a001 thermal shutdown l";
CM_ SG_ 1318 DIF_a001_undervoltVL_L "Front drive inverter: a001 undervolt VL l";
CM_ SG_ 1318 DIF_a001_undervoltVH_L "Front drive inverter: a001 undervolt VH l";
CM_ SG_ 1318 DIF_a001_sense_L "Front drive inverter: a001 sense l";
CM_ SG_ 1318 DIF_a001_desat_L "Front drive inverter: a001 desat l";
CM_ SG_ 1318 DIF_a001_overvoltVL_L "Front drive inverter: a001 overvolt VL l";
CM_ SG_ 1318 DIF_a001_overvoltVH_L "Front drive inverter: a001 overvolt VH l";
CM_ SG_ 1318 DIF_a001_undervoltVCC_L "Front drive inverter: a001 undervolt VCC l";
CM_ SG_ 1318 DIF_a001_asynchStop_L "Front drive inverter: a001 asynch stop l";
CM_ SG_ 1318 DIF_a001_remoteRegError_L "Front drive inverter: a001 remote reg error l";
CM_ SG_ 1318 DIF_a001_undervoltVDD_L "Front drive inverter: a001 undervolt VDD l";
CM_ SG_ 1318 DIF_a001_overvoltVDD_L "Front drive inverter: a001 overvolt VDD l";
CM_ SG_ 1318 DIF_a001_localRegError_L "Front drive inverter: a001 local reg error l";
CM_ SG_ 1318 DIF_a001_spiError_L "Front drive inverter: a001 spi error l";
CM_ SG_ 1318 DIF_a001_deadtimeError_L "Front drive inverter: a001 deadtime error l";
CM_ SG_ 1318 DIF_a001_gateDriveErrCounter "Front drive inverter: a001 gate drive err counter";
CM_ SG_ 1318 DIF_a001_remoteCommError_H "Front drive inverter: a001 remote comm error h";
CM_ SG_ 1318 DIF_a001_localCommError_H "Front drive inverter: a001 local comm error h";
CM_ SG_ 1318 DIF_a001_remoteReset_H "Front drive inverter: a001 remote reset h";
CM_ SG_ 1318 DIF_a001_localReset_H "Front drive inverter: a001 local reset h";
CM_ SG_ 1318 DIF_a001_remoteCommError_L "Front drive inverter: a001 remote comm error l";
CM_ SG_ 1318 DIF_a001_localCommError_L "Front drive inverter: a001 local comm error l";
CM_ SG_ 1318 DIF_a001_remoteReset_L "Front drive inverter: a001 remote reset l";
CM_ SG_ 1318 DIF_a001_localReset_L "Front drive inverter: a001 local reset l";
CM_ SG_ 1318 DIF_a001_faultLine1Gpio_H "Front drive inverter: a001 fault line1 gpio h";
CM_ SG_ 1318 DIF_a001_faultLine1Gpio_L "Front drive inverter: a001 fault line1 gpio l";
CM_ SG_ 1318 DIF_a002_thermalWarning_H "Front drive inverter: a002 thermal warning h";
CM_ SG_ 1318 DIF_a002_thermalShutdown_H "Front drive inverter: a002 thermal shutdown h";
CM_ SG_ 1318 DIF_a002_undervoltVL_H "Front drive inverter: a002 undervolt VL h";
CM_ SG_ 1318 DIF_a002_undervoltVH_H "Front drive inverter: a002 undervolt VH h";
CM_ SG_ 1318 DIF_a002_sense_H "Front drive inverter: a002 sense h";
CM_ SG_ 1318 DIF_a002_desat_H "Front drive inverter: a002 desat h";
CM_ SG_ 1318 DIF_a002_overvoltVL_H "Front drive inverter: a002 overvolt VL h";
CM_ SG_ 1318 DIF_a002_overvoltVH_H "Front drive inverter: a002 overvolt VH h";
CM_ SG_ 1318 DIF_a002_undervoltVCC_H "Front drive inverter: a002 undervolt VCC h";
CM_ SG_ 1318 DIF_a002_asynchStop_H "Front drive inverter: a002 asynch stop h";
CM_ SG_ 1318 DIF_a002_remoteRegError_H "Front drive inverter: a002 remote reg error h";
CM_ SG_ 1318 DIF_a002_undervoltVDD_H "Front drive inverter: a002 undervolt VDD h";
CM_ SG_ 1318 DIF_a002_overvoltVDD_H "Front drive inverter: a002 overvolt VDD h";
CM_ SG_ 1318 DIF_a002_localRegError_H "Front drive inverter: a002 local reg error h";
CM_ SG_ 1318 DIF_a002_spiError_H "Front drive inverter: a002 spi error h";
CM_ SG_ 1318 DIF_a002_deadtimeError_H "Front drive inverter: a002 deadtime error h";
CM_ SG_ 1318 DIF_a002_thermalWarning_L "Front drive inverter: a002 thermal warning l";
CM_ SG_ 1318 DIF_a002_thermalShutdown_L "Front drive inverter: a002 thermal shutdown l";
CM_ SG_ 1318 DIF_a002_undervoltVL_L "Front drive inverter: a002 undervolt VL l";
CM_ SG_ 1318 DIF_a002_undervoltVH_L "Front drive inverter: a002 undervolt VH l";
CM_ SG_ 1318 DIF_a002_sense_L "Front drive inverter: a002 sense l";
CM_ SG_ 1318 DIF_a002_desat_L "Front drive inverter: a002 desat l";
CM_ SG_ 1318 DIF_a002_overvoltVL_L "Front drive inverter: a002 overvolt VL l";
CM_ SG_ 1318 DIF_a002_overvoltVH_L "Front drive inverter: a002 overvolt VH l";
CM_ SG_ 1318 DIF_a002_undervoltVCC_L "Front drive inverter: a002 undervolt VCC l";
CM_ SG_ 1318 DIF_a002_asynchStop_L "Front drive inverter: a002 asynch stop l";
CM_ SG_ 1318 DIF_a002_remoteRegError_L "Front drive inverter: a002 remote reg error l";
CM_ SG_ 1318 DIF_a002_undervoltVDD_L "Front drive inverter: a002 undervolt VDD l";
CM_ SG_ 1318 DIF_a002_overvoltVDD_L "Front drive inverter: a002 overvolt VDD l";
CM_ SG_ 1318 DIF_a002_localRegError_L "Front drive inverter: a002 local reg error l";
CM_ SG_ 1318 DIF_a002_spiError_L "Front drive inverter: a002 spi error l";
CM_ SG_ 1318 DIF_a002_deadtimeError_L "Front drive inverter: a002 deadtime error l";
CM_ SG_ 1318 DIF_a002_gateDriveErrCounter "Front drive inverter: a002 gate drive err counter";
CM_ SG_ 1318 DIF_a002_remoteCommError_H "Front drive inverter: a002 remote comm error h";
CM_ SG_ 1318 DIF_a002_localCommError_H "Front drive inverter: a002 local comm error h";
CM_ SG_ 1318 DIF_a002_remoteReset_H "Front drive inverter: a002 remote reset h";
CM_ SG_ 1318 DIF_a002_localReset_H "Front drive inverter: a002 local reset h";
CM_ SG_ 1318 DIF_a002_remoteCommError_L "Front drive inverter: a002 remote comm error l";
CM_ SG_ 1318 DIF_a002_localCommError_L "Front drive inverter: a002 local comm error l";
CM_ SG_ 1318 DIF_a002_remoteReset_L "Front drive inverter: a002 remote reset l";
CM_ SG_ 1318 DIF_a002_localReset_L "Front drive inverter: a002 local reset l";
CM_ SG_ 1318 DIF_a002_faultLine1Gpio_H "Front drive inverter: a002 fault line1 gpio h";
CM_ SG_ 1318 DIF_a002_faultLine1Gpio_L "Front drive inverter: a002 fault line1 gpio l";
CM_ SG_ 1318 DIF_a003_thermalWarning_H "Front drive inverter: a003 thermal warning h";
CM_ SG_ 1318 DIF_a003_thermalShutdown_H "Front drive inverter: a003 thermal shutdown h";
CM_ SG_ 1318 DIF_a003_undervoltVL_H "Front drive inverter: a003 undervolt VL h";
CM_ SG_ 1318 DIF_a003_undervoltVH_H "Front drive inverter: a003 undervolt VH h";
CM_ SG_ 1318 DIF_a003_sense_H "Front drive inverter: a003 sense h";
CM_ SG_ 1318 DIF_a003_desat_H "Front drive inverter: a003 desat h";
CM_ SG_ 1318 DIF_a003_overvoltVL_H "Front drive inverter: a003 overvolt VL h";
CM_ SG_ 1318 DIF_a003_overvoltVH_H "Front drive inverter: a003 overvolt VH h";
CM_ SG_ 1318 DIF_a003_undervoltVCC_H "Front drive inverter: a003 undervolt VCC h";
CM_ SG_ 1318 DIF_a003_asynchStop_H "Front drive inverter: a003 asynch stop h";
CM_ SG_ 1318 DIF_a003_remoteRegError_H "Front drive inverter: a003 remote reg error h";
CM_ SG_ 1318 DIF_a003_undervoltVDD_H "Front drive inverter: a003 undervolt VDD h";
CM_ SG_ 1318 DIF_a003_overvoltVDD_H "Front drive inverter: a003 overvolt VDD h";
CM_ SG_ 1318 DIF_a003_localRegError_H "Front drive inverter: a003 local reg error h";
CM_ SG_ 1318 DIF_a003_spiError_H "Front drive inverter: a003 spi error h";
CM_ SG_ 1318 DIF_a003_deadtimeError_H "Front drive inverter: a003 deadtime error h";
CM_ SG_ 1318 DIF_a003_thermalWarning_L "Front drive inverter: a003 thermal warning l";
CM_ SG_ 1318 DIF_a003_thermalShutdown_L "Front drive inverter: a003 thermal shutdown l";
CM_ SG_ 1318 DIF_a003_undervoltVL_L "Front drive inverter: a003 undervolt VL l";
CM_ SG_ 1318 DIF_a003_undervoltVH_L "Front drive inverter: a003 undervolt VH l";
CM_ SG_ 1318 DIF_a003_sense_L "Front drive inverter: a003 sense l";
CM_ SG_ 1318 DIF_a003_desat_L "Front drive inverter: a003 desat l";
CM_ SG_ 1318 DIF_a003_overvoltVL_L "Front drive inverter: a003 overvolt VL l";
CM_ SG_ 1318 DIF_a003_overvoltVH_L "Front drive inverter: a003 overvolt VH l";
CM_ SG_ 1318 DIF_a003_undervoltVCC_L "Front drive inverter: a003 undervolt VCC l";
CM_ SG_ 1318 DIF_a003_asynchStop_L "Front drive inverter: a003 asynch stop l";
CM_ SG_ 1318 DIF_a003_remoteRegError_L "Front drive inverter: a003 remote reg error l";
CM_ SG_ 1318 DIF_a003_undervoltVDD_L "Front drive inverter: a003 undervolt VDD l";
CM_ SG_ 1318 DIF_a003_overvoltVDD_L "Front drive inverter: a003 overvolt VDD l";
CM_ SG_ 1318 DIF_a003_localRegError_L "Front drive inverter: a003 local reg error l";
CM_ SG_ 1318 DIF_a003_spiError_L "Front drive inverter: a003 spi error l";
CM_ SG_ 1318 DIF_a003_deadtimeError_L "Front drive inverter: a003 deadtime error l";
CM_ SG_ 1318 DIF_a003_gateDriveErrCounter "Front drive inverter: a003 gate drive err counter";
CM_ SG_ 1318 DIF_a003_remoteCommError_H "Front drive inverter: a003 remote comm error h";
CM_ SG_ 1318 DIF_a003_localCommError_H "Front drive inverter: a003 local comm error h";
CM_ SG_ 1318 DIF_a003_remoteReset_H "Front drive inverter: a003 remote reset h";
CM_ SG_ 1318 DIF_a003_localReset_H "Front drive inverter: a003 local reset h";
CM_ SG_ 1318 DIF_a003_remoteCommError_L "Front drive inverter: a003 remote comm error l";
CM_ SG_ 1318 DIF_a003_localCommError_L "Front drive inverter: a003 local comm error l";
CM_ SG_ 1318 DIF_a003_remoteReset_L "Front drive inverter: a003 remote reset l";
CM_ SG_ 1318 DIF_a003_localReset_L "Front drive inverter: a003 local reset l";
CM_ SG_ 1318 DIF_a003_faultLine1Gpio_H "Front drive inverter: a003 fault line1 gpio h";
CM_ SG_ 1318 DIF_a003_faultLine1Gpio_L "Front drive inverter: a003 fault line1 gpio l";
CM_ SG_ 1318 DIF_a007_phaseAcurrent "Front drive inverter: a007 phase acurrent";
CM_ SG_ 1318 DIF_a007_phaseBcurrent "Front drive inverter: a007 phase bcurrent";
CM_ SG_ 1318 DIF_a007_offsetError "Front drive inverter: a007 offset error";
CM_ SG_ 1318 DIF_a007_idFdbStdDeviation "Front drive inverter: a007 id fdb std deviation";
CM_ SG_ 1318 DIF_a007_iqFdbStdDeviation "Front drive inverter: a007 iq fdb std deviation";
CM_ SG_ 1318 DIF_a007_motorShift "Front drive inverter: a007 motor shift";
CM_ SG_ 1318 DIF_a007_motorShort "Front drive inverter: a007 motor short";
CM_ SG_ 1318 DIF_a010_sccReset "Front drive inverter: a010 scc reset";
CM_ SG_ 1318 DIF_a010_hibernate "Front drive inverter: a010 hibernate";
CM_ SG_ 1318 DIF_a010_hwBist "Front drive inverter: a010 hw bist";
CM_ SG_ 1318 DIF_a010_nmiWatchdog "Front drive inverter: a010 nmi watchdog";
CM_ SG_ 1318 DIF_a010_watchdog "Front drive inverter: a010 watchdog";
CM_ SG_ 1318 DIF_a010_clockFailNmi "Front drive inverter: a010 clock fail nmi";
CM_ SG_ 1318 DIF_a010_ramUncErrorNmi "Front drive inverter: a010 ram unc error nmi";
CM_ SG_ 1318 DIF_a010_flashUncErrorNmi "Front drive inverter: a010 flash unc error nmi";
CM_ SG_ 1318 DIF_a010_cpu1signMismatchNmi "Front drive inverter: a010 cpu1sign mismatch nmi";
CM_ SG_ 1318 DIF_a010_cpu2signMismatchNmi "Front drive inverter: a010 cpu2sign mismatch nmi";
CM_ SG_ 1318 DIF_a010_pieVectErrorNmi "Front drive inverter: a010 pie vect error nmi";
CM_ SG_ 1318 DIF_a010_sysDbgNmi "Front drive inverter: a010 sys dbg nmi";
CM_ SG_ 1318 DIF_a010_rlNmi "Front drive inverter: a010 rl nmi";
CM_ SG_ 1318 DIF_a010_ovfNmi "Front drive inverter: a010 ovf nmi";
CM_ SG_ 1318 DIF_a010_wdtFlags "Front drive inverter: a010 wdt flags";
CM_ SG_ 1318 DIF_a011_reason "Front drive inverter: a011 reason";
CM_ SG_ 1318 DIF_a011_phaseAHigh "Front drive inverter: a011 phase a high";
CM_ SG_ 1318 DIF_a011_phaseALow "Front drive inverter: a011 phase a low";
CM_ SG_ 1318 DIF_a011_phaseBHigh "Front drive inverter: a011 phase b high";
CM_ SG_ 1318 DIF_a011_phaseBLow "Front drive inverter: a011 phase b low";
CM_ SG_ 1318 DIF_a011_phaseCHigh "Front drive inverter: a011 phase c high";
CM_ SG_ 1318 DIF_a011_phaseCLow "Front drive inverter: a011 phase c low";
CM_ SG_ 1318 DIF_a011_regAddress "Front drive inverter: a011 reg address";
CM_ SG_ 1318 DIF_a011_badGateDriveIC "Front drive inverter: a011 bad gate drive IC";
CM_ SG_ 1318 DIF_a011_badDataRead "Front drive inverter: a011 bad data read";
CM_ SG_ 1318 DIF_a011_badDataExpected "Front drive inverter: a011 bad data expected";
CM_ SG_ 1318 DIF_a011_codeBranch "Front drive inverter: a011 code branch";
CM_ SG_ 1318 DIF_a012_hvilStatus "Front drive inverter: a012 hvil status";
CM_ SG_ 1318 DIF_a012_hvilCmVoltage "Front drive inverter: a012 hvil cm voltage";
CM_ SG_ 1318 DIF_a012_hvilCurrent "Front drive inverter: a012 hvil current";
CM_ SG_ 1318 DIF_a012_hvilFaultGpio "Front drive inverter: a012 hvil fault gpio";
CM_ SG_ 1318 DIF_a012_hvilSupplyPinDI "Front drive inverter: a012 hvil supply pin DI";
CM_ SG_ 1318 DIF_a012_hvilSupplyPinPM "Front drive inverter: a012 hvil supply pin PM";
CM_ SG_ 1318 DIF_a012_activeDisOn3V3 "Front drive inverter: a012 active dis on3 V3";
CM_ SG_ 1318 DIF_a012_hvilHeaderFault "Front drive inverter: a012 hvil header fault";
CM_ SG_ 1318 DIF_a013_address "Front drive inverter: a013 address";
CM_ SG_ 1318 DIF_a013_errorType "Front drive inverter: a013 error type";
CM_ SG_ 1318 DIF_a014_motorSpeed "Front drive inverter: a014 motor speed";
CM_ SG_ 1318 DIF_a014_adState "Front drive inverter: a014 ad state";
CM_ SG_ 1318 DIF_a014_torqueCommandFwd "Front drive inverter: a014 torque command fwd";
CM_ SG_ 1318 DIF_a014_brakeMasterCylPress "Front drive inverter: a014 brake master cyl press";
CM_ SG_ 1318 DIF_a014_rmsTorqueError "Front drive inverter: a014 rms torque error";
CM_ SG_ 1318 DIF_a014_tcEnabled "Front drive inverter: a014 tc enabled";
CM_ SG_ 1318 DIF_a014_fbDeratedForRmsError "Front drive inverter: a014 fb derated for rms error";
CM_ SG_ 1318 DIF_a016_newSafeState "Front drive inverter: a016 new safe state";
CM_ SG_ 1318 DIF_a016_oldSafeState "Front drive inverter: a016 old safe state";
CM_ SG_ 1318 DIF_a016_gateDriveFaultLine "Front drive inverter: a016 gate drive fault line";
CM_ SG_ 1318 DIF_a016_ascMonitor "Front drive inverter: a016 asc monitor";
CM_ SG_ 1318 DIF_a016_uncontrolledRegenZone "Front drive inverter: a016 uncontrolled regen zone";
CM_ SG_ 1318 DIF_a016_pedalMonitorPreWatchdog "Front drive inverter: a016 pedal monitor pre watchdog";
CM_ SG_ 1318 DIF_a016_motorRPM "Front drive inverter: a016 motor RPM";
CM_ SG_ 1318 DIF_a016_torqueMotor "Front drive inverter: a016 torque motor";
CM_ SG_ 1318 DIF_a016_safetyICfaultLine "Front drive inverter: a016 safety i cfault line";
CM_ SG_ 1318 DIF_a016_triggerEvent "Front drive inverter: a016 trigger event";
CM_ SG_ 1318 DIF_a024_vBat "Front drive inverter: a024 v bat";
CM_ SG_ 1318 DIF_a024_failReason "Front drive inverter: a024 fail reason";
CM_ SG_ 1318 DIF_a024_state "Front drive inverter: a024 state";
CM_ SG_ 1318 DIF_a024_Ia "Front drive inverter: a024 ia";
CM_ SG_ 1318 DIF_a024_Ib "Front drive inverter: a024 ib";
CM_ SG_ 1318 DIF_a024_maxCurrMagSqrd "Front drive inverter: a024 max curr mag sqrd";
CM_ SG_ 1318 DIF_a024_rotorAngle "Front drive inverter: a024 rotor angle";
CM_ SG_ 1318 DIF_a025_Ia "Front drive inverter: a025 ia";
CM_ SG_ 1318 DIF_a025_torqueMotor "Front drive inverter: a025 torque motor";
CM_ SG_ 1318 DIF_a025_motorSpeed "Front drive inverter: a025 motor speed";
CM_ SG_ 1318 DIF_a026_Ib "Front drive inverter: a026 ib";
CM_ SG_ 1318 DIF_a026_torqueMotor "Front drive inverter: a026 torque motor";
CM_ SG_ 1318 DIF_a026_motorSpeed "Front drive inverter: a026 motor speed";
CM_ SG_ 1318 DIF_a027_Ic "Front drive inverter: a027 ic";
CM_ SG_ 1318 DIF_a027_torqueMotor "Front drive inverter: a027 torque motor";
CM_ SG_ 1318 DIF_a027_motorSpeed "Front drive inverter: a027 motor speed";
CM_ SG_ 1318 DIF_a028_phaseAirms "Front drive inverter: a028 phase airms";
CM_ SG_ 1318 DIF_a028_iArmsTorque "Front drive inverter: a028 i arms torque";
CM_ SG_ 1318 DIF_a028_iArmsSpeed "Front drive inverter: a028 i arms speed";
CM_ SG_ 1318 DIF_a029_phaseBirms "Front drive inverter: a029 phase birms";
CM_ SG_ 1318 DIF_a029_iBrmsTorque "Front drive inverter: a029 i brms torque";
CM_ SG_ 1318 DIF_a029_iBrmsSpeed "Front drive inverter: a029 i brms speed";
CM_ SG_ 1318 DIF_a030_phaseCirms "Front drive inverter: a030 phase cirms";
CM_ SG_ 1318 DIF_a030_iCrmsTorque "Front drive inverter: a030 i crms torque";
CM_ SG_ 1318 DIF_a030_iCrmsSpeed "Front drive inverter: a030 i crms speed";
CM_ SG_ 1318 DIF_a031_phaseAoffset "Front drive inverter: a031 phase aoffset";
CM_ SG_ 1318 DIF_a032_phaseBoffset "Front drive inverter: a032 phase boffset";
CM_ SG_ 1318 DIF_a033_phaseAcurrent "Front drive inverter: a033 phase acurrent";
CM_ SG_ 1318 DIF_a033_deltaIa "Front drive inverter: a033 delta ia";
CM_ SG_ 1318 DIF_a033_vRefIa "Front drive inverter: a033 v ref ia";
CM_ SG_ 1318 DIF_a034_phaseBcurrent "Front drive inverter: a034 phase bcurrent";
CM_ SG_ 1318 DIF_a034_deltaIb "Front drive inverter: a034 delta ib";
CM_ SG_ 1318 DIF_a034_vRefIb "Front drive inverter: a034 v ref ib";
CM_ SG_ 1318 DIF_a035_phaseAerror "Front drive inverter: a035 phase aerror";
CM_ SG_ 1318 DIF_a035_phaseBerror "Front drive inverter: a035 phase berror";
CM_ SG_ 1318 DIF_a035_phaseCerror "Front drive inverter: a035 phase cerror";
CM_ SG_ 1318 DIF_a035_standbyCurrent "Front drive inverter: a035 standby current";
CM_ SG_ 1318 DIF_a035_unbalancedCurrent "Front drive inverter: a035 unbalanced current";
CM_ SG_ 1318 DIF_a035_wontMoveCurrent "Front drive inverter: a035 wont move current";
CM_ SG_ 1318 DIF_a035_reportingPhase "Front drive inverter: a035 reporting phase";
CM_ SG_ 1318 DIF_a035_noDriveCurrent "Front drive inverter: a035 no drive current";
CM_ SG_ 1318 DIF_a035_phaseDifference "Front drive inverter: a035 phase difference";
CM_ SG_ 1318 DIF_a035_phaseCurrent "Front drive inverter: a035 phase current";
CM_ SG_ 1318 DIF_a035_frequency "Front drive inverter: a035 frequency";
CM_ SG_ 1318 DIF_a036_busVoltage "Front drive inverter: a036 bus voltage";
CM_ SG_ 1318 DIF_a036_busHighLimit "Front drive inverter: a036 bus high limit";
CM_ SG_ 1318 DIF_a037_busVoltage "Front drive inverter: a037 bus voltage";
CM_ SG_ 1318 DIF_a037_busLowLimit "Front drive inverter: a037 bus low limit";
CM_ SG_ 1318 DIF_a038_vBMS "Front drive inverter: a038 v BMS";
CM_ SG_ 1318 DIF_a038_vBat "Front drive inverter: a038 v bat";
CM_ SG_ 1318 DIF_a038_iBat "Front drive inverter: a038 i bat";
CM_ SG_ 1318 DIF_a038_reason "Front drive inverter: a038 reason";
CM_ SG_ 1318 DIF_a040_torque "Front drive inverter: a040 torque";
CM_ SG_ 1318 DIF_a040_capability "Front drive inverter: a040 capability";
CM_ SG_ 1318 DIF_a040_power "Front drive inverter: a040 power";
CM_ SG_ 1318 DIF_a040_status "Front drive inverter: a040 status";
CM_ SG_ 1318 DIF_a040_capability2 "Front drive inverter: a040 capability2";
CM_ SG_ 1318 DIF_a040_hvStatus "Front drive inverter: a040 hv status";
CM_ SG_ 1318 DIF_a040_temperature "Front drive inverter: a040 temperature";
CM_ SG_ 1318 DIF_a041_uartRxDataAvailable "Front drive inverter: a041 uart rx data available";
CM_ SG_ 1318 DIF_a041_SDC_status_MIA "Front drive inverter: a041 SDC status MIA";
CM_ SG_ 1318 DIF_a041_diUartRxVersion "Front drive inverter: a041 di uart rx version";
CM_ SG_ 1318 DIF_a041_sdcUartRxVersion "Front drive inverter: a041 sdc uart rx version";
CM_ SG_ 1318 DIF_a043_outletTemp "Front drive inverter: a043 outlet temp";
CM_ SG_ 1318 DIF_a044_outletTemp "Front drive inverter: a044 outlet temp";
CM_ SG_ 1318 DIF_a045_inletTemp "Front drive inverter: a045 inlet temp";
CM_ SG_ 1318 DIF_a045_outletTemp "Front drive inverter: a045 outlet temp";
CM_ SG_ 1318 DIF_a045_heatsinkTemp "Front drive inverter: a045 heatsink temp";
CM_ SG_ 1318 DIF_a045_outletTempSlope "Front drive inverter: a045 outlet temp slope";
CM_ SG_ 1318 DIF_a046_statorTemp1 "Front drive inverter: a046 stator temp1";
CM_ SG_ 1318 DIF_a046_statorTemp2 "Front drive inverter: a046 stator temp2";
CM_ SG_ 1318 DIF_a047_statorTemp1 "Front drive inverter: a047 stator temp1";
CM_ SG_ 1318 DIF_a047_statorTslope1 "Front drive inverter: a047 stator tslope1";
CM_ SG_ 1318 DIF_a050_statorTemp1 "Front drive inverter: a050 stator temp1";
CM_ SG_ 1318 DIF_a050_statorTemp2 "Front drive inverter: a050 stator temp2";
CM_ SG_ 1318 DIF_a052_torque "Front drive inverter: a052 torque";
CM_ SG_ 1318 DIF_a052_capability "Front drive inverter: a052 capability";
CM_ SG_ 1318 DIF_a052_power "Front drive inverter: a052 power";
CM_ SG_ 1318 DIF_a052_status "Front drive inverter: a052 status";
CM_ SG_ 1318 DIF_a052_capability2 "Front drive inverter: a052 capability2";
CM_ SG_ 1318 DIF_a052_hvStatus "Front drive inverter: a052 hv status";
CM_ SG_ 1318 DIF_a052_temperature "Front drive inverter: a052 temperature";
CM_ SG_ 1318 DIF_a054_outletTemp "Front drive inverter: a054 outlet temp";
CM_ SG_ 1318 DIF_a054_heatsinkTemp "Front drive inverter: a054 heatsink temp";
CM_ SG_ 1318 DIF_a055_parameterDI "Front drive inverter: a055 parameter DI";
CM_ SG_ 1318 DIF_a055_parameterPM "Front drive inverter: a055 parameter PM";
CM_ SG_ 1318 DIF_a055_torqueType "Front drive inverter: a055 torque type";
CM_ SG_ 1318 DIF_a055_motorRPM "Front drive inverter: a055 motor RPM";
CM_ SG_ 1318 DIF_a056_pcbTemp "Front drive inverter: a056 pcb temp";
CM_ SG_ 1318 DIF_a057_pcbTemp "Front drive inverter: a057 pcb temp";
CM_ SG_ 1318 DIF_a058_pcbTemp "Front drive inverter: a058 pcb temp";
CM_ SG_ 1318 DIF_a058_outletTemp "Front drive inverter: a058 outlet temp";
CM_ SG_ 1318 DIF_a058_heatsinkTemp "Front drive inverter: a058 heatsink temp";
CM_ SG_ 1318 DIF_a058_pcbTempSlope "Front drive inverter: a058 pcb temp slope";
CM_ SG_ 1318 DIF_a059_heatsinkTemp "Front drive inverter: a059 heatsink temp";
CM_ SG_ 1318 DIF_a060_heatsinkTemp "Front drive inverter: a060 heatsink temp";
CM_ SG_ 1318 DIF_a061_sensor "Front drive inverter: a061 sensor";
CM_ SG_ 1318 DIF_a061_reason "Front drive inverter: a061 reason";
CM_ SG_ 1318 DIF_a061_phTemp "Front drive inverter: a061 ph temp";
CM_ SG_ 1318 DIF_a061_otherTemp "Front drive inverter: a061 other temp";
CM_ SG_ 1318 DIF_a062_limpReason "Front drive inverter: a062 limp reason";
CM_ SG_ 1318 DIF_a063_BB_status "Front drive inverter: a063 BB status";
CM_ SG_ 1318 DIF_a064_interventionType "Front drive inverter: a064 intervention type";
CM_ SG_ 1318 DIF_a064_torqueCmdState "Front drive inverter: a064 torque cmd state";
CM_ SG_ 1318 DIF_a069_motorSpeed "Front drive inverter: a069 motor speed";
CM_ SG_ 1318 DIF_a069_rotorCoolingPower "Front drive inverter: a069 rotor cooling power";
CM_ SG_ 1318 DIF_a069_rotorMagnetTemp "Front drive inverter: a069 rotor magnet temp";
CM_ SG_ 1318 DIF_a069_fittedTorqueLimit "Front drive inverter: a069 fitted torque limit";
CM_ SG_ 1318 DIF_a072_reason "Front drive inverter: a072 reason";
CM_ SG_ 1318 DIF_a073_motorSpeedrpm "Front drive inverter: a073 motor speedrpm";
CM_ SG_ 1318 DIF_a075_motorSpeed "Front drive inverter: a075 motor speed";
CM_ SG_ 1318 DIF_a075_absSpeed "Front drive inverter: a075 abs speed";
CM_ SG_ 1318 DIF_a076_lvSupplyV "Front drive inverter: a076 lv supply v";
CM_ SG_ 1318 DIF_a077_lvSupplyV "Front drive inverter: a077 lv supply v";
CM_ SG_ 1318 DIF_a078_adcRefChan "Front drive inverter: a078 adc ref chan";
CM_ SG_ 1318 DIF_a078_adcRefLowAvg "Front drive inverter: a078 adc ref low avg";
CM_ SG_ 1318 DIF_a079_adcRefChan "Front drive inverter: a079 adc ref chan";
CM_ SG_ 1318 DIF_a079_adcRefHighAvg "Front drive inverter: a079 adc ref high avg";
CM_ SG_ 1318 DIF_a087_gtwCarConfig "Front drive inverter: a087 gtw car config";
CM_ SG_ 1318 DIF_a087_gtwTime "Front drive inverter: a087 gtw time";
CM_ SG_ 1318 DIF_a087_gtwUpdateStatus "Front drive inverter: a087 gtw update status";
CM_ SG_ 1318 DIF_a087_gearControl "Front drive inverter: a087 gear control";
CM_ SG_ 1318 DIF_a087_carState "Front drive inverter: a087 car state";
CM_ SG_ 1318 DIF_a090_reason "Front drive inverter: a090 reason";
CM_ SG_ 1318 DIF_a090_systemState "Front drive inverter: a090 system state";
CM_ SG_ 1318 DIF_a090_state "Front drive inverter: a090 state";
CM_ SG_ 1318 DIF_a090_locState "Front drive inverter: a090 loc state";
CM_ SG_ 1318 DIF_a090_state2 "Front drive inverter: a090 state2";
CM_ SG_ 1318 DIF_a090_state4 "Front drive inverter: a090 state4";
CM_ SG_ 1318 DIF_a091_ESP_brakeTorque "Front drive inverter: a091 ESP brake torque";
CM_ SG_ 1318 DIF_a091_ESP_wheelSpeeds "Front drive inverter: a091 ESP wheel speeds";
CM_ SG_ 1318 DIF_a091_ESP_wheelRotation "Front drive inverter: a091 ESP wheel rotation";
CM_ SG_ 1318 DIF_a091_ESP_motorLimits "Front drive inverter: a091 ESP motor limits";
CM_ SG_ 1318 DIF_a091_ESP_offsets "Front drive inverter: a091 ESP offsets";
CM_ SG_ 1318 DIF_a091_ESP_status "Front drive inverter: a091 ESP status";
CM_ SG_ 1318 DIF_a091_ESP_party3 "Front drive inverter: a091 ESP party3";
CM_ SG_ 1318 DIF_a091_ESP_redundantBrakingSta "Front drive inverter: a091 ESP redundant braking status";
CM_ SG_ 1318 DIF_a092_bmsStatus "Front drive inverter: a092 bms status";
CM_ SG_ 1318 DIF_a092_bmsDriveLimits "Front drive inverter: a092 bms drive limits";
CM_ SG_ 1318 DIF_a092_bmsHvBusStatus "Front drive inverter: a092 bms hv bus status";
CM_ SG_ 1318 DIF_a092_bmsPowerAvailable "Front drive inverter: a092 bms power available";
CM_ SG_ 1318 DIF_a092_bmsBmbMinMax "Front drive inverter: a092 bms bmb min max";
CM_ SG_ 1318 DIF_a092_bmsSocStatus "Front drive inverter: a092 bms soc status";
CM_ SG_ 1318 DIF_a092_bmsThermalStatus "Front drive inverter: a092 bms thermal status";
CM_ SG_ 1318 DIF_a092_bmsCtrStatus "Front drive inverter: a092 bms ctr status";
CM_ SG_ 1318 DIF_a092_bmsVoltageRegGain "Front drive inverter: a092 bms voltage reg gain";
CM_ SG_ 1318 DIF_a092_bmsPackConfig "Front drive inverter: a092 bms pack config";
CM_ SG_ 1318 DIF_a092_bmsSystemStatus "Front drive inverter: a092 bms system status";
CM_ SG_ 1318 DIF_a096_const_fast "Front drive inverter: a096 const fast";
CM_ SG_ 1318 DIF_a096_text_fast "Front drive inverter: a096 text fast";
CM_ SG_ 1318 DIF_a096_text_flash "Front drive inverter: a096 text flash";
CM_ SG_ 1318 DIF_a096_mem_data "Front drive inverter: a096 mem data";
CM_ SG_ 1318 DIF_a096_mem_regs "Front drive inverter: a096 mem regs";
CM_ SG_ 1318 DIF_a096_boot_flash "Front drive inverter: a096 boot flash";
CM_ SG_ 1318 DIF_a096_word1 "Front drive inverter: a096 word1";
CM_ SG_ 1318 DIF_a096_word2 "Front drive inverter: a096 word2";
CM_ SG_ 1318 DIF_a097_errorType "Front drive inverter: a097 error type";
CM_ SG_ 1318 DIF_a097_lineNumber "Front drive inverter: a097 line number";
CM_ SG_ 1318 DIF_a097_argument "Front drive inverter: a097 argument";
CM_ SG_ 1318 DIF_a098_pwmCount "Front drive inverter: a098 pwm count";
CM_ SG_ 1318 DIF_a098_fluxState "Front drive inverter: a098 flux state";
CM_ SG_ 1318 DIF_a103_fluidTorDeltaT "Front drive inverter: a103 fluid tor delta t";
CM_ SG_ 1318 DIF_a103_noFlowDetected "Front drive inverter: a103 no flow detected";
CM_ SG_ 1318 DIF_a103_lowFlowDetected "Front drive inverter: a103 low flow detected";
CM_ SG_ 1318 DIF_a103_fluidImplausible "Front drive inverter: a103 fluid implausible";
CM_ SG_ 1318 DIF_a103_inverterTemp "Front drive inverter: a103 inverter temp";
CM_ SG_ 1318 DIF_a103_rmsCurrent "Front drive inverter: a103 rms current";
CM_ SG_ 1318 DIF_a103_ambientTemp "Front drive inverter: a103 ambient temp";
CM_ SG_ 1318 DIF_a103_sensorTempEst "Front drive inverter: a103 sensor temp est";
CM_ SG_ 1318 DIF_a107_fpgaVersion "Front drive inverter: a107 fpga version";
CM_ SG_ 1318 DIF_a107_fpgaBootVersion "Front drive inverter: a107 fpga boot version";
CM_ SG_ 1318 DIF_a107_fpgaMasterActive "Front drive inverter: a107 fpga master active";
CM_ SG_ 1318 DIF_a107_fpgaFaultActive "Front drive inverter: a107 fpga fault active";
CM_ SG_ 1318 DIF_a107_fpgaWarningActive "Front drive inverter: a107 fpga warning active";
CM_ SG_ 1318 DIF_a108_fromState "Front drive inverter: a108 from state";
CM_ SG_ 1318 DIF_a108_toState "Front drive inverter: a108 to state";
CM_ SG_ 1318 DIF_a108_blockingAlert "Front drive inverter: a108 blocking alert";
CM_ SG_ 1318 DIF_a110_EPBL_status "Front drive inverter: a110 EPBL status";
CM_ SG_ 1318 DIF_a110_EPBR_status "Front drive inverter: a110 EPBR status";
CM_ SG_ 1318 DIF_a110_EPBL_autonomyHealth "Front drive inverter: a110 EPBL autonomy health";
CM_ SG_ 1318 DIF_a110_EPBR_autonomyHealth "Front drive inverter: a110 EPBR autonomy health";
CM_ SG_ 1318 DIF_a111_phAcalib "Front drive inverter: a111 ph acalib";
CM_ SG_ 1318 DIF_a111_phBcalib "Front drive inverter: a111 ph bcalib";
CM_ SG_ 1318 DIF_a112_pwmSwitching "Front drive inverter: a112 pwm switching";
CM_ SG_ 1318 DIF_a112_gdicResetLine "Front drive inverter: a112 gdic reset line";
CM_ SG_ 1318 DIF_a112_allOffSafeState "Front drive inverter: a112 all off safe state";
CM_ SG_ 1318 DIF_a112_ls3psSafeState "Front drive inverter: a112 ls3ps safe state";
CM_ SG_ 1318 DIF_a112_hs3psSafeState "Front drive inverter: a112 hs3ps safe state";
CM_ SG_ 1318 DIF_a112_modulationIndex "Front drive inverter: a112 modulation index";
CM_ SG_ 1318 DIF_a113_heatsink1Temp "Front drive inverter: a113 heatsink1 temp";
CM_ SG_ 1318 DIF_a113_heatsink2Temp "Front drive inverter: a113 heatsink2 temp";
CM_ SG_ 1318 DIF_a113_heatsink3Temp "Front drive inverter: a113 heatsink3 temp";
CM_ SG_ 1318 DIF_a117_torque "Front drive inverter: a117 torque";
CM_ SG_ 1318 DIF_a117_slaveCommand "Front drive inverter: a117 slave command";
CM_ SG_ 1318 DIF_a117_power "Front drive inverter: a117 power";
CM_ SG_ 1318 DIF_a117_slaveCommand2 "Front drive inverter: a117 slave command2";
CM_ SG_ 1318 DIF_a117_speed "Front drive inverter: a117 speed";
CM_ SG_ 1318 DIF_a117_chassisControl "Front drive inverter: a117 chassis control";
CM_ SG_ 1318 DIF_a117_systemStatus "Front drive inverter: a117 system status";
CM_ SG_ 1318 DIF_a117_temperature "Front drive inverter: a117 temperature";
CM_ SG_ 1318 DIF_a117_vehicle "Front drive inverter: a117 vehicle";
CM_ SG_ 1318 DIF_a117_AddTcLimit "Front drive inverter: a117 add tc limit";
CM_ SG_ 1318 DIF_a117_dixCommand "Front drive inverter: a117 dix command";
CM_ SG_ 1318 DIF_a117_odometerStatus "Front drive inverter: a117 odometer status";
CM_ SG_ 1318 DIF_a119_hvpFaults "Front drive inverter: a119 hvp faults";
CM_ SG_ 1318 DIF_a120_dcLinkInfo "Front drive inverter: a120 dc link info";
CM_ SG_ 1318 DIF_a121_badRegReason "Front drive inverter: a121 bad reg reason";
CM_ SG_ 1318 DIF_a121_torqueDelta "Front drive inverter: a121 torque delta";
CM_ SG_ 1318 DIF_a121_badCurrent "Front drive inverter: a121 bad current";
CM_ SG_ 1318 DIF_a121_badFlux "Front drive inverter: a121 bad flux";
CM_ SG_ 1318 DIF_a123_lossReason "Front drive inverter: a123 loss reason";
CM_ SG_ 1318 DIF_a123_busVoltage "Front drive inverter: a123 bus voltage";
CM_ SG_ 1318 DIF_a123_badFlux "Front drive inverter: a123 bad flux";
CM_ SG_ 1318 DIF_a123_lossRequest "Front drive inverter: a123 loss request";
CM_ SG_ 1318 DIF_a123_badCurrent "Front drive inverter: a123 bad current";
CM_ SG_ 1318 DIF_a123_motorRPM "Front drive inverter: a123 motor RPM";
CM_ SG_ 1318 DIF_a123_varianceD "Front drive inverter: a123 variance d";
CM_ SG_ 1318 DIF_a123_varianceQ "Front drive inverter: a123 variance q";
CM_ SG_ 1318 DIF_a126_limpReason "Front drive inverter: a126 limp reason";
CM_ SG_ 1318 DIF_a127_gpoReason "Front drive inverter: a127 gpo reason";
CM_ SG_ 1318 DIF_a127_temp "Front drive inverter: a127 temp";
CM_ SG_ 1318 DIF_a133_capacitorTemp "Front drive inverter: a133 capacitor temp";
CM_ SG_ 1318 DIF_a133_badValue1 "Front drive inverter: a133 bad value1";
CM_ SG_ 1318 DIF_a133_badValue2 "Front drive inverter: a133 bad value2";
CM_ SG_ 1318 DIF_a134_wheelSpeedDiffFrL "Front drive inverter: a134 wheel speed diff fr l";
CM_ SG_ 1318 DIF_a134_wheelSpeedDiffFrR "Front drive inverter: a134 wheel speed diff fr r";
CM_ SG_ 1318 DIF_a134_wheelSpeedDiffReL "Front drive inverter: a134 wheel speed diff re l";
CM_ SG_ 1318 DIF_a134_wheelSpeedDiffReR "Front drive inverter: a134 wheel speed diff re r";
CM_ SG_ 1318 DIF_a136_spiError_BL "Front drive inverter: a136 spi error BL";
CM_ SG_ 1318 DIF_a136_crcError_BL "Front drive inverter: a136 crc error BL";
CM_ SG_ 1318 DIF_a136_busyError_BL "Front drive inverter: a136 busy error BL";
CM_ SG_ 1318 DIF_a136_spiError_BH "Front drive inverter: a136 spi error BH";
CM_ SG_ 1318 DIF_a136_crcError_BH "Front drive inverter: a136 crc error BH";
CM_ SG_ 1318 DIF_a136_busyError_BH "Front drive inverter: a136 busy error BH";
CM_ SG_ 1318 DIF_a136_spiError_CL "Front drive inverter: a136 spi error CL";
CM_ SG_ 1318 DIF_a136_crcError_CL "Front drive inverter: a136 crc error CL";
CM_ SG_ 1318 DIF_a136_busyError_CL "Front drive inverter: a136 busy error CL";
CM_ SG_ 1318 DIF_a136_spiError_CH "Front drive inverter: a136 spi error CH";
CM_ SG_ 1318 DIF_a136_crcError_CH "Front drive inverter: a136 crc error CH";
CM_ SG_ 1318 DIF_a136_busyError_CH "Front drive inverter: a136 busy error CH";
CM_ SG_ 1318 DIF_a136_spiError_AL "Front drive inverter: a136 spi error AL";
CM_ SG_ 1318 DIF_a136_crcError_AL "Front drive inverter: a136 crc error AL";
CM_ SG_ 1318 DIF_a136_busyError_AL "Front drive inverter: a136 busy error AL";
CM_ SG_ 1318 DIF_a136_spiError_AH "Front drive inverter: a136 spi error AH";
CM_ SG_ 1318 DIF_a136_crcError_AH "Front drive inverter: a136 crc error AH";
CM_ SG_ 1318 DIF_a136_busyError_AH "Front drive inverter: a136 busy error AH";
CM_ SG_ 1318 DIF_a144_autopilot "Front drive inverter: a144 autopilot";
CM_ SG_ 1318 DIF_a144_chassisType "Front drive inverter: a144 chassis type";
CM_ SG_ 1318 DIF_a144_drivetrainType "Front drive inverter: a144 drivetrain type";
CM_ SG_ 1318 DIF_a144_packEnergy "Front drive inverter: a144 pack energy";
CM_ SG_ 1318 DIF_a144_packPerformanceDeviatio "Front drive inverter: a144 pack performance deviation";
CM_ SG_ 1318 DIF_a144_performancePackage "Front drive inverter: a144 performance package";
CM_ SG_ 1318 DIF_a144_vdcType "Front drive inverter: a144 vdc type";
CM_ SG_ 1318 DIF_a144_brakeHWType "Front drive inverter: a144 brake HW type";
CM_ SG_ 1318 DIF_a144_inverterHardware "Front drive inverter: a144 inverter hardware";
CM_ SG_ 1318 DIF_a144_cabinPTCHeaterType "Front drive inverter: a144 cabin PTC heater type";
CM_ SG_ 1318 DIF_a144_frunkLatchType "Front drive inverter: a144 frunk latch type";
CM_ SG_ 1318 DIF_a144_platformMaxBusVoltage "Front drive inverter: a144 platform max bus voltage";
CM_ SG_ 1318 DIF_a144_oilPump1HwType "Front drive inverter: a144 oil pump1 hw type";
CM_ SG_ 1318 DIF_a144_oilPump2HwType "Front drive inverter: a144 oil pump2 hw type";
CM_ SG_ 1318 DIF_a144_heatsinkType "Front drive inverter: a144 heatsink type";
CM_ SG_ 1318 DIF_a144_softPerformanceLimit "Front drive inverter: a144 soft performance limit";
CM_ SG_ 1318 DIF_a144_brakeActuationType "Front drive inverter: a144 brake actuation type";
CM_ SG_ 1318 DIF_a144_dasHw "Front drive inverter: a144 das hw";
CM_ SG_ 1318 DIF_a144_powerLiftgateType "Front drive inverter: a144 power liftgate type";
CM_ SG_ 1318 DIF_a144_chassisSubType "Front drive inverter: a144 chassis sub type";
CM_ SG_ 1318 DIF_a144_autonomyFeatureType "Front drive inverter: a144 autonomy feature type";
CM_ SG_ 1318 DIF_a147_overtorque1UsedCount "Front drive inverter: a147 overtorque1 used count";
CM_ SG_ 1318 DIF_a147_overtorque2UsedCount "Front drive inverter: a147 overtorque2 used count";
CM_ SG_ 1318 DIF_a147_accumulatedWear "Front drive inverter: a147 accumulated wear";
CM_ SG_ 1318 DIF_a147_wearIsValid "Front drive inverter: a147 wear is valid";
CM_ SG_ 1318 DIF_a149_flow "Front drive inverter: a149 flow";
CM_ SG_ 1318 DIF_a149_voltage "Front drive inverter: a149 voltage";
CM_ SG_ 1318 DIF_a149_temperature "Front drive inverter: a149 temperature";
CM_ SG_ 1318 DIF_a149_state "Front drive inverter: a149 state";
CM_ SG_ 1318 DIF_a149_fluidTempSNA "Front drive inverter: a149 fluid temp SNA";
CM_ SG_ 1318 DIF_a149_insufficientFlow "Front drive inverter: a149 insufficient flow";
CM_ SG_ 1318 DIF_a149_motorOpenPhase "Front drive inverter: a149 motor open phase";
CM_ SG_ 1318 DIF_a149_motorShorted "Front drive inverter: a149 motor shorted";
CM_ SG_ 1318 DIF_a149_motorFlowSNA "Front drive inverter: a149 motor flow SNA";
CM_ SG_ 1318 DIF_a149_responseError "Front drive inverter: a149 response error";
CM_ SG_ 1318 DIF_a149_pcbaID "Front drive inverter: a149 pcba ID";
CM_ SG_ 1318 DIF_a150_vBatRawMinusFiltered "Front drive inverter: a150 v bat raw minus filtered";
CM_ SG_ 1318 DIF_a150_vBatFilteredRate "Front drive inverter: a150 v bat filtered rate";
CM_ SG_ 1318 DIF_a150_elapsedMs "Front drive inverter: a150 elapsed ms";
CM_ SG_ 1318 DIF_a150_energy "Front drive inverter: a150 energy";
CM_ SG_ 1318 DIF_a152_errorType "Front drive inverter: a152 error type";
CM_ SG_ 1318 DIF_a152_frameId "Front drive inverter: a152 frame id";
CM_ SG_ 1318 DIF_a152_badValue "Front drive inverter: a152 bad value";
CM_ SG_ 1318 DIF_a152_expectedValue "Front drive inverter: a152 expected value";
CM_ SG_ 1318 DIF_a154_motorRPM "Front drive inverter: a154 motor RPM";
CM_ SG_ 1318 DIF_a154_phaseError "Front drive inverter: a154 phase error";
CM_ SG_ 1318 DIF_a154_commonGain "Front drive inverter: a154 common gain";
CM_ SG_ 1318 DIF_a154_noCalibration "Front drive inverter: a154 no calibration";
CM_ SG_ 1318 DIF_a154_noPhaseLock "Front drive inverter: a154 no phase lock";
CM_ SG_ 1318 DIF_a154_noCarrier "Front drive inverter: a154 no carrier";
CM_ SG_ 1318 DIF_a154_notReady "Front drive inverter: a154 not ready";
CM_ SG_ 1318 DIF_a154_errorTableInvalid "Front drive inverter: a154 error table invalid";
CM_ SG_ 1318 DIF_a154_carrierOffset "Front drive inverter: a154 carrier offset";
CM_ SG_ 1318 DIF_a154_trackerIrrational "Front drive inverter: a154 tracker irrational";
CM_ SG_ 1318 DIF_a154_claMIA "Front drive inverter: a154 cla MIA";
CM_ SG_ 1318 DIF_a155_sensors "Front drive inverter: a155 sensors";
CM_ SG_ 1318 DIF_a155_coolant "Front drive inverter: a155 coolant";
CM_ SG_ 1318 DIF_a155_LVPowerState "Front drive inverter: a155 LV power state";
CM_ SG_ 1318 DIF_a155_vehicleStatus "Front drive inverter: a155 vehicle status";
CM_ SG_ 1318 DIF_a155_status "Front drive inverter: a155 status";
CM_ SG_ 1318 DIF_a155_leftDoorStatus "Front drive inverter: a155 left door status";
CM_ SG_ 1318 DIF_a155_rightDoorStatus "Front drive inverter: a155 right door status";
CM_ SG_ 1318 DIF_a155_vcleftSwitchStatus "Front drive inverter: a155 vcleft switch status";
CM_ SG_ 1318 DIF_a155_restraintStatus "Front drive inverter: a155 restraint status";
CM_ SG_ 1318 DIF_a155_systemStatus "Front drive inverter: a155 system status";
CM_ SG_ 1318 DIF_a155_prndStatus "Front drive inverter: a155 prnd status";
CM_ SG_ 1318 DIF_a155_liftgateStatus "Front drive inverter: a155 liftgate status";
CM_ SG_ 1318 DIF_a157_RCM_inertial1 "Front drive inverter: a157 RCM inertial1";
CM_ SG_ 1318 DIF_a157_RCM_inertial2 "Front drive inverter: a157 RCM inertial2";
CM_ SG_ 1318 DIF_a158_IBST_party1 "Front drive inverter: a158 IBST party1";
CM_ SG_ 1318 DIF_a158_BUS1_IBST_status "Front drive inverter: a158 BUS1 IBST status";
CM_ SG_ 1318 DIF_a158_BUS2_IBST_status "Front drive inverter: a158 BUS2 IBST status";
CM_ SG_ 1318 DIF_a158_IBST_redundantBrakingSt "Front drive inverter: a158 IBST redundant braking status";
CM_ SG_ 1318 DIF_a160_vBatRawMinusFiltered "Front drive inverter: a160 v bat raw minus filtered";
CM_ SG_ 1318 DIF_a160_vBatFilteredRate "Front drive inverter: a160 v bat filtered rate";
CM_ SG_ 1318 DIF_a160_elapsedMs "Front drive inverter: a160 elapsed ms";
CM_ SG_ 1318 DIF_a160_energy "Front drive inverter: a160 energy";
CM_ SG_ 1318 DIF_a161_EPAS3P_sysStatus "Front drive inverter: a161 EPAS3 p sys status";
CM_ SG_ 1318 DIF_a161_EPAS3P_angleCalib "Front drive inverter: a161 EPAS3 p angle calib";
CM_ SG_ 1318 DIF_a172_statorTemp1 "Front drive inverter: a172 stator temp1";
CM_ SG_ 1318 DIF_a172_statorTemp2 "Front drive inverter: a172 stator temp2";
CM_ SG_ 1318 DIF_a202_reason "Front drive inverter: a202 reason";
CM_ SG_ 1318 DIF_a202_movement "Front drive inverter: a202 movement";
CM_ SG_ 1318 DIF_a202_sysStateExitCondition "Front drive inverter: a202 sys state exit condition";
CM_ SG_ 1318 DIF_a233_missedMsgCount "Front drive inverter: a233 missed msg count";
CM_ SG_ 1318 DIF_a233_serviceModeActive "Signal reported by Front drive inverter";
CM_ SG_ 1318 DIF_a234_PCS_dcdcStatus "Front drive inverter: a234 PCS dcdc status";
CM_ SG_ 1318 DIF_a236_states "Front drive inverter: a236 states";
CM_ SG_ 1318 DIF_a240_shortedSwitches "Front drive inverter: a240 shorted switches";
CM_ SG_ 1318 DIF_a240_primaryPattern "Front drive inverter: a240 primary pattern";
CM_ SG_ 1318 DIF_a240_secondaryPattern "Front drive inverter: a240 secondary pattern";
CM_ SG_ 1318 DIF_a240_fuseA_I2t "Front drive inverter: a240 fuse a i2t";
CM_ SG_ 1318 DIF_a240_fuseB_I2t "Front drive inverter: a240 fuse b i2t";
CM_ SG_ 1318 DIF_a240_primaryTimeout "Front drive inverter: a240 primary timeout";
CM_ SG_ 1318 DIF_a240_secondaryTimeout "Front drive inverter: a240 secondary timeout";
CM_ SG_ 1318 DIF_a240_primNoCurrentA "Front drive inverter: a240 prim no current a";
CM_ SG_ 1318 DIF_a240_primNoCurrentB "Front drive inverter: a240 prim no current b";
CM_ SG_ 1318 DIF_a240_secNoCurrentA "Front drive inverter: a240 sec no current a";
CM_ SG_ 1318 DIF_a240_secNoCurrentB "Front drive inverter: a240 sec no current b";
CM_ SG_ 1318 DIF_a240_primaryDutyCycle "Front drive inverter: a240 primary duty cycle";
CM_ SG_ 1318 DIF_a240_secondaryDutyCycle "Front drive inverter: a240 secondary duty cycle";
CM_ SG_ 1318 DIF_a240_confNoCurrentDetected "Front drive inverter: a240 conf no current detected";
CM_ SG_ 1318 DIF_a240_secondaryStrategy3ps "Front drive inverter: a240 secondary strategy3ps";
CM_ SG_ 1318 DIF_a242_RotorOffset "Front drive inverter: a242 rotor offset";
CM_ SG_ 1318 DIF_a242_RotorFlux "Front drive inverter: a242 rotor flux";
CM_ SG_ 1318 DIF_a242_ResolverError "Front drive inverter: a242 resolver error";
CM_ SG_ 1318 DIF_a244_desatHighSide "Front drive inverter: a244 desat high side";
CM_ SG_ 1318 DIF_a244_desatLowSide "Front drive inverter: a244 desat low side";
CM_ SG_ 1318 DIF_a244_singleSwitchShort "Front drive inverter: a244 single switch short";
CM_ SG_ 1318 DIF_a244_flybackFault "Front drive inverter: a244 flyback fault";
CM_ SG_ 1318 DIF_a244_postShortTestFailed "Front drive inverter: a244 post short test failed";
CM_ SG_ 1318 DIF_a244_udsSelfTest "Front drive inverter: a244 uds self test";
CM_ SG_ 1318 DIF_a244_irSensorV "Front drive inverter: a244 ir sensor v";
CM_ SG_ 1318 DIF_a244_gateDriveICUndervoltage "Front drive inverter: a244 gate drive IC undervoltage";
CM_ SG_ 1318 DIF_a244_plausibleSingleSwitchSh "Front drive inverter: a244 plausible single switch short only";
CM_ SG_ 1318 DIF_a244_delay "Front drive inverter: a244 delay";
CM_ SG_ 1318 DIF_a246_atSpeedDIResetCount "Front drive inverter: a246 at speed DI reset count";
CM_ SG_ 1318 DIF_a246_didPMCauseSwitchOf_0001 "Front drive inverter: a246 did PM cause switch off path nominal";
CM_ SG_ 1318 DIF_a246_didPMCauseSwitchOffPath "Front drive inverter: a246 did PM cause switch off path low speed";
CM_ SG_ 1318 DIF_a246_currentSensorRational "Front drive inverter: a246 current sensor rational";
CM_ SG_ 1318 DIF_a246_observerDetectedSw_0001 "Front drive inverter: a246 observer detected switch off path nominal";
CM_ SG_ 1318 DIF_a246_observerDetectedSwitchO "Front drive inverter: a246 observer detected switch off path low speed";
CM_ SG_ 1318 DIF_a246_hvIsGood "Front drive inverter: a246 hv is good";
CM_ SG_ 1318 DIF_a246_lvIsGood "Front drive inverter: a246 lv is good";
CM_ SG_ 1318 DIF_a246_codeBranch "Front drive inverter: a246 code branch";
CM_ SG_ 1318 DIF_a246_motorRPM "Front drive inverter: a246 motor RPM";
CM_ SG_ 1318 DIF_a246_eepromOffsetIa "Front drive inverter: a246 eeprom offset ia";
CM_ SG_ 1318 DIF_a246_eepromOffsetIb "Front drive inverter: a246 eeprom offset ib";
CM_ SG_ 1318 DIF_a246_soptPreviouslyPassed "Front drive inverter: a246 sopt previously passed";
CM_ SG_ 1318 DIF_a246_lowSpeedRecoveryEnabled "Front drive inverter: a246 low speed recovery enabled";
CM_ SG_ 1318 DIF_a247_rotorOffsetEst "Front drive inverter: a247 rotor offset est";
CM_ SG_ 1318 DIF_a247_motorRPM "Front drive inverter: a247 motor RPM";
CM_ SG_ 1318 DIF_a247_torqueMotor "Front drive inverter: a247 torque motor";
CM_ SG_ 1318 DIF_a251_oilFlow "Front drive inverter: a251 oil flow";
CM_ SG_ 1318 DIF_a251_oilTemperature "Front drive inverter: a251 oil temperature";
CM_ SG_ 1318 DIF_a251_dcVoltage "Front drive inverter: a251 dc voltage";
CM_ SG_ 1318 DIF_a251_dcCurrent "Front drive inverter: a251 dc current";
CM_ SG_ 1318 DIF_a251_phaseCurrent "Front drive inverter: a251 phase current";
CM_ SG_ 1318 DIF_a251_leadAngle "Front drive inverter: a251 lead angle";
CM_ SG_ 1318 DIF_a251_reason "Front drive inverter: a251 reason";
CM_ SG_ 1318 DIF_a253_voltage "Front drive inverter: a253 voltage";
CM_ SG_ 1318 DIF_a253_reason "Front drive inverter: a253 reason";
BA_DEF_ BO_ "GenMsgCycleTime" INT 0 3600000;
BA_DEF_ BO_ "GenMsgSendType" ENUM "Cyclic","NotUsed","NotUsed","NotUsed","NotUsed","NotUsed","NotUsed","IfActive","NoMsgSendType","NotUsed";
BA_DEF_ BO_ "VFrameFormat" ENUM "StandardCAN","ExtendedCAN","reserved","J1939PG","reserved","reserved","reserved","reserved","reserved","reserved","reserved","reserved","reserved","reserved","StandardCAN_FD","ExtendedCAN_FD";
BA_DEF_ BO_ "CANFD_BRS" ENUM "0","1";
BA_DEF_ SG_ "SystemSignalLongSymbol" STRING;
BA_DEF_ SG_ "Confidence" ENUM "layout-only","plausible","validated";
BA_DEF_DEF_ "GenMsgCycleTime" 0;
BA_DEF_DEF_ "GenMsgSendType" "NoMsgSendType";
BA_DEF_DEF_ "VFrameFormat" "StandardCAN";
BA_DEF_DEF_ "CANFD_BRS" "1";
BA_DEF_DEF_ "SystemSignalLongSymbol" "";
BA_DEF_DEF_ "Confidence" "layout-only";
BA_ "Confidence" SG_ 697 DAS_setSpeed 1;
BA_ "Confidence" SG_ 697 DAS_accState 1;
BA_ "Confidence" SG_ 697 DAS_aebEvent 1;
BA_ "Confidence" SG_ 697 DAS_jerkMin 1;
BA_ "Confidence" SG_ 697 DAS_jerkMax 1;
BA_ "Confidence" SG_ 697 DAS_accelMin 1;
BA_ "Confidence" SG_ 697 DAS_accelMax 1;
BA_ "Confidence" SG_ 2040 DAS_gpsTransportModeState 1;
BA_ "Confidence" SG_ 2040 DAS_gpsSatsInUseHardware 1;
BA_ "Confidence" SG_ 2040 DAS_gpsRejectingSatData 1;
BA_ "Confidence" SG_ 2040 DAS_gpsWheelsOffMotionDetected 1;
BA_ "Confidence" SG_ 2040 DAS_gpsFixTypeHardware 1;
BA_ "Confidence" SG_ 2040 DAS_gpsRawxEnabled 1;
BA_ "Confidence" SG_ 2040 DAS_gpsEsfMeasMia 1;
BA_ "Confidence" SG_ 2040 DAS_gpsEsfRawMia 1;
BA_ "Confidence" SG_ 2040 DAS_gpsNavStatusMia 1;
BA_ "Confidence" SG_ 2040 DAS_gpsSoftwareConfigured 1;
BA_ "Confidence" SG_ 2040 DAS_gpsSoftwareUsed 1;
BA_ "Confidence" SG_ 2040 DAS_gpsSoftwareFastStartReady 1;
BA_ "Confidence" SG_ 2040 DAS_gpsSatsInUseSoftware 1;
BA_ "Confidence" SG_ 2040 DAS_gpsFixTypeSoftware 1;
BA_ "Confidence" SG_ 2040 DAS_gpsCWJammingInidcator 1;
BA_ "Confidence" SG_ 2040 DAS_gpsJammingState 1;
BA_ "Confidence" SG_ 2040 DAS_gpsSpoofDetectorState 1;
BA_ "Confidence" SG_ 2040 DAS_gpsInvalidMsgPercentage 1;
BA_ "Confidence" SG_ 2040 DAS_gnssConstellationsState 1;
BA_ "Confidence" SG_ 2040 DAS_gpsReceiverNoiseLevel 1;
BA_ "Confidence" SG_ 2040 DAS_gpsAutomaticGainControl 1;
BA_ "Confidence" SG_ 2040 DAS_gpsPreviousPositionDeltaHw 1;
BA_ "Confidence" SG_ 2040 DAS_gpsPreviousPositionDeltaSw 1;
BA_ "Confidence" SG_ 2040 DAS_gpsNmeaDispatchFailureCount 1;
BA_ "Confidence" SG_ 2040 DAS_gnssMaxInstantaneousCnorGps 1;
BA_ "Confidence" SG_ 2040 DAS_gnssMaxInstantaneousCnorGal 1;
BA_ "Confidence" SG_ 2040 DAS_gnssMaxInstantaneousCnorBds 1;
BA_ "Confidence" SG_ 2040 DAS_gpsResetReason 1;
BA_ "Confidence" SG_ 2040 DAS_gpsAccuracyHorizontal 1;
BA_ "Confidence" SG_ 2040 DAS_gpsAccuracyVertical 1;
BA_ "Confidence" SG_ 2040 DAS_gpsSolutionFallback 1;
BA_ "Confidence" SG_ 2040 DAS_gpsToMcuSource 1;
BA_ "Confidence" SG_ 2040 DAS_gpsSolutionSoc 1;
BA_ "Confidence" SG_ 2040 DAS_gpsRedundancyActive 1;
BA_ "Confidence" SG_ 2040 DAS_gpsFixTypeSoftwareSocB 1;
BA_ "Confidence" SG_ 2040 DAS_gpsSatsInUseSoftwareSocB 1;
BA_ "Confidence" SG_ 2040 DAS_gnssNumSatsGps 1;
BA_ "Confidence" SG_ 2040 DAS_gnssNumSatsGal 1;
BA_ "Confidence" SG_ 2040 DAS_gnssNumSatsBds 1;
BA_ "Confidence" SG_ 2040 DAS_gnssAvgInstantaneousCnorGps 1;
BA_ "Confidence" SG_ 2040 DAS_gnssAvgInstantaneousCnorGal 1;
BA_ "Confidence" SG_ 2040 DAS_gnssAvgInstantaneousCnorBds 1;
BA_ "Confidence" SG_ 2040 DAS_gnssAvgInstantaneousCnorGpsL 1;
BA_ "SystemSignalLongSymbol" SG_ 2040 DAS_gnssAvgInstantaneousCnorGpsL "DAS_gnssAvgInstantaneousCnorGpsLowBand";
BA_ "Confidence" SG_ 2040 DAS_gnssAvgInstantaneousCnorGalL 1;
BA_ "SystemSignalLongSymbol" SG_ 2040 DAS_gnssAvgInstantaneousCnorGalL "DAS_gnssAvgInstantaneousCnorGalLowBand";
BA_ "Confidence" SG_ 2040 DAS_gnssAvgInstantaneousCnorBdsL 1;
BA_ "SystemSignalLongSymbol" SG_ 2040 DAS_gnssAvgInstantaneousCnorBdsL "DAS_gnssAvgInstantaneousCnorBdsLowBand";
BA_ "Confidence" SG_ 1337 DAS_infoBuildType 1;
BA_ "Confidence" SG_ 569 DAS_virtualLaneWidth 1;
BA_ "Confidence" SG_ 569 DAS_virtualLaneViewRange 1;
BA_ "Confidence" SG_ 569 DAS_virtualLaneC0 1;
BA_ "Confidence" SG_ 569 DAS_virtualLaneC1 1;
BA_ "Confidence" SG_ 569 DAS_virtualLaneC2 1;
BA_ "Confidence" SG_ 569 DAS_virtualLaneC3 1;
BA_ "Confidence" SG_ 569 DAS_leftLineUsage 1;
BA_ "Confidence" SG_ 569 DAS_rightLineUsage 1;
BA_ "Confidence" SG_ 569 DAS_leftFork 1;
BA_ "Confidence" SG_ 569 DAS_rightFork 1;
BA_ "Confidence" SG_ 778 DAS_leadVehType 1;
BA_ "Confidence" SG_ 778 DAS_leadVehDx 1;
BA_ "Confidence" SG_ 778 DAS_leadVehVxRel 1;
BA_ "Confidence" SG_ 778 DAS_leadVehDy 1;
BA_ "Confidence" SG_ 778 DAS_leadVeh2Type 1;
BA_ "Confidence" SG_ 778 DAS_leadVeh2Dx 1;
BA_ "Confidence" SG_ 778 DAS_leadVeh2VxRel 1;
BA_ "Confidence" SG_ 778 DAS_leadVeh2Dy 1;
BA_ "Confidence" SG_ 778 DAS_leftVehType 1;
BA_ "Confidence" SG_ 778 DAS_leftVehDx 1;
BA_ "Confidence" SG_ 778 DAS_leftVehVxRel 1;
BA_ "Confidence" SG_ 778 DAS_leftVehDy 1;
BA_ "Confidence" SG_ 778 DAS_leftVeh2Type 1;
BA_ "Confidence" SG_ 778 DAS_leftVeh2Dx 1;
BA_ "Confidence" SG_ 778 DAS_leftVeh2VxRel 1;
BA_ "Confidence" SG_ 778 DAS_leftVeh2Dy 1;
BA_ "Confidence" SG_ 778 DAS_rightVehType 1;
BA_ "Confidence" SG_ 778 DAS_rightVehDx 1;
BA_ "Confidence" SG_ 778 DAS_rightVehVxRel 1;
BA_ "Confidence" SG_ 778 DAS_rightVehDy 1;
BA_ "Confidence" SG_ 778 DAS_rightVeh2Type 1;
BA_ "Confidence" SG_ 778 DAS_rightVeh2Dx 1;
BA_ "Confidence" SG_ 778 DAS_rightVeh2VxRel 1;
BA_ "Confidence" SG_ 778 DAS_rightVeh2Dy 1;
BA_ "Confidence" SG_ 778 DAS_cutinVehType 1;
BA_ "Confidence" SG_ 778 DAS_cutinVehDx 1;
BA_ "Confidence" SG_ 778 DAS_cutinVehVxRel 1;
BA_ "Confidence" SG_ 778 DAS_cutinVehDy 1;
BA_ "Confidence" SG_ 778 DAS_roadSignColor 1;
BA_ "Confidence" SG_ 778 DAS_roadSignId 1;
BA_ "Confidence" SG_ 778 DAS_roadSignStopLineDist 1;
BA_ "Confidence" SG_ 778 DAS_roadSignSource 1;
BA_ "Confidence" SG_ 778 DAS_roadSignArrow 1;
BA_ "Confidence" SG_ 778 DAS_roadSignOrientation 1;
BA_ "SystemSignalLongSymbol" SG_ 781 DAS_positioningEngineStatusMulti "DAS_positioningEngineStatusMultiplexer";
BA_ "Confidence" SG_ 781 DAS_meoSolverNumRuns 1;
BA_ "Confidence" SG_ 781 DAS_meoSolverReportTerminationTy 1;
BA_ "SystemSignalLongSymbol" SG_ 781 DAS_meoSolverReportTerminationTy "DAS_meoSolverReportTerminationType";
BA_ "Confidence" SG_ 781 DAS_meoSolverReportTotalTimeS 1;
BA_ "Confidence" SG_ 781 DAS_meoHorizontalAccuracyM 1;
BA_ "Confidence" SG_ 781 DAS_meoVerticalAccuracyM 1;
BA_ "Confidence" SG_ 781 DAS_meoHeadingAccuracyDeg 1;
BA_ "Confidence" SG_ 781 DAS_meoHeadingValid 1;
BA_ "Confidence" SG_ 781 DAS_meoGpsQualityLevel 1;
BA_ "Confidence" SG_ 781 DAS_meoFixType 1;
BA_ "Confidence" SG_ 781 DAS_lastMeoResetReason 1;
BA_ "Confidence" SG_ 781 DAS_vioMultiGpsSelectedSource 1;
BA_ "Confidence" SG_ 781 DAS_vioMultiGpsPeCooldownActive 1;
BA_ "Confidence" SG_ 781 DAS_vioMultiGpsPeSppTdcpConsiste 1;
BA_ "SystemSignalLongSymbol" SG_ 781 DAS_vioMultiGpsPeSppTdcpConsiste "DAS_vioMultiGpsPeSppTdcpConsistentWithRawGps";
BA_ "Confidence" SG_ 781 DAS_vioMultiGpsPeMeoConsistentWi 1;
BA_ "SystemSignalLongSymbol" SG_ 781 DAS_vioMultiGpsPeMeoConsistentWi "DAS_vioMultiGpsPeMeoConsistentWithRawGps";
BA_ "Confidence" SG_ 781 DAS_vioMultiGpsPeSppTdcpVsR_0001 1;
BA_ "SystemSignalLongSymbol" SG_ 781 DAS_vioMultiGpsPeSppTdcpVsR_0001 "DAS_vioMultiGpsPeSppTdcpVsRawGpsTransDiscrepM";
BA_ "Confidence" SG_ 781 DAS_vioMultiGpsPeMeoVsRawGpsTran 1;
BA_ "SystemSignalLongSymbol" SG_ 781 DAS_vioMultiGpsPeMeoVsRawGpsTran "DAS_vioMultiGpsPeMeoVsRawGpsTransDiscrepM";
BA_ "Confidence" SG_ 781 DAS_vioMultiGpsPeSppTdcpVsRawGps 1;
BA_ "SystemSignalLongSymbol" SG_ 781 DAS_vioMultiGpsPeSppTdcpVsRawGps "DAS_vioMultiGpsPeSppTdcpVsRawGpsRotDiscrepDeg";
BA_ "Confidence" SG_ 781 DAS_vioMultiGpsPeMeoVsRawGpsRotD 1;
BA_ "SystemSignalLongSymbol" SG_ 781 DAS_vioMultiGpsPeMeoVsRawGpsRotD "DAS_vioMultiGpsPeMeoVsRawGpsRotDiscrepDeg";
BA_ "Confidence" SG_ 781 DAS_publishedGpsSource 1;
BA_ "Confidence" SG_ 781 DAS_bluefinEnabled 1;
BA_ "Confidence" SG_ 781 DAS_orioleDisabled 1;
BA_ "Confidence" SG_ 781 DAS_disableMonarch 1;
BA_ "Confidence" SG_ 299 DAS_smartShiftTorqueDirection 1;
BA_ "Confidence" SG_ 299 DAS_smartShiftTorqueReason 1;
BA_ "Confidence" SG_ 299 DAS_autoshiftTorqueDirectionDbg 1;
BA_ "Confidence" SG_ 299 DAS_autoshiftUpcomingDirection 1;
BA_ "Confidence" SG_ 299 DAS_autoshiftBrakeRequired 1;
BA_ "Confidence" SG_ 299 DAS_autoshiftSteerRequest 1;
BA_ "Confidence" SG_ 921 DAS_autopilotState 1;
BA_ "Confidence" SG_ 921 DAS_blindSpotRearLeft 1;
BA_ "Confidence" SG_ 921 DAS_blindSpotRearRight 1;
BA_ "Confidence" SG_ 921 DAS_fusedSpeedLimit 1;
BA_ "Confidence" SG_ 921 DAS_suppressSpeedWarning 1;
BA_ "Confidence" SG_ 921 DAS_visionOnlySpeedLimit 1;
BA_ "Confidence" SG_ 921 DAS_heaterState 1;
BA_ "Confidence" SG_ 921 DAS_forwardCollisionWarning 1;
BA_ "Confidence" SG_ 921 DAS_autoparkReady 1;
BA_ "Confidence" SG_ 921 DAS_autoparkActive 1;
BA_ "Confidence" SG_ 921 DAS_lssState 1;
BA_ "Confidence" SG_ 921 DAS_sideCollisionAvoid 1;
BA_ "Confidence" SG_ 921 DAS_sideCollisionWarning 1;
BA_ "Confidence" SG_ 921 DAS_sideCollisionInhibit 1;
BA_ "Confidence" SG_ 921 DAS_laneDepartureWarning 1;
BA_ "Confidence" SG_ 921 DAS_fleetSpeedState 1;
BA_ "Confidence" SG_ 921 DAS_autopilotHandsOnState 1;
BA_ "Confidence" SG_ 921 DAS_autoLaneChangeState 1;
BA_ "Confidence" SG_ 905 DAS_accSpeedLimit 1;
BA_ "Confidence" SG_ 905 DAS_pmmObstacleSeverity 1;
BA_ "Confidence" SG_ 905 DAS_pmmLoggingRequest 1;
BA_ "Confidence" SG_ 905 DAS_activationFailureStatus 1;
BA_ "Confidence" SG_ 905 DAS_pmmUltrasonicsFaultReason 1;
BA_ "Confidence" SG_ 905 DAS_pmmRadarFaultReason 1;
BA_ "Confidence" SG_ 905 DAS_pmmSysFaultReason 1;
BA_ "Confidence" SG_ 905 DAS_pmmCameraFaultReason 1;
BA_ "Confidence" SG_ 905 DAS_ACC_report 1;
BA_ "Confidence" SG_ 905 DAS_relaxCruiseLimits 1;
BA_ "Confidence" SG_ 905 DAS_csaState 1;
BA_ "Confidence" SG_ 905 DAS_radarTelemetry 1;
BA_ "Confidence" SG_ 905 DAS_robState 1;
BA_ "Confidence" SG_ 905 DAS_driverInteractionLevel 1;
BA_ "Confidence" SG_ 905 DAS_ppOffsetDesiredRamp 1;
BA_ "Confidence" SG_ 905 DAS_longCollisionWarning 1;
BA_ "Confidence" SG_ 1548 DAS_TR_Obj00_Class 1;
BA_ "Confidence" SG_ 1548 DAS_TR_Obj00_Dx 1;
BA_ "Confidence" SG_ 1548 DAS_TR_Obj00_Dy 1;
BA_ "Confidence" SG_ 1548 DAS_TR_Obj00_Vx 1;
BA_ "Confidence" SG_ 1548 DAS_TR_Obj00_RCS 1;
BA_ "Confidence" SG_ 1548 DAS_TR_Obj00_Length 1;
BA_ "Confidence" SG_ 1548 DAS_TR_Obj00_MovingState 1;
BA_ "Confidence" SG_ 1548 DAS_TR_Obj00_Dz 1;
BA_ "Confidence" SG_ 1548 DAS_TR_Obj00_Exist 1;
BA_ "Confidence" SG_ 586 DAS_autosteerVehiclesUsage 1;
BA_ "Confidence" SG_ 586 DAS_autosteerHPPUsage 1;
BA_ "Confidence" SG_ 586 DAS_autosteerNavigationUsage 1;
BA_ "Confidence" SG_ 586 DAS_autosteerModelUsage 1;
BA_ "Confidence" SG_ 586 DAS_autosteerBottsDotsUsage 1;
BA_ "Confidence" SG_ 586 DAS_offsetSide 1;
BA_ "Confidence" SG_ 586 DAS_roadSurfaceType 1;
BA_ "Confidence" SG_ 586 DAS_autosteerHealthState 1;
BA_ "Confidence" SG_ 586 DAS_lastLinePreferenceReason 1;
BA_ "Confidence" SG_ 586 DAS_plannerState 1;
BA_ "Confidence" SG_ 586 DAS_lastAutosteerAbortReason 1;
BA_ "Confidence" SG_ 586 DAS_navAvailable 1;
BA_ "Confidence" SG_ 586 DAS_navDistance 1;
BA_ "Confidence" SG_ 586 DAS_accSmartSpeedState 1;
BA_ "Confidence" SG_ 586 DAS_ulcInProgress 1;
BA_ "Confidence" SG_ 586 DAS_trafficAwareSetSpeedInUse 1;
BA_ "Confidence" SG_ 586 DAS_isaSystemState 1;
BA_ "Confidence" SG_ 586 DAS_behaviorType 1;
BA_ "Confidence" SG_ 586 DAS_ulcType 1;
BA_ "Confidence" SG_ 586 DAS_rearVehDetectedThisCycle 1;
BA_ "Confidence" SG_ 586 DAS_rearLeftVehDetectedCurrent 1;
BA_ "Confidence" SG_ 586 DAS_rearRightVehDetectedTrip 1;
BA_ "Confidence" SG_ 586 DAS_rearLeftVehDetectedTrip 1;
BA_ "SystemSignalLongSymbol" SG_ 1318 DIF_a091_ESP_redundantBrakingSta "DIF_a091_ESP_redundantBrakingStatus";
BA_ "SystemSignalLongSymbol" SG_ 1318 DIF_a144_packPerformanceDeviatio "DIF_a144_packPerformanceDeviation";
BA_ "SystemSignalLongSymbol" SG_ 1318 DIF_a158_IBST_redundantBrakingSt "DIF_a158_IBST_redundantBrakingStatus";
BA_ "SystemSignalLongSymbol" SG_ 1318 DIF_a244_plausibleSingleSwitchSh "DIF_a244_plausibleSingleSwitchShortOnly";
BA_ "SystemSignalLongSymbol" SG_ 1318 DIF_a246_didPMCauseSwitchOf_0001 "DIF_a246_didPMCauseSwitchOffPathNominal";
BA_ "SystemSignalLongSymbol" SG_ 1318 DIF_a246_didPMCauseSwitchOffPath "DIF_a246_didPMCauseSwitchOffPathLowSpeed";
BA_ "SystemSignalLongSymbol" SG_ 1318 DIF_a246_observerDetectedSw_0001 "DIF_a246_observerDetectedSwitchOffPathNominal";
BA_ "SystemSignalLongSymbol" SG_ 1318 DIF_a246_observerDetectedSwitchO "DIF_a246_observerDetectedSwitchOffPathLowSpeed";
VAL_ 697 DAS_accState 15 "FAULT_SNA" 13 "ACC_CANCEL_GENERIC_SILENT" 12 "ACC_PARK" 11 "APC_SELFPARK_START" 10 "APC_UNPARK_COMPLETE" 9 "APC_PAUSE" 8 "APC_ABORT" 7 "APC_COMPLETE" 6 "APC_FORWARD" 5 "APC_BACKWARD" 4 "ACC_ON" 3 "ACC_HOLD" 2 "ACC_FORWARD" 1 "ACC_BACKWARD" 0 "ACC_CANCEL_GENERIC" ;
VAL_ 697 DAS_aebEvent 3 "AEB_SNA" 2 "AEB_FAULT" 1 "AEB_ACTIVE" 0 "AEB_NOT_ACTIVE" ;
VAL_ 2040 DAS_gpsTransportModeState 1 "DAS_GPS_TRANSPORT_MODE_ON" 0 "DAS_GPS_TRANSPORT_MODE_OFF" ;
VAL_ 2040 DAS_gpsWheelsOffMotionDetected 1 "DAS_GPS_MOTION_DETECTED_ON" 0 "DAS_GPS_MOTION_DETECTED_OFF" ;
VAL_ 2040 DAS_gpsFixTypeHardware 6 "DEAD_RECOCKONING_FIX" 5 "FLOAT_RTK_FIX" 4 "REAL_TIME_KINEMATICS_FIX" 3 "PPS_FIX" 2 "DGPS_FIX" 1 "GPS_FIX" 0 "INVALID_FIX" ;
VAL_ 2040 DAS_gpsFixTypeSoftware 6 "DEAD_RECOCKONING_FIX" 5 "FLOAT_RTK_FIX" 4 "REAL_TIME_KINEMATICS_FIX" 3 "PPS_FIX" 2 "DGPS_FIX" 1 "GPS_FIX" 0 "INVALID_FIX" ;
VAL_ 2040 DAS_gpsJammingState 3 "GPS_JAMMING_STATE_CRITICAL" 2 "GPS_JAMMING_STATE_WARNING" 1 "GPS_JAMMING_STATE_NOMINAL" 0 "GPS_JAMMING_STATE_UNKNOWN" ;
VAL_ 2040 DAS_gpsSpoofDetectorState 3 "GPS_SPOOFING_MULTIPLE_INDICATIONS" 2 "GPS_SPOOFING_INDICATION_PRESENT" 1 "GPS_SPOOFING_NO_ACTIVE_INDICATION" 0 "GPS_SPOOFING_UNKNOWN" ;
VAL_ 2040 DAS_gnssConstellationsState 2 "CONSTELLATIONS_STATE_VALID" 1 "CONSTELLATIONS_STATE_INVALID" 0 "CONSTELLATIONS_STATE_UNKNOWN" ;
VAL_ 2040 DAS_gpsResetReason 13 "GPS_RESET_PPS_MISSING" 12 "GPS_RESET_SOLUTION_INCONSISTENCY" 11 "GPS_RESET_MANUAL_COLD_RESET" 10 "GPS_RESET_GNSS_CFG_CHANGE" 9 "GPS_RESET_RESUME_CONFIGURATION_FAULT" 8 "GPS_RESET_SUSPEND_CONFIGURATION_FAULT" 7 "GPS_RESET_SATELLITE_REJECTION_TIMEOUT" 6 "GPS_RESET_ENTER_TRANSPORT_MODE" 5 "GPS_RESET_EXIT_TRANSPORT_MODE" 4 "GPS_RESET_GNSS_DATA_MISSING" 3 "GPS_RESET_UBX_MISSING" 2 "GPS_RESET_DATA_CORRUPTED" 1 "GPS_RESET_DATA_MISSING" 0 "GPS_RESET_NONE" ;
VAL_ 2040 DAS_gpsToMcuSource 4 "GPS_TO_MCU_SOURCE_BLUEFIN_SOLUTION" 3 "GPS_TO_MCU_SOURCE_TESLA_VIO_SOLUTION" 2 "GPS_TO_MCU_SOURCE_SOFTWARE_SOLUTION" 1 "GPS_TO_MCU_SOURCE_HARDWARE_SOLUTION" 0 "GPS_TO_MCU_SOURCE_UNKNOWN" ;
VAL_ 2040 DAS_gpsSolutionSoc 2 "GPS_SOLUTION_SOC_B" 1 "GPS_SOLUTION_SOC_A" 0 "GPS_SOLUTION_SOC_UNKNOWN" ;
VAL_ 2040 DAS_gpsFixTypeSoftwareSocB 6 "DEAD_RECOCKONING_FIX" 5 "FLOAT_RTK_FIX" 4 "REAL_TIME_KINEMATICS_FIX" 3 "PPS_FIX" 2 "DGPS_FIX" 1 "GPS_FIX" 0 "INVALID_FIX" ;
VAL_ 1337 DAS_infoBuildType 4 "INFO_MFG_BUILD" 3 "INFO_TRACEABLE_CI_BUILD" 2 "INFO_LOCAL_BUILD" 1 "INFO_PLATFORM_BUILD" 0 "INFO_UNKNOWN_BUILD" ;
VAL_ 569 DAS_leftLineUsage 3 "BLACKLISTED" 2 "FUSED" 1 "AVAILABLE" 0 "REJECTED_UNAVAILABLE" ;
VAL_ 569 DAS_rightLineUsage 3 "BLACKLISTED" 2 "FUSED" 1 "AVAILABLE" 0 "REJECTED_UNAVAILABLE" ;
VAL_ 569 DAS_leftFork 3 "FORK_UNAVAILABLE" 2 "FORK_SELECTED" 1 "FORK_AVAILABLE" 0 "FORK_NONE" ;
VAL_ 569 DAS_rightFork 3 "FORK_UNAVAILABLE" 2 "FORK_SELECTED" 1 "FORK_AVAILABLE" 0 "FORK_NONE" ;
VAL_ 778 DAS_leadVehType 6 "IPSO" 5 "PEDESTRIAN" 4 "BICYCLE" 3 "MOTORCYCLE" 2 "CAR" 1 "TRUCK" 0 "UNKNOWN" ;
VAL_ 778 DAS_leadVeh2Type 5 "PEDESTRIAN" 4 "BICYCLE" 3 "MOTORCYCLE" 2 "CAR" 1 "TRUCK" 0 "UNKNOWN" ;
VAL_ 778 DAS_leftVehType 5 "PEDESTRIAN" 4 "BICYCLE" 3 "MOTORCYCLE" 2 "CAR" 1 "TRUCK" 0 "UNKNOWN" ;
VAL_ 778 DAS_leftVeh2Type 5 "PEDESTRIAN" 4 "BICYCLE" 3 "MOTORCYCLE" 2 "CAR" 1 "TRUCK" 0 "UNKNOWN" ;
VAL_ 778 DAS_rightVehType 5 "PEDESTRIAN" 4 "BICYCLE" 3 "MOTORCYCLE" 2 "CAR" 1 "TRUCK" 0 "UNKNOWN" ;
VAL_ 778 DAS_rightVeh2Type 5 "PEDESTRIAN" 4 "BICYCLE" 3 "MOTORCYCLE" 2 "CAR" 1 "TRUCK" 0 "UNKNOWN" ;
VAL_ 778 DAS_cutinVehType 5 "PEDESTRIAN" 4 "BICYCLE" 3 "MOTORCYCLE" 2 "CAR" 1 "TRUCK" 0 "UNKNOWN" ;
VAL_ 778 DAS_roadSignColor 4 "RED_YELLOW" 3 "GREEN" 2 "YELLOW" 1 "RED" 0 "NONE" ;
VAL_ 778 DAS_roadSignId 1 "TRAFFIC_LIGHT" 0 "STOP_SIGN" ;
VAL_ 778 DAS_roadSignSource 2 "VISION" 1 "NAV" 0 "NONE" ;
VAL_ 778 DAS_roadSignArrow 4 "UNKNOWN" 3 "STRAIGHT" 2 "RIGHT" 1 "LEFT" 0 "CIRCLE" ;
VAL_ 778 DAS_roadSignOrientation 2 "HORIZONTAL_3_LIGHT" 1 "VERTICAL_3_LIGHT" 0 "UNKNOWN" ;
VAL_ 781 DAS_meoSolverNumRuns 3 "101_AND_ABOVE" 2 "11_TO_100" 1 "1_TO_10" 0 "0" ;
VAL_ 781 DAS_meoSolverReportTerminationTy 4 "USER_SUCCESS" 3 "USER_FAILURE" 2 "NO_CONVERGENCE" 1 "FAILURE" 0 "CONVERGENCE" ;
VAL_ 781 DAS_meoSolverReportTotalTimeS 6 "0_5_AND_ABOVE" 5 "0_4_TO_0_5" 4 "0_3_TO_0_4" 3 "0_2_TO_0_3" 2 "0_1_TO_0_2" 1 "0_TO_0_1" 0 "0" ;
VAL_ 781 DAS_meoHeadingValid 1 "TRUE" 0 "FALSE" ;
VAL_ 781 DAS_meoGpsQualityLevel 6 "GPS_QUALITY_SUB_LANE" 5 "GPS_QUALITY_LANE" 4 "GPS_QUALITY_ROAD" 3 "GPS_QUALITY_POOR" 2 "GPS_QUALITY_UNKNOWN" 1 "GPS_OUTPUT_UNAVAILABLE" 0 "GPS_NO_COMMUNICATION" ;
VAL_ 781 DAS_meoFixType 5 "TIME_ONLY_FIX" 4 "GNSS_DEAD_RECKONING_COMBINED" 3 "FIX_3D" 2 "FIX_2D" 1 "DEAD_RECKONING_ONLY" 0 "NO_FIX" ;
VAL_ 781 DAS_lastMeoResetReason 3 "EXTRAPOLATION_DEVIATES_FROM_SPP" 2 "SLAM_ANCHOR_NODE_OUT_OF_ORDER" 1 "INITIALIZE_STATE_FROM_CONTEXT_FAILED" 0 "UNKNOWN" ;
VAL_ 781 DAS_vioMultiGpsSelectedSource 5 "SEEDED_ORIGIN" 4 "RELOCALIZATION" 3 "BLUEFIN_SPP_TDCP" 2 "BLUEFIN_MEO" 1 "RAW_GPS" 0 "INVALID" ;
VAL_ 781 DAS_vioMultiGpsPeCooldownActive 1 "TRUE" 0 "FALSE" ;
VAL_ 781 DAS_vioMultiGpsPeSppTdcpConsiste 1 "TRUE" 0 "FALSE" ;
VAL_ 781 DAS_vioMultiGpsPeMeoConsistentWi 1 "TRUE" 0 "FALSE" ;
VAL_ 781 DAS_publishedGpsSource 3 "VIO_MULTI_GPS" 2 "VIO_GEODETIC_POSE" 1 "RAW_GPS_PASSTHROUGH" 0 "INVALID" ;
VAL_ 781 DAS_bluefinEnabled 1 "TRUE" 0 "FALSE" ;
VAL_ 781 DAS_orioleDisabled 1 "TRUE" 0 "FALSE" ;
VAL_ 781 DAS_disableMonarch 1 "TRUE" 0 "FALSE" ;
VAL_ 299 DAS_smartShiftTorqueDirection 4 "SUGGESTED_TORQUE_DIRECTION_NOT_READY" 3 "SUGGESTED_TORQUE_DIRECTION_FORWARD" 2 "SUGGESTED_TORQUE_DIRECTION_REVERSE" 1 "SUGGESTED_TORQUE_DIRECTION_NOT_CONFIDENT" 0 "SUGGESTED_TORQUE_DIRECTION_SNA" ;
VAL_ 299 DAS_smartShiftTorqueReason 15 "SUGGESTED_TORQUE_REASON_FSD_E2E" 14 "SUGGESTED_TORQUE_REASON_PERP_PARKING" 13 "SUGGESTED_TORQUE_REASON_PLL_PARKING" 12 "SUGGESTED_TORQUE_REASON_BLOCKING_VEHICLE" 11 "SUGGESTED_TORQUE_REASON_STATIC_OBSTACLE" 10 "SUGGESTED_TORQUE_REASON_CURB" 9 "SUGGESTED_TORQUE_REASON_RETRACE" 8 "SUGGESTED_TORQUE_REASON_PLL_TO_ROAD_SUBS_SHFT" 7 "SUGGESTED_TORQUE_REASON_PLL_TO_ROAD_1ST_SHFT" 6 "SUGGESTED_TORQUE_REASON_CIPV" 5 "SUGGESTED_TORQUE_REASON_GATE" 4 "SUGGESTED_TORQUE_REASON_ROAD_MARKING" 3 "SUGGESTED_TORQUE_REASON_SMART_SUMMON_SHORT_PLAN" 2 "SUGGESTED_TORQUE_REASON_SMART_SUMMON_PLAN" 1 "SUGGESTED_TORQUE_REASON_SMART_SHIFT_PLAN" 0 "SUGGESTED_TORQUE_REASON_SNA" ;
VAL_ 299 DAS_autoshiftTorqueDirectionDbg 4 "SUGGESTED_TORQUE_DIRECTION_NOT_READY" 3 "SUGGESTED_TORQUE_DIRECTION_FORWARD" 2 "SUGGESTED_TORQUE_DIRECTION_REVERSE" 1 "SUGGESTED_TORQUE_DIRECTION_NOT_CONFIDENT" 0 "SUGGESTED_TORQUE_DIRECTION_SNA" ;
VAL_ 299 DAS_autoshiftUpcomingDirection 3 "AUTOSHIFT_DIRECTION_SNA" 2 "AUTOSHIFT_DIRECTION_DRIVE" 1 "AUTOSHIFT_DIRECTION_REVERSE" 0 "AUTOSHIFT_DIRECTION_NONE" ;
VAL_ 299 DAS_autoshiftSteerRequest 3 "AUTOSHIFT_STEERING_DIRECTION_LEFT" 2 "AUTOSHIFT_STEERING_DIRECTION_RIGHT" 1 "AUTOSHIFT_STEERING_DIRECTION_ANY" 0 "AUTOSHIFT_STEERING_DIRECTION_NONE" ;
VAL_ 921 DAS_autopilotState 14 "FAULT" 9 "ABORTED" 8 "ABORTING" 6 "ACTIVE_FSD" 5 "ACTIVE_NAV" 4 "ACTIVE_RESTRICTED" 3 "ACTIVE_NOMINAL" 2 "AVAILABLE" 1 "UNAVAILABLE" 0 "DISABLED" ;
VAL_ 921 DAS_blindSpotRearLeft 2 "WARNING_LEVEL_2" 1 "WARNING_LEVEL_1" 0 "NO_WARNING" ;
VAL_ 921 DAS_blindSpotRearRight 2 "WARNING_LEVEL_2" 1 "WARNING_LEVEL_1" 0 "NO_WARNING" ;
VAL_ 921 DAS_suppressSpeedWarning 1 "Suppress_Speed_Warning" 0 "Do_Not_Suppress" ;
VAL_ 921 DAS_heaterState 1 "HEATER_ON" 0 "HEATER_OFF_SNA" ;
VAL_ 921 DAS_forwardCollisionWarning 1 "FORWARD_COLLISION_WARNING" 0 "NONE" ;
VAL_ 921 DAS_autoparkReady 1 "AUTOPARK_READY" 0 "AUTOPARK_UNAVAILABLE" ;
VAL_ 921 DAS_lssState 7 "LSS_STATE_OFF" 6 "LSS_STATE_ABORT" 5 "LSS_STATE_BLINDSPOT" 4 "LSS_STATE_MONITOR" 3 "LSS_STATE_ELK" 2 "LSS_STATE_LKA" 1 "LSS_STATE_LDW" 0 "LSS_STATE_FAULT" ;
VAL_ 921 DAS_sideCollisionAvoid 2 "AVOID_RIGHT" 1 "AVOID_LEFT" 0 "NONE" ;
VAL_ 921 DAS_sideCollisionWarning 3 "WARN_LEFT_RIGHT" 2 "WARN_RIGHT" 1 "WARN_LEFT" 0 "NONE" ;
VAL_ 921 DAS_sideCollisionInhibit 1 "INHIBIT" 0 "NO_INHIBIT" ;
VAL_ 921 DAS_laneDepartureWarning 4 "RIGHT_WARNING_SEVERE" 3 "LEFT_WARNING_SEVERE" 2 "RIGHT_WARNING" 1 "LEFT_WARNING" 0 "NONE" ;
VAL_ 921 DAS_fleetSpeedState 3 "FLEETSPEED_HOLD" 2 "FLEETSPEED_ACTIVE" 1 "FLEETSPEED_AVAILABLE" 0 "FLEETSPEED_UNAVAILABLE" ;
VAL_ 921 DAS_autopilotHandsOnState 15 "LC_HANDS_ON_SNA" 10 "LC_HANDS_ON_REQD_ESCALATED_CHIME_2" 9 "LC_HANDS_ON_REQD_ESCALATED_CHIME_1" 8 "LC_HANDS_ON_SUSPENDED" 7 "LC_HANDS_ON_REQD_STRUCK_OUT" 6 "LC_HANDS_ON_REQD_SLOWING" 5 "LC_HANDS_ON_REQD_CHIME_2" 4 "LC_HANDS_ON_REQD_CHIME_1" 3 "LC_HANDS_ON_REQD_VISUAL" 2 "LC_HANDS_ON_REQD_NOT_DETECTED" 1 "LC_HANDS_ON_REQD_DETECTED" 0 "LC_HANDS_ON_NOT_REQD" ;
VAL_ 921 DAS_autoLaneChangeState 31 "ALC_SNA" 30 "ALC_ABORT_MISSION_PLAN_INVALID" 29 "ALC_ABORT_TIMEOUT" 28 "ALC_WAITING_HANDS_ON" 27 "ALC_BLOCKED_LANE_TYPE_R" 26 "ALC_BLOCKED_LANE_TYPE_L" 25 "ALC_BLOCKED_VEH_TTC_AND_USS_R" 24 "ALC_BLOCKED_VEH_TTC_R" 23 "ALC_BLOCKED_VEH_TTC_AND_USS_L" 22 "ALC_BLOCKED_VEH_TTC_L" 21 "ALC_UNAVAILABLE_SOLID_LANE_LINE" 20 "ALC_ABORT_OTHER_REASON" 19 "ALC_ABORT_BLINKER_TURNED_OFF" 18 "ALC_ABORT_LC_HEALTH_BAD" 17 "ALC_ABORT_POOR_VIEW_RANGE" 16 "ALC_ABORT_SIDE_OBSTACLE_PRESENT_R" 15 "ALC_ABORT_SIDE_OBSTACLE_PRESENT_L" 14 "ALC_WAITING_FOR_FWD_OBST_TO_PASS_R" 13 "ALC_WAITING_FOR_FWD_OBST_TO_PASS_L" 12 "ALC_WAITING_FOR_SIDE_OBST_TO_PASS_R" 11 "ALC_WAITING_FOR_SIDE_OBST_TO_PASS_L" 10 "ALC_IN_PROGRESS_R" 9 "ALC_IN_PROGRESS_L" 8 "ALC_AVAILABLE_BOTH" 7 "ALC_AVAILABLE_ONLY_R" 6 "ALC_AVAILABLE_ONLY_L" 5 "ALC_UNAVAILABLE_VEHICLE_SPEED" 4 "ALC_UNAVAILABLE_EXITING_HIGHWAY" 3 "ALC_UNAVAILABLE_TP_FOLLOW" 2 "ALC_UNAVAILABLE_SONICS_INVALID" 1 "ALC_UNAVAILABLE_NO_LANES" 0 "ALC_UNAVAILABLE_DISABLED" ;
VAL_ 905 DAS_pmmObstacleSeverity 7 "PMM_SNA" 6 "PMM_ACCEL_LIMIT" 5 "PMM_CRASH_FRONT" 4 "PMM_CRASH_REAR" 3 "PMM_BRAKE_REQUEST" 2 "PMM_IMMINENT_FRONT" 1 "PMM_IMMINENT_REAR" 0 "PMM_NONE" ;
VAL_ 905 DAS_pmmLoggingRequest 1 "TRUE" 0 "FALSE" ;
VAL_ 905 DAS_activationFailureStatus 2 "LC_ACTIVATION_FAILED_2" 1 "LC_ACTIVATION_FAILED_1" 0 "LC_ACTIVATION_IDLE" ;
VAL_ 905 DAS_pmmUltrasonicsFaultReason 4 "PMM_ULTRASONICS_INVALID_MIA" 3 "PMM_ULTRASONICS_BLOCKED_BOTH" 2 "PMM_ULTRASONICS_BLOCKED_REAR" 1 "PMM_ULTRASONICS_BLOCKED_FRONT" 0 "PMM_ULTRASONICS_NO_FAULT" ;
VAL_ 905 DAS_pmmRadarFaultReason 2 "PMM_RADAR_INVALID_MIA" 1 "PMM_RADAR_BLOCKED_FRONT" 0 "PMM_RADAR_NO_FAULT" ;
VAL_ 905 DAS_pmmSysFaultReason 7 "PMM_FAULT_BRAKE_PEDAL_INHIBIT" 6 "PMM_FAULT_ROAD_TYPE" 5 "PMM_FAULT_DISABLED_BY_USER" 4 "PMM_FAULT_STEERING_ANGLE_RATE" 3 "PMM_FAULT_DI_FAULT" 2 "PMM_FAULT_SPEED" 1 "PMM_FAULT_DAS_DISABLED" 0 "PMM_FAULT_NONE" ;
VAL_ 905 DAS_pmmCameraFaultReason 2 "PMM_CAMERA_INVALID_MIA" 1 "PMM_CAMERA_BLOCKED_FRONT" 0 "PMM_CAMERA_NO_FAULT" ;
VAL_ 905 DAS_ACC_report 24 "ACC_REPORT_BEHAVIOR_REPORT" 23 "ACC_REPORT_CAMERA_ONLY" 22 "ACC_REPORT_RADAR_OBJ_FIVE" 21 "ACC_REPORT_CIPV_CUTTING_OUT" 20 "ACC_REPORT_MCVLR_IN_PATH" 19 "ACC_REPORT_MCVLR_DPP" 18 "ACC_REPORT_FLEET_SPEEDS" 17 "ACC_REPORT_TARGET_MCP" 16 "ACC_REPORT_RADAR_OBJ_TWO" 15 "ACC_REPORT_RADAR_OBJ_ONE" 14 "ACC_REPORT_LC_EXTERNAL_STATE_ACTIVE_RESTRICTED" 13 "ACC_REPORT_LC_EXTERNAL_STATE_ABORTED" 12 "ACC_REPORT_LC_EXTERNAL_STATE_ABORTING" 11 "ACC_REPORT_LC_HANDS_ON_REQD_STRUCK_OUT" 10 "ACC_REPORT_CSA" 9 "ACC_REPORT_TARGET_TYPE_FAULT" 8 "ACC_REPORT_TARGET_TYPE_IPSO" 7 "ACC_REPORT_TARGET_TYPE_TRAFFIC_LIGHT" 6 "ACC_REPORT_TARGET_TYPE_STOP_SIGN" 5 "ACC_REPORT_TARGET_CUTIN" 4 "ACC_REPORT_TARGET_MCVR" 3 "ACC_REPORT_TARGET_MCVL" 2 "ACC_REPORT_TARGET_IN_FRONT_OF_CIPV" 1 "ACC_REPORT_TARGET_CIPV" 0 "ACC_REPORT_TARGET_NONE" ;
VAL_ 905 DAS_csaState 3 "CSA_EXTERNAL_STATE_HOLD" 2 "CSA_EXTERNAL_STATE_ENABLE" 1 "CSA_EXTERNAL_STATE_AVAILABLE" 0 "CSA_EXTERNAL_STATE_UNAVAILABLE" ;
VAL_ 905 DAS_radarTelemetry 2 "RADAR_TELEMETRY_URGENT" 1 "RADAR_TELEMETRY_NORMAL" 0 "RADAR_TELEMETRY_IDLE" ;
VAL_ 905 DAS_robState 3 "ROB_STATE_MAPLESS" 2 "ROB_STATE_ACTIVE" 1 "ROB_STATE_MEASURE" 0 "ROB_STATE_INHIBITED" ;
VAL_ 905 DAS_driverInteractionLevel 2 "CONTINUED_DRIVER_NOT_INTERACTING" 1 "DRIVER_NOT_INTERACTING" 0 "DRIVER_INTERACTING" ;
VAL_ 905 DAS_longCollisionWarning 15 "FCM_LONG_COLLISION_WARNING_SNA" 12 "FCM_LONG_COLLISION_WARNING_VEHICLE_CIPV2" 11 "FCM_LONG_COLLISION_WARNING_VEHICLE_MCVR2" 10 "FCM_LONG_COLLISION_WARNING_VEHICLE_MCVR" 9 "FCM_LONG_COLLISION_WARNING_VEHICLE_MCVL2" 8 "FCM_LONG_COLLISION_WARNING_VEHICLE_MCVL" 7 "FCM_LONG_COLLISION_WARNING_VEHICLE_CUTIN" 6 "FCM_LONG_COLLISION_WARNING_VEHICLE_CIPV" 5 "FCM_LONG_COLLISION_WARNING_TFL_STOPLINE" 4 "FCM_LONG_COLLISION_WARNING_STOPSIGN_STOPLINE" 3 "FCM_LONG_COLLISION_WARNING_IPSO" 2 "FCM_LONG_COLLISION_WARNING_PEDESTRIAN" 1 "FCM_LONG_COLLISION_WARNING_VEHICLE_UNKNOWN" 0 "FCM_LONG_COLLISION_WARNING_NONE" ;
VAL_ 1548 DAS_TR_Obj00_Class 4 "RADAR_CLASS_CONSTRUCTION_ELEMENT" 3 "RADAR_CLASS_MOVING_PEDESTRIAN" 2 "RADAR_CLASS_MOVING_TWO_WHEEL_VEHICLE" 1 "RADAR_CLASS_MOVING_FOUR_WHEEL_VEHICLE" 0 "RADAR_CLASS_UNKNOWN" ;
VAL_ 1548 DAS_TR_Obj00_MovingState 3 "RADAR_MOVESTATE_STANDING" 2 "RADAR_MOVESTATE_STOPPED" 1 "RADAR_MOVESTATE_MOVING" 0 "RADAR_MOVESTATE_INDETERMINATE" ;
VAL_ 586 DAS_autosteerVehiclesUsage 3 "BLACKLISTED" 2 "FUSED" 1 "AVAILABLE" 0 "REJECTED_UNAVAILABLE" ;
VAL_ 586 DAS_autosteerHPPUsage 3 "BLACKLISTED" 2 "FUSED" 1 "AVAILABLE" 0 "REJECTED_UNAVAILABLE" ;
VAL_ 586 DAS_autosteerNavigationUsage 3 "BLACKLISTED" 2 "FUSED" 1 "AVAILABLE" 0 "REJECTED_UNAVAILABLE" ;
VAL_ 586 DAS_autosteerModelUsage 3 "BLACKLISTED" 2 "FUSED" 1 "AVAILABLE" 0 "REJECTED_UNAVAILABLE" ;
VAL_ 586 DAS_autosteerBottsDotsUsage 3 "BLACKLISTED" 2 "FUSED" 1 "AVAILABLE" 0 "REJECTED_UNAVAILABLE" ;
VAL_ 586 DAS_offsetSide 3 "OFFSET_BOTH_OBJECTS" 2 "OFFSET_LEFT_OBJECT" 1 "OFFSET_RIGHT_OBJECT" 0 "NO_OFFSET" ;
VAL_ 586 DAS_roadSurfaceType 2 "ROAD_SURFACE_ENHANCED" 1 "ROAD_SURFACE_NORMAL" 0 "ROAD_SURFACE_SNA" ;
VAL_ 586 DAS_autosteerHealthState 5 "HEALTH_FAULT" 4 "HEALTH_ABORTING" 3 "HEALTH_SEVERELY_DEGRADED" 2 "HEALTH_DEGRADED" 1 "HEALTH_NOMINAL" 0 "HEALTH_UNAVAILABLE" ;
VAL_ 586 DAS_lastLinePreferenceReason 15 "NONE" 5 "COUNTRY_DRIVING_SIDE" 4 "AVOID_ONCOMING_LANES" 3 "NAVIGATION_BRANCH" 2 "NEIGHBOR_LANE_PROBABILIY" 1 "AGREEMENT_WITH_NEIGHBOR_LANES" 0 "OTHER_LANE_DISAGREES_WITH_MODEL" ;
VAL_ 586 DAS_plannerState 7 "TP_EXTSTATE_LANECHANGE_ABORT" 6 "TP_EXTSTATE_LANECHANGE_WAIT_FOR_FWD_OBSTACLE" 5 "TP_EXTSTATE_LANECHANGE_WAIT_FOR_SIDE_OBSTACLE" 4 "TP_EXTSTATE_LANECHANGE_IN_PROGRESS" 3 "TP_EXTSTATE_LANECHANGE_REQUESTED" 2 "TP_EXTSTATE_FOLLOW" 1 "TP_EXTSTATE_VL" 0 "TP_EXTSTATE_DISABLED" ;
VAL_ 586 DAS_lastAutosteerAbortReason 36 "UI_ABORT_REASON_AHB_MANUAL_OVERRIDE" 35 "UI_ABORT_REASON_DRIVER_NOT_PRESENT" 34 "UI_ABORT_REASON_USER_OVERRIDE_STRIKEOUT" 33 "UI_ABORT_REASON_SEATBELT_UNBUCKLED" 32 "UI_ABORT_REASON_AEB" 31 "UI_ABORT_REASON_NO_ABORT" 30 "UI_ABORT_REASON_CAMERA_FAILSAFES" 29 "UI_ABORT_REASON_ACC_CANCEL" 28 "UI_ABORT_REASON_EPAS_ERROR_CODE" 27 "UI_ABORT_REASON_PLANNER_OUTPUT_INVALID" 26 "UI_ABORT_REASON_FOLLOWER_OUTPUT_INVALID" 25 "UI_ABORT_REASON_VEHICLE_SPEED_ABOVE_MAX" 24 "UI_ABORT_REASON_DRIVING_OFF_NAV" 23 "UI_ABORT_REASON_CID_SWITCH_DISABLED" 22 "UI_ABORT_REASON_CRUISE_FAULT" 21 "UI_ABORT_REASON_COMPONENT_MIA" 20 "UI_ABORT_REASON_EPAS_EAC_DENIED" 19 "UI_ABORT_REASON_SIDE_COLLISION_IMMINENT" 18 "UI_ABORT_REASON_TRAILER_MODE" 17 "UI_ABORT_REASON_CAM_WATCHDOG" 16 "UI_ABORT_REASON_CAM_MSG_MIA" 15 "UI_ABORT_REASON_ME_MAIN_STATE_NOT_VISION" 14 "UI_ABORT_REASON_APP_ME_STATE_NOT_VISION" 2 "UI_ABORT_REASON_HM_STEERING_ERROR" 1 "UI_ABORT_REASON_HM_VIRTUAL_LANE_NO_INPUTS" 0 "UI_ABORT_REASON_HM_LANE_VIEW_RANGE" ;
VAL_ 586 DAS_navAvailable 1 "DAS_NAV_AVAILABLE" 0 "DAS_NAV_UNAVAILABLE" ;
VAL_ 586 DAS_accSmartSpeedState 5 "OFFRAMP_DELAY" 4 "SET_SPEED_SET_REQUESTED" 3 "ACTIVE_ONRAMP" 2 "ACTIVE_INTEGRATING" 1 "ACTIVE_OFFRAMP" 0 "NOT_ACTIVE" ;
VAL_ 586 DAS_ulcInProgress 1 "ULC_ACTIVE" 0 "ULC_INACTIVE" ;
VAL_ 586 DAS_isaSystemState 3 "ISA_UNAVAILABLE" 2 "ISA_INVALID" 1 "ISA_ASSUMED_LIMITS" 0 "ISA_NOMINAL" ;
VAL_ 586 DAS_behaviorType 3 "DAS_BEHAVIOR_LANE_CHANGE_RIGHT" 2 "DAS_BEHAVIOR_LANE_CHANGE_LEFT" 1 "DAS_BEHAVIOR_IN_LANE" 0 "DAS_BEHAVIOR_INVALID" ;
VAL_ 586 DAS_ulcType 2 "ULC_TYPE_SPEED" 1 "ULC_TYPE_NAV" 0 "ULC_TYPE_NONE" ;
VAL_ 586 DAS_rearVehDetectedThisCycle 1 "VEHICLE_DETECTED" 0 "VEHICLE_NOT_DETECTED" ;
VAL_ 586 DAS_rearLeftVehDetectedCurrent 1 "VEHICLE_DETECTED" 0 "VEHICLE_NOT_DETECTED" ;
VAL_ 586 DAS_rearRightVehDetectedTrip 1 "VEHICLE_DETECTED" 0 "VEHICLE_NOT_DETECTED" ;
VAL_ 586 DAS_rearLeftVehDetectedTrip 1 "VEHICLE_DETECTED" 0 "VEHICLE_NOT_DETECTED" ;
